VERSION "HNNBNNNYNNNNNNNNNNNNNNNNNNNNNNNNNNNNNNNNNN/4/%%%/4/'%**4NNN///"

NS_ :

BS_:

BU_: BAP_Tester ELV Gateway_Max HUD Kombi

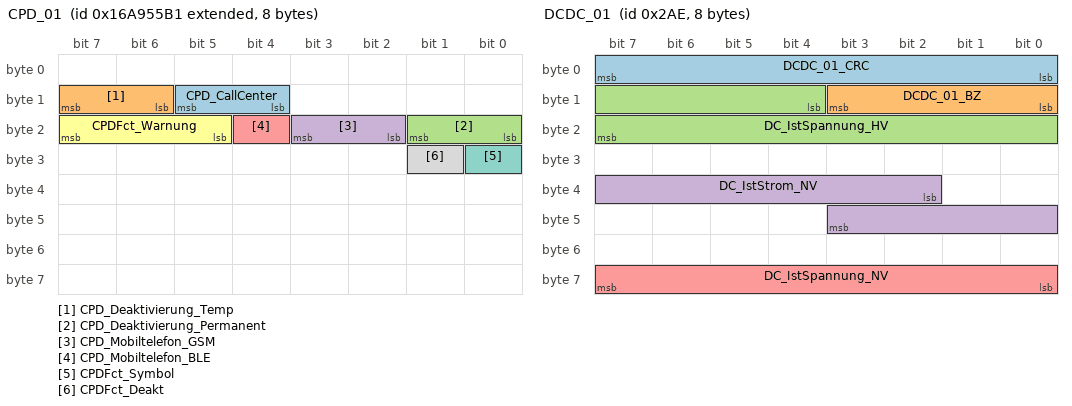
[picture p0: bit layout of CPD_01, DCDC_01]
BO_ 2527679921 CPD_01: 8 Gateway_Max
 SG_ CPD_CallCenter : 12|2@1+ (1.0,0.0) [0.0|3] ""  Vector__XXX
 SG_ CPD_Deaktivierung_Temp : 14|2@1+ (1.0,0.0) [0.0|3] ""  Vector__XXX
 SG_ CPD_Deaktivierung_Permanent : 16|2@1+ (1.0,0.0) [0.0|3] ""  Vector__XXX
 SG_ CPD_Mobiltelefon_GSM : 18|2@1+ (1.0,0.0) [0.0|3] ""  Vector__XXX
 SG_ CPD_Mobiltelefon_BLE : 20|1@1+ (1.0,0.0) [0.0|1] ""  Vector__XXX
 SG_ CPDFct_Warnung : 21|3@1+ (1.0,0.0) [0.0|7] ""  Kombi
 SG_ CPDFct_Symbol : 24|1@1+ (1.0,0.0) [0.0|1] ""  Kombi
 SG_ CPDFct_Deakt : 25|1@1+ (1.0,0.0) [0.0|1] ""  Vector__XXX

BO_ 918 Daempfer_01: 8 Gateway_Max
 SG_ DR_Gelbe_Warnlampe : 18|2@1+ (1.0,0.0) [0.0|3] ""  Kombi

BO_ 686 DCDC_01: 8 Gateway_Max
 SG_ DCDC_01_CRC : 0|8@1+ (1,0) [0|255] ""  Vector__XXX
 SG_ DCDC_01_BZ : 8|4@1+ (1,0) [0|15] ""  Vector__XXX
 SG_ DC_IstSpannung_HV : 12|12@1+ (0.25,0) [0.00|1023.25] "Unit_Volt"  Vector__XXX
 SG_ DC_IstStrom_NV : 34|10@1+ (1,-511) [-511|510] "Unit_Amper"  Vector__XXX
 SG_ DC_IstSpannung_NV : 56|8@1+ (0.1,0) [0.0|25.3] "Unit_Volt"  Vector__XXX

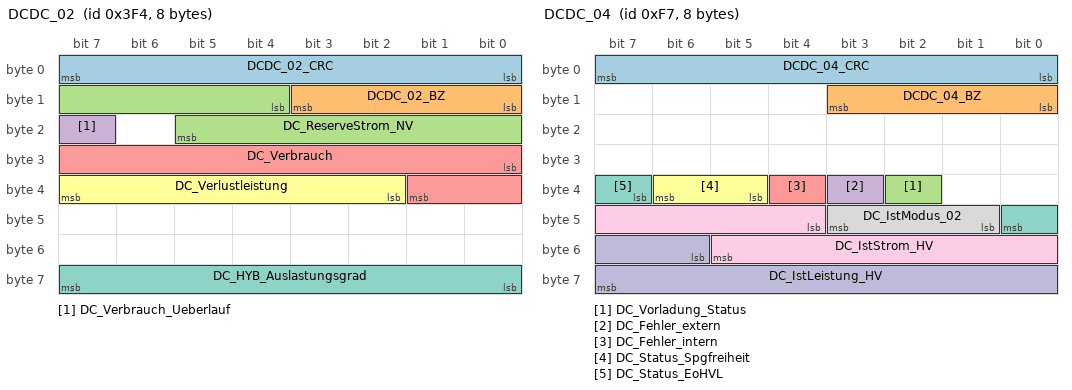
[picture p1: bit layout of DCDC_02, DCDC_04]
BO_ 1012 DCDC_02: 8 Gateway_Max
 SG_ DCDC_02_CRC : 0|8@1+ (1,0) [0|255] ""  Vector__XXX
 SG_ DCDC_02_BZ : 8|4@1+ (1,0) [0|15] ""  Vector__XXX
 SG_ DC_ReserveStrom_NV : 12|10@1+ (1,-511) [-511|510] "Unit_Amper"  Vector__XXX
 SG_ DC_Verbrauch_Ueberlauf : 23|1@1+ (1.0,0.0) [0.0|1] ""  Kombi
 SG_ DC_Verbrauch : 24|10@1+ (1,0) [0|1023] "Unit_WattSecond"  Kombi
 SG_ DC_Verlustleistung : 34|6@1+ (5,0) [0|305] "Unit_Watt"  Vector__XXX
 SG_ DC_HYB_Auslastungsgrad : 56|8@1+ (0.4,0) [0.0|100.0] "Unit_PerCent"  Vector__XXX

BO_ 247 DCDC_04: 8 Gateway_Max
 SG_ DCDC_04_CRC : 0|8@1+ (1,0) [0|255] ""  Vector__XXX
 SG_ DCDC_04_BZ : 8|4@1+ (1,0) [0|15] ""  Vector__XXX
 SG_ DC_Vorladung_Status : 34|1@1+ (1.0,0.0) [0.0|1] ""  Vector__XXX
 SG_ DC_Fehler_extern : 35|1@1+ (1.0,0.0) [0.0|1] ""  Vector__XXX
 SG_ DC_Fehler_intern : 36|1@1+ (1.0,0.0) [0.0|1] ""  Vector__XXX
 SG_ DC_Status_Spgfreiheit : 37|2@1+ (1.0,0.0) [0.0|3] ""  Vector__XXX
 SG_ DC_Status_EoHVL : 39|2@1+ (1.0,0.0) [0.0|3] ""  Vector__XXX
 SG_ DC_IstModus_02 : 41|3@1+ (1.0,0.0) [0.0|7] ""  Vector__XXX
 SG_ DC_IstStrom_HV : 44|10@1+ (0.1,-51.1) [-51.1|51.0] "Unit_Amper"  Vector__XXX
 SG_ DC_IstLeistung_HV : 54|10@1+ (10,-4000) [-4000|6210] "Unit_Watt"  Vector__XXX

BO_ 2583738904 DDA_AuthTime_Req: 8 Gateway_Max
 SG_ DDA_AuthTime_Req_Data : 0|64@1+ (1.0,0.0) [0.0|18446744073709551615] ""  Kombi

BO_ 2583869976 DDA_AuthTime_Resp: 8 Kombi
 SG_ DDA_AuthTime_Resp_Data : 0|64@1+ (1.0,0.0) [0.0|18446744073709551615] ""  Gateway_Max

BO_ 2617084421 DEV_ELV_Req_00: 8 Vector__XXX
 SG_ DEV_ELV_Req_00_Data : 0|64@1+ (1.0,0.0) [0.0|18446744073709551615] ""  ELV

BO_ 2617084427 DEV_ELV_Req_01: 8 Vector__XXX
 SG_ DEV_ELV_Req_01_Data : 0|64@1+ (1.0,0.0) [0.0|18446744073709551615] ""  ELV

BO_ 2617084416 DEV_ELV_Resp_00: 8 ELV
 SG_ DEV_ELV_Resp_00_Data : 0|64@1+ (1.0,0.0) [0.0|18446744073709551615] ""  Vector__XXX

BO_ 2617084417 DEV_ELV_Resp_01: 8 ELV
 SG_ DEV_ELV_Resp_01_Data : 0|64@1+ (1.0,0.0) [0.0|18446744073709551615] ""  Vector__XXX

BO_ 2617084418 DEV_ELV_Resp_02: 8 ELV
 SG_ DEV_ELV_Resp_02_Data : 0|64@1+ (1.0,0.0) [0.0|18446744073709551615] ""  Vector__XXX

BO_ 2617084419 DEV_ELV_Resp_03: 8 ELV
 SG_ DEV_ELV_Resp_03_Data : 0|64@1+ (1.0,0.0) [0.0|18446744073709551615] ""  Vector__XXX

BO_ 2617084420 DEV_ELV_Resp_04: 8 ELV
 SG_ DEV_ELV_Resp_04_Data : 0|64@1+ (1.0,0.0) [0.0|18446744073709551615] ""  Vector__XXX

BO_ 2617084422 DEV_ELV_Resp_05: 8 ELV
 SG_ DEV_ELV_Resp_05_Data : 0|64@1+ (1.0,0.0) [0.0|18446744073709551615] ""  Vector__XXX

BO_ 2617084423 DEV_ELV_Resp_06: 8 ELV
 SG_ DEV_ELV_Resp_06_Data : 0|64@1+ (1.0,0.0) [0.0|18446744073709551615] ""  Vector__XXX

BO_ 2617084424 DEV_ELV_Resp_07: 8 ELV
 SG_ DEV_ELV_Resp_07_Data : 0|64@1+ (1.0,0.0) [0.0|18446744073709551615] ""  Vector__XXX

BO_ 2617084425 DEV_ELV_Resp_08: 8 ELV
 SG_ DEV_ELV_Resp_08_Data : 0|64@1+ (1.0,0.0) [0.0|18446744073709551615] ""  Vector__XXX

BO_ 2617084426 DEV_ELV_Resp_09: 8 ELV
 SG_ DEV_ELV_Resp_09_Data : 0|64@1+ (1.0,0.0) [0.0|18446744073709551615] ""  Vector__XXX

BO_ 2617084428 DEV_ELV_Resp_10: 8 ELV
 SG_ DEV_ELV_Resp_10_Data : 0|64@1+ (1.0,0.0) [0.0|18446744073709551615] ""  Vector__XXX

BO_ 2617039369 DEV_HUD_Rx_09: 8 Vector__XXX
 SG_ DEV_HUD_Rx_09_Data : 0|64@1+ (1.0,0.0) [0.0|18446744073709551615] ""  HUD

BO_ 2617039370 DEV_HUD_Rx_10: 8 Vector__XXX
 SG_ DEV_HUD_Rx_10_Data : 0|64@1+ (1.0,0.0) [0.0|18446744073709551615] ""  HUD

BO_ 2617039371 DEV_HUD_Rx_11: 8 Vector__XXX
 SG_ DEV_HUD_Rx_11_Data : 0|64@1+ (1.0,0.0) [0.0|18446744073709551615] ""  HUD

BO_ 2617039372 DEV_HUD_Rx_12: 8 Vector__XXX
 SG_ DEV_HUD_Rx_12_Data : 0|64@1+ (1.0,0.0) [0.0|18446744073709551615] ""  HUD

BO_ 2617039375 DEV_HUD_Rx_15: 8 Vector__XXX
 SG_ DEV_HUD_Rx_15_Data : 0|64@1+ (1.0,0.0) [0.0|18446744073709551615] ""  HUD

BO_ 2617039361 DEV_HUD_Tx_01: 8 HUD
 SG_ DEV_HUD_Tx_01_Data : 0|64@1+ (1.0,0.0) [0.0|18446744073709551615] ""  Vector__XXX

BO_ 2617039362 DEV_HUD_Tx_02: 8 HUD
 SG_ DEV_HUD_Tx_02_Data : 0|64@1+ (1.0,0.0) [0.0|18446744073709551615] ""  Vector__XXX

BO_ 2617039363 DEV_HUD_Tx_03: 8 HUD
 SG_ DEV_HUD_Tx_03_Data : 0|64@1+ (1.0,0.0) [0.0|18446744073709551615] ""  Vector__XXX

BO_ 2617039364 DEV_HUD_Tx_04: 8 HUD
 SG_ DEV_HUD_Tx_04_Data : 0|64@1+ (1.0,0.0) [0.0|18446744073709551615] ""  Vector__XXX

BO_ 2617039365 DEV_HUD_Tx_05: 8 HUD
 SG_ DEV_HUD_Tx_05_Data : 0|64@1+ (1.0,0.0) [0.0|18446744073709551615] ""  Vector__XXX

BO_ 2617039366 DEV_HUD_Tx_06: 8 HUD
 SG_ DEV_HUD_Tx_06_Data : 0|64@1+ (1.0,0.0) [0.0|18446744073709551615] ""  Vector__XXX

BO_ 2617039367 DEV_HUD_Tx_07: 8 HUD
 SG_ DEV_HUD_Tx_07_Data : 0|64@1+ (1.0,0.0) [0.0|18446744073709551615] ""  Vector__XXX

BO_ 2617039368 DEV_HUD_Tx_08: 8 HUD
 SG_ DEV_HUD_Tx_08_Data : 0|64@1+ (1.0,0.0) [0.0|18446744073709551615] ""  Vector__XXX

BO_ 2617039373 DEV_HUD_Tx_13: 8 HUD
 SG_ DEV_HUD_Tx_13_Data : 0|64@1+ (1.0,0.0) [0.0|18446744073709551615] ""  Vector__XXX

BO_ 2617039374 DEV_HUD_Tx_14: 8 HUD
 SG_ DEV_HUD_Tx_14_Data : 0|64@1+ (1.0,0.0) [0.0|18446744073709551615] ""  Vector__XXX

BO_ 2617039376 DEV_HUD_Tx_16: 8 HUD
 SG_ DEV_HUD_Tx_16_Data : 0|64@1+ (1.0,0.0) [0.0|18446744073709551615] ""  Vector__XXX

BO_ 2549880335 DIA_ABT_2_Req: 8 Gateway_Max
 SG_ DIA_ABT_2_Req_Data : 0|64@1+ (1.0,0.0) [0.0|18446744073709551615] ""  Vector__XXX

BO_ 2550011407 DIA_ABT_2_Resp: 8 Vector__XXX
 SG_ DIA_ABT_2_Resp_Data : 0|64@1+ (1.0,0.0) [0.0|18446744073709551615] ""  Gateway_Max

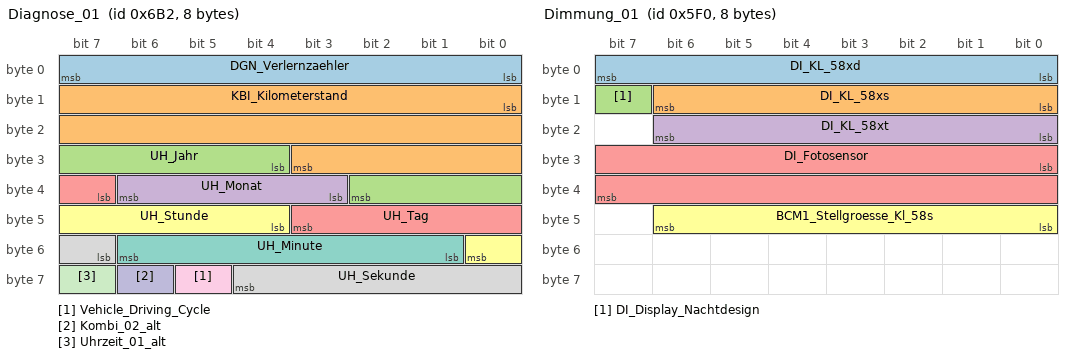
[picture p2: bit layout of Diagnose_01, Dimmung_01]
BO_ 1714 Diagnose_01: 8 Gateway_Max
 SG_ DGN_Verlernzaehler : 0|8@1+ (1,0) [0|254] ""  ELV,HUD,Kombi
 SG_ KBI_Kilometerstand : 8|20@1+ (1,0) [0|1048573] "Unit_KiloMeter"  ELV,HUD,Kombi
 SG_ UH_Jahr : 28|7@1+ (1,2000) [2000|2127] "Unit_Year"  ELV,HUD,Kombi
 SG_ UH_Monat : 35|4@1+ (1,0) [1|12] "Unit_Month"  ELV,HUD,Kombi
 SG_ UH_Tag : 39|5@1+ (1,0) [1|31] "Unit_Day"  ELV,HUD,Kombi
 SG_ UH_Stunde : 44|5@1+ (1,0) [0|23] "Unit_Hours"  ELV,HUD,Kombi
 SG_ UH_Minute : 49|6@1+ (1,0) [0|59] "Unit_Minut"  ELV,HUD,Kombi
 SG_ UH_Sekunde : 55|6@1+ (1,0) [0|59] "Unit_Secon"  ELV,HUD,Kombi
 SG_ Vehicle_Driving_Cycle : 61|1@1+ (1.0,0.0) [0.0|1] ""  Vector__XXX
 SG_ Kombi_02_alt : 62|1@1+ (1.0,0.0) [0.0|1] ""  Vector__XXX
 SG_ Uhrzeit_01_alt : 63|1@1+ (1.0,0.0) [0.0|1] ""  Vector__XXX

BO_ 1520 Dimmung_01: 8 Gateway_Max
 SG_ DI_KL_58xd : 0|8@1+ (1,0) [0|253] ""  Kombi
 SG_ DI_KL_58xs : 8|7@1+ (1,0) [0|100] "Unit_PerCent"  Kombi
 SG_ DI_Display_Nachtdesign : 15|1@1+ (1.0,0.0) [0.0|1] ""  HUD,Kombi
 SG_ DI_KL_58xt : 16|7@1+ (1,0) [0|100] "Unit_PerCent"  Kombi
 SG_ DI_Fotosensor : 24|16@1+ (1,0) [0|65535] ""  Vector__XXX
 SG_ BCM1_Stellgroesse_Kl_58s : 40|7@1+ (1,0) [0|100] ""  HUD

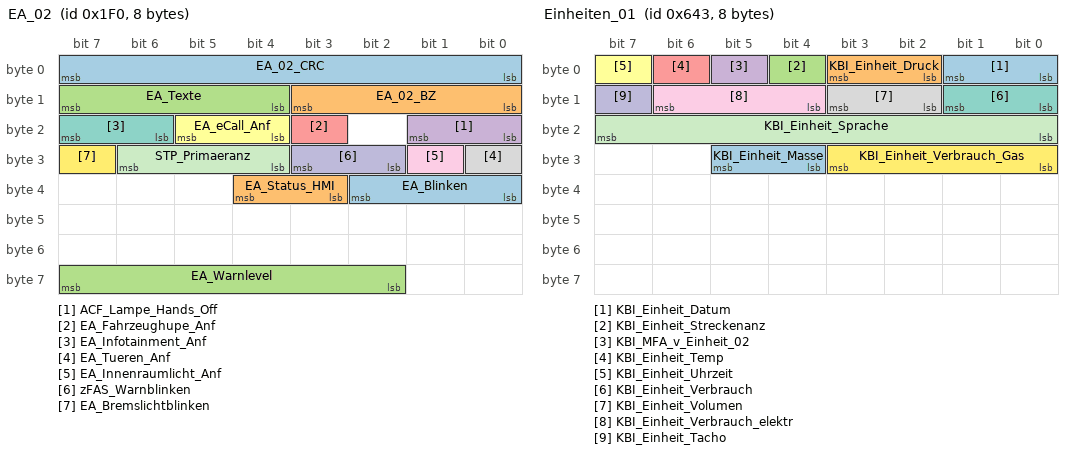
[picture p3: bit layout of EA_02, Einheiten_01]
BO_ 496 EA_02: 8 Gateway_Max
 SG_ EA_02_CRC : 0|8@1+ (1,0) [0|255] ""  Vector__XXX
 SG_ EA_02_BZ : 8|4@1+ (1,0) [0|15] ""  Vector__XXX
 SG_ EA_Texte : 12|4@1+ (1.0,0.0) [0.0|15] ""  HUD,Kombi
 SG_ ACF_Lampe_Hands_Off : 16|2@1+ (1.0,0.0) [0.0|3] ""  Vector__XXX
 SG_ EA_Fahrzeughupe_Anf : 19|1@1+ (1.0,0.0) [0.0|1] ""  Vector__XXX
 SG_ EA_eCall_Anf : 20|2@1+ (1.0,0.0) [0.0|3] ""  Vector__XXX
 SG_ EA_Infotainment_Anf : 22|2@1+ (1.0,0.0) [0.0|3] ""  Vector__XXX
 SG_ EA_Tueren_Anf : 24|1@1+ (1.0,0.0) [0.0|1] ""  Vector__XXX
 SG_ EA_Innenraumlicht_Anf : 25|1@1+ (1.0,0.0) [0.0|1] ""  Vector__XXX
 SG_ zFAS_Warnblinken : 26|2@1+ (1.0,0.0) [0.0|3] ""  Vector__XXX
 SG_ STP_Primaeranz : 28|3@1+ (1.0,0.0) [0.0|7] ""  Vector__XXX
 SG_ EA_Bremslichtblinken : 31|1@1+ (1.0,0.0) [0.0|1] ""  Vector__XXX
 SG_ EA_Blinken : 32|3@1+ (1.0,0.0) [0.0|7] ""  Vector__XXX
 SG_ EA_Status_HMI : 35|2@1+ (1.0,0.0) [0.0|3] ""  HUD,Kombi
 SG_ EA_Warnlevel : 58|6@1+ (1.0,0.0) [0.0|63] ""  Vector__XXX

BO_ 2583717656 eCall_AuthTime_Req: 8 Gateway_Max
 SG_ eCall_AuthTime_Req_Data : 0|64@1+ (1.0,0.0) [0.0|18446744073709551615] ""  Kombi

BO_ 2583848728 eCall_AuthTime_Resp: 8 Kombi
 SG_ eCall_AuthTime_Resp_Data : 0|64@1+ (1.0,0.0) [0.0|18446744073709551615] ""  Gateway_Max

BO_ 1603 Einheiten_01: 8 Kombi
 SG_ KBI_Einheit_Datum : 0|2@1+ (1.0,0.0) [0.0|3] ""  Gateway_Max
 SG_ KBI_Einheit_Druck : 2|2@1+ (1.0,0.0) [0.0|3] ""  Gateway_Max
 SG_ KBI_Einheit_Streckenanz : 4|1@1+ (1.0,0.0) [0.0|1] ""  Gateway_Max
 SG_ KBI_MFA_v_Einheit_02 : 5|1@1+ (1.0,0.0) [0.0|1] ""  Gateway_Max,HUD
 SG_ KBI_Einheit_Temp : 6|1@1+ (1.0,0.0) [0.0|1] ""  Gateway_Max,HUD
 SG_ KBI_Einheit_Uhrzeit : 7|1@1+ (1.0,0.0) [0.0|1] ""  Gateway_Max
 SG_ KBI_Einheit_Verbrauch : 8|2@1+ (1.0,0.0) [0.0|3] ""  Gateway_Max
 SG_ KBI_Einheit_Volumen : 10|2@1+ (1.0,0.0) [0.0|3] ""  Gateway_Max
 SG_ KBI_Einheit_Verbrauch_elektr : 12|3@1+ (1.0,0.0) [0.0|7] ""  Gateway_Max
 SG_ KBI_Einheit_Tacho : 15|1@1+ (1.0,0.0) [0.0|1] ""  Gateway_Max
 SG_ KBI_Einheit_Sprache : 16|8@1+ (1,0) [0|255] ""  Gateway_Max,HUD
 SG_ KBI_Einheit_Verbrauch_Gas : 24|4@1+ (1.0,0.0) [0.0|15] ""  Gateway_Max
 SG_ KBI_Einheit_Masse : 28|2@1+ (1.0,0.0) [0.0|3] ""  Gateway_Max

BO_ 1622 ELV_01: 8 ELV
 SG_ ELV_01_CRC : 0|8@1+ (1,0) [0|255] ""  Gateway_Max
 SG_ ELV_01_BZ : 8|4@1+ (1,0) [0|15] ""  Gateway_Max
 SG_ ELV_Anf_Klemme_S : 12|1@1+ (1.0,0.0) [0.0|1] ""  Gateway_Max
 SG_ ELV_Anf_Klemme_15 : 13|1@1+ (1.0,0.0) [0.0|1] ""  Gateway_Max
 SG_ ELV_Anf_Klemme_50 : 14|1@1+ (1.0,0.0) [0.0|1] ""  Gateway_Max
 SG_ ELV_01_Sendestatus : 15|1@1+ (1.0,0.0) [0.0|1] ""  Gateway_Max
 SG_ ELV_Verriegelt : 16|1@1+ (1.0,0.0) [0.0|1] ""  Gateway_Max,Kombi
 SG_ ELV_Entriegelt : 17|1@1+ (1.0,0.0) [0.0|1] ""  Gateway_Max,Kombi
 SG_ ELV_ZAT_betaetigt : 18|1@1+ (1.0,0.0) [0.0|1] ""  Gateway_Max
 SG_ ELV_Lebenszustand : 19|1@1+ (1.0,0.0) [0.0|1] ""  Gateway_Max
 SG_ ELV_Anlernmodus : 20|1@1+ (1.0,0.0) [0.0|1] ""  Gateway_Max
 SG_ KST_aut_Abschaltung_Zuendung : 21|1@1+ (1.0,0.0) [0.0|1] ""  Gateway_Max
 SG_ ELV_Klemmenfreigabe : 22|1@1+ (1.0,0.0) [0.0|1] ""  Gateway_Max
 SG_ ELV_Abbruch_Anf_Klemmenfreigabe : 23|1@1+ (1.0,0.0) [0.0|1] ""  Gateway_Max
 SG_ ELV_LED_Rot : 24|1@1+ (1.0,0.0) [0.0|1] ""  Gateway_Max,Kombi
 SG_ ELV_LED_Gelb : 25|1@1+ (1.0,0.0) [0.0|1] ""  Gateway_Max
 SG_ ELV_Txt_Panikabschaltung : 27|1@1+ (1.0,0.0) [0.0|1] ""  Gateway_Max
 SG_ ELV_Txt_Lkg_Bewegen : 28|1@1+ (1.0,0.0) [0.0|1] ""  Gateway_Max,Kombi
 SG_ ELV_Txt_Werkstatt : 29|1@1+ (1.0,0.0) [0.0|1] ""  Gateway_Max,Kombi
 SG_ ELV_Txt_Defekt : 30|1@1+ (1.0,0.0) [0.0|1] ""  Gateway_Max,Kombi
 SG_ ELV_Txt_P_Gang : 31|1@1+ (1.0,0.0) [0.0|1] ""  Gateway_Max
 SG_ ELV_Txt_PN_Gang : 32|1@1+ (1.0,0.0) [0.0|1] ""  Gateway_Max
 SG_ ELV_Txt_Kupplung : 33|1@1+ (1.0,0.0) [0.0|1] ""  Gateway_Max
 SG_ ELV_Txt_Bremse : 34|1@1+ (1.0,0.0) [0.0|1] ""  Gateway_Max
 SG_ ELV_P_verriegelt : 35|1@1+ (1.0,0.0) [0.0|1] ""  Gateway_Max
 SG_ KST_Txt_Komfortabschaltung : 36|1@1+ (1.0,0.0) [0.0|1] ""  Gateway_Max
 SG_ KST_Anf_ZV_Verriegelung : 37|1@1+ (1.0,0.0) [0.0|1] ""  Gateway_Max

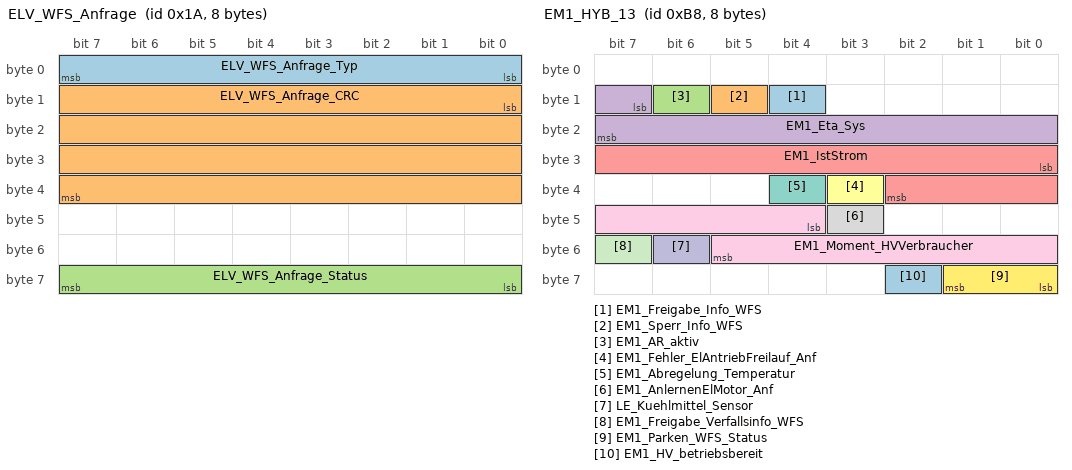
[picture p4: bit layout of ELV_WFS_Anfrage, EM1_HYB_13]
BO_ 26 ELV_WFS_Anfrage: 8 ELV
 SG_ ELV_WFS_Anfrage_Typ : 0|8@1+ (1.0,0.0) [0.0|255] ""  Gateway_Max
 SG_ ELV_WFS_Anfrage_CRC : 8|32@1+ (1.0,0.0) [0.0|4294967295] ""  Gateway_Max
 SG_ ELV_WFS_Anfrage_Status : 56|8@1+ (1.0,0.0) [0.0|255] ""  Gateway_Max

BO_ 184 EM1_HYB_13: 8 Gateway_Max
 SG_ EM1_Freigabe_Info_WFS : 12|1@1+ (1.0,0.0) [0.0|1] ""  Vector__XXX
 SG_ EM1_Sperr_Info_WFS : 13|1@1+ (1.0,0.0) [0.0|1] ""  Vector__XXX
 SG_ EM1_AR_aktiv : 14|1@1+ (1.0,0.0) [0.0|1] ""  Vector__XXX
 SG_ EM1_Eta_Sys : 15|9@1+ (0.2,0) [0.0|101.8] "Unit_PerCent"  Vector__XXX
 SG_ EM1_IstStrom : 24|11@1+ (1,-1023) [-1023|1022] "Unit_Amper"  Vector__XXX
 SG_ EM1_Fehler_ElAntriebFreilauf_Anf : 35|1@1+ (1.0,0.0) [0.0|1] ""  Vector__XXX
 SG_ EM1_Abregelung_Temperatur : 36|1@1+ (1.0,0.0) [0.0|1] ""  Vector__XXX
 SG_ EM1_AnlernenElMotor_Anf : 43|1@1+ (1.0,0.0) [0.0|1] ""  Vector__XXX
 SG_ EM1_Moment_HVVerbraucher : 44|10@1+ (1,-511) [-511|511] "Unit_NewtoMeter"  Vector__XXX
 SG_ LE_Kuehlmittel_Sensor : 54|1@1+ (1.0,0.0) [0.0|1] ""  Kombi
 SG_ EM1_Freigabe_Verfallsinfo_WFS : 55|1@1+ (1.0,0.0) [0.0|1] ""  Vector__XXX
 SG_ EM1_Parken_WFS_Status : 56|2@1+ (1.0,0.0) [0.0|3] ""  Vector__XXX
 SG_ EM1_HV_betriebsbereit : 58|1@1+ (1.0,0.0) [0.0|1] ""  Vector__XXX

BO_ 2589283970 Entfernung_02: 16 Gateway_Max
 SG_ DIST_DKmtg_Auth : 32|32@1+ (1,0) [0|4294967293] "Unit_Meter"  Kombi
 SG_ SOK_Entfernung_02_Signatur : 64|64@1+ (1,0) [0|18446744073709551615] "Unit_None"  Kombi

BO_ 2331595989 Entfernung_03: 8 Gateway_Max
 SG_ DIST_DKmtg : 32|32@1+ (1,0) [0|4294967293] "Unit_Meter"  Kombi

BO_ 2589283751 Entfernungen_01: 8 Gateway_Max
 SG_ KBI_Kilometerstand_Extended : 6|24@1+ (1,0) [0|16777213] "Unit_KiloMeter"  Kombi
 SG_ KBI_Kilometerstand_HiRes_meter : 30|34@1+ (1,0) [0|17179869183] "Unit_Meter"  Kombi

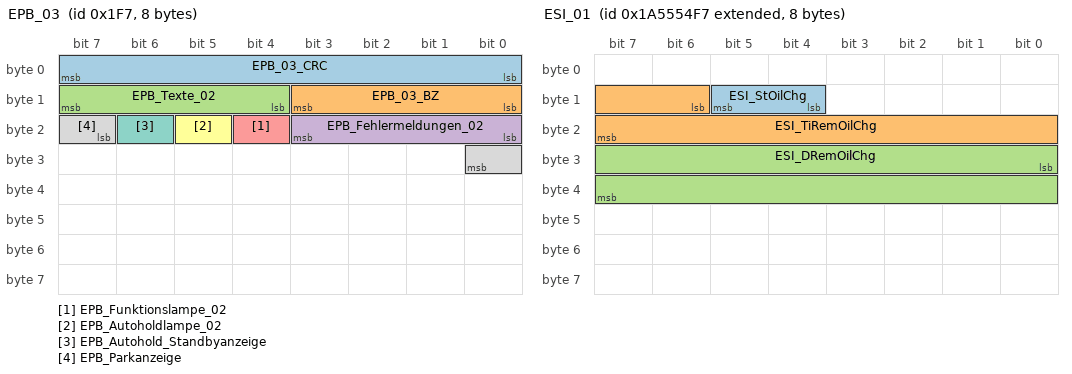
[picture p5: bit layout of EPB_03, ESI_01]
BO_ 503 EPB_03: 8 Gateway_Max
 SG_ EPB_03_CRC : 0|8@1+ (1,0) [0|255] ""  Kombi
 SG_ EPB_03_BZ : 8|4@1+ (1,0) [0|15] ""  Kombi
 SG_ EPB_Texte_02 : 12|4@1+ (1.0,0.0) [0.0|15] ""  Kombi
 SG_ EPB_Fehlermeldungen_02 : 16|4@1+ (1.0,0.0) [0.0|15] ""  Kombi
 SG_ EPB_Funktionslampe_02 : 20|1@1+ (1.0,0.0) [0.0|1] ""  Kombi
 SG_ EPB_Autoholdlampe_02 : 21|1@1+ (1.0,0.0) [0.0|1] ""  Kombi
 SG_ EPB_Autohold_Standbyanzeige : 22|1@1+ (1.0,0.0) [0.0|1] ""  Kombi
 SG_ EPB_Parkanzeige : 23|2@1+ (1.0,0.0) [0.0|3] ""  Vector__XXX

BO_ 258 ESC_50: 48 Gateway_Max
 SG_ ESC_50_CRC : 0|8@1+ (1,0) [0|255] ""  Vector__XXX
 SG_ ESC_50_BZ : 8|4@1+ (1,0) [0|15] ""  Vector__XXX
 SG_ ESP_QBit_Gierrate : 12|1@1+ (1.0,0.0) [0.0|1] ""  Vector__XXX
 SG_ ESP_QBit_Laengsbeschl : 13|1@1+ (1.0,0.0) [0.0|1] ""  Kombi
 SG_ ESP_QBit_Querb : 14|1@1+ (1.0,0.0) [0.0|1] ""  Kombi
 SG_ ESP_Querbeschleunigung : 16|8@1+ (0.01,-1.27) [-1.27|1.27] "Unit_ForceOfGravi"  Kombi
 SG_ ESP_Laengsbeschl : 24|10@1+ (0.03125,-16) [-16.00000|15.90625] "Unit_MeterPerSeconSquar"  Kombi
 SG_ ESC_Motorstartverzoegerung : 34|1@1+ (1.0,0.0) [0.0|1] ""  Vector__XXX
 SG_ ESC_SeitenwindAssistent_Eingriff : 35|1@1+ (1.0,0.0) [0.0|1] ""  Vector__XXX
 SG_ ESP_Anschleppstart_Freigabe : 36|2@1+ (1.0,0.0) [0.0|3] ""  Vector__XXX
 SG_ ESC_Unterdruckmangel_erkannt : 38|1@1+ (1.0,0.0) [0.0|1] ""  Vector__XXX
 SG_ ESP_Gierrate : 40|14@1+ (0.01,0) [0.00|163.82] "Unit_DegreOfArcPerSecon"  Vector__XXX
 SG_ ESP_VZ_Gierrate : 54|1@1+ (1.0,0.0) [0.0|1] ""  Vector__XXX
 SG_ ESP_Notbremsanzeige : 55|1@1+ (1.0,0.0) [0.0|1] ""  Vector__XXX
 SG_ ESP_SpannungsAnf : 56|1@1+ (1.0,0.0) [0.0|1] ""  Vector__XXX
 SG_ ESP_PLA_Abbruch : 57|3@1+ (1.0,0.0) [0.0|7] ""  Vector__XXX
 SG_ ESP_Status_ESP_PLA : 60|4@1+ (1.0,0.0) [0.0|15] ""  Vector__XXX
 SG_ ESP_QBit_Bremsdruck : 76|1@1+ (1.0,0.0) [0.0|1] ""  Vector__XXX
 SG_ ESP_QBit_Fahrer_bremst : 77|1@1+ (1.0,0.0) [0.0|1] ""  Vector__XXX
 SG_ ESP_Schwelle_Unterdruck : 78|2@1+ (1.0,0.0) [0.0|3] ""  Vector__XXX
 SG_ ESP_Bremsdruck : 80|10@1+ (0.3,-30) [-30.0|276.6] "Unit_Bar"  Vector__XXX
 SG_ ESP_Fahrer_bremst : 90|1@1+ (1.0,0.0) [0.0|1] ""  Vector__XXX
 SG_ ESP_Verz_TSK_aktiv : 91|1@1+ (1.0,0.0) [0.0|1] ""  Vector__XXX
 SG_ ESP_Lenkeingriff_ADS : 92|1@1+ (1.0,0.0) [0.0|1] ""  Vector__XXX
 SG_ ESP_Konsistenz_TSK : 93|1@1+ (1.0,0.0) [0.0|1] ""  Vector__XXX
 SG_ ESP_Bremsruck_AWV2 : 94|1@1+ (1.0,0.0) [0.0|1] ""  Vector__XXX
 SG_ ESP_Konsistenz_AWV2 : 95|1@1+ (1.0,0.0) [0.0|1] ""  Vector__XXX
 SG_ ECD_Fehler : 96|1@1+ (1.0,0.0) [0.0|1] ""  Vector__XXX
 SG_ ECD_nicht_verfuegbar : 97|1@1+ (1.0,0.0) [0.0|1] ""  Vector__XXX
 SG_ ESP_Status_Bremsentemp : 98|1@1+ (1.0,0.0) [0.0|1] ""  Vector__XXX
 SG_ ESP_Autohold_Standby : 99|1@1+ (1.0,0.0) [0.0|1] ""  Vector__XXX
 SG_ ESP_HDC_Standby : 100|1@1+ (1.0,0.0) [0.0|1] ""  Vector__XXX
 SG_ ESP_HBA_aktiv : 101|1@1+ (1.0,0.0) [0.0|1] ""  Vector__XXX
 SG_ ESP_Prefill_ausgeloest : 102|1@1+ (1.0,0.0) [0.0|1] ""  Vector__XXX
 SG_ ESP_Rueckwaertsfahrt_erkannt : 103|1@1+ (1.0,0.0) [0.0|1] ""  Vector__XXX
 SG_ ESP_Status_Anfahrhilfe : 104|1@1+ (1.0,0.0) [0.0|1] ""  Vector__XXX
 SG_ ESP_HDC_aktiv : 105|1@1+ (1.0,0.0) [0.0|1] ""  Vector__XXX
 SG_ ESP_StartStopp_Info : 106|2@1+ (1.0,0.0) [0.0|3] ""  Vector__XXX
 SG_ ESP_Eingr_HL : 108|1@1+ (1.0,0.0) [0.0|1] ""  Vector__XXX
 SG_ ESP_Eingr_HR : 109|1@1+ (1.0,0.0) [0.0|1] ""  Vector__XXX
 SG_ ESP_Eingr_VL : 110|1@1+ (1.0,0.0) [0.0|1] ""  Vector__XXX
 SG_ ESP_Eingr_VR : 111|1@1+ (1.0,0.0) [0.0|1] ""  Vector__XXX
 SG_ ESP_BKV_Unterdruck : 112|8@1+ (4,0) [4|1012] "Unit_MilliBar"  Vector__XXX
 SG_ ESP_Autohold_aktiv : 120|1@1+ (1.0,0.0) [0.0|1] ""  Vector__XXX
 SG_ ESP_FStatus_Anfahrhilfe : 121|1@1+ (1.0,0.0) [0.0|1] ""  Vector__XXX
 SG_ ESP_Verz_EPB_aktiv : 122|1@1+ (1.0,0.0) [0.0|1] ""  Vector__XXX
 SG_ ECD_Bremslicht : 123|1@1+ (1.0,0.0) [0.0|1] ""  Vector__XXX
 SG_ ESP_Verzoeg_EPB_verf : 124|1@1+ (1.0,0.0) [0.0|1] ""  Vector__XXX
 SG_ ESP_Status_Bremsdruck : 125|1@1+ (1.0,0.0) [0.0|1] ""  Vector__XXX
 SG_ ESP_Anforderung_EPB : 126|2@1+ (1.0,0.0) [0.0|3] ""  Vector__XXX
 SG_ ESC_Fahrerradbremswunschmoment : 128|12@1+ (6,-2400) [-2400|22158] "Unit_NewtoMeter"  Vector__XXX
 SG_ ESP_ANB_CM_Rueckk_Umsetz : 140|1@1+ (1.0,0.0) [0.0|1] ""  Vector__XXX
 SG_ ESP_Konsistenz_ACC_Botschaft : 141|1@1+ (1.0,0.0) [0.0|1] ""  Vector__XXX
 SG_ ESP_Stillstandsphase_erschoepft : 142|1@1+ (1.0,0.0) [0.0|1] ""  Vector__XXX
 SG_ ESP_ZT_Rueckk_Umsetz : 143|1@1+ (1.0,0.0) [0.0|1] ""  Vector__XXX
 SG_ ESP_Tuerkontakt_Fahrertuer : 144|1@1+ (1.0,0.0) [0.0|1] ""  Vector__XXX
 SG_ ESP_Abrutschen_Stillstand : 146|1@1+ (1.0,0.0) [0.0|1] ""  Vector__XXX
 SG_ ESP_Fahrer_tritt_ZBR_Schw : 147|1@1+ (1.0,0.0) [0.0|1] ""  Vector__XXX
 SG_ ESP_Systemstatus_03 : 148|2@1+ (1.0,0.0) [0.0|3] ""  Vector__XXX
 SG_ ASR_Systemstatus : 150|2@1+ (1.0,0.0) [0.0|3] ""  Vector__XXX
 SG_ ESP_QBit_v_ref : 169|1@1+ (1.0,0.0) [0.0|1] ""  Vector__XXX
 SG_ ESP_v_ref_Fahrtrichtung : 170|2@1+ (1.0,0.0) [0.0|3] ""  Vector__XXX
 SG_ ESC_Bremsdruckgradient : 172|8@1+ (10,0) [0|2500] "Unit_BarPerSecon"  Vector__XXX
 SG_ ESP_v_ref : 180|12@1+ (0.125,0) [0.000|511.500] "Unit_KiloMeterPerHour"  Vector__XXX
 SG_ ESP_HBA_Empfindlichkeit : 220|3@1+ (1.0,0.0) [0.0|7] ""  Vector__XXX
 SG_ ESC_Hydr_Fkt_aktiv : 223|2@1+ (1.0,0.0) [0.0|3] ""  Vector__XXX
 SG_ ESC_QBit_Fahrerbremswunsch : 225|1@1+ (1.0,0.0) [0.0|1] ""  Vector__XXX
 SG_ ESC_Fahrerbremswunsch : 226|10@1+ (0.3,-30) [-30.0|276.6] "Unit_Bar"  Vector__XXX
 SG_ ESCGeneratorSollMoment : 236|12@1+ (3,-12279) [-12279|0] ""  Vector__XXX
 SG_ ESC_Raddruck_max : 248|8@1+ (1,0) [0|250] "Unit_Bar"  Vector__XXX
 SG_ EPB_QBit_Pedalweg_Kuppl : 269|1@1+ (1.0,0.0) [0.0|1] ""  Vector__XXX
 SG_ EPB_Freig_Verzoeg_Anf : 271|1@1+ (1.0,0.0) [0.0|1] ""  Vector__XXX
 SG_ EPB_Verzoeg_Anf : 272|8@1+ (0.048,-7.968) [-7.968|4.224] "Unit_MeterPerSeconSquar"  Vector__XXX
 SG_ EPB_Pedalweg_Kuppl : 288|8@1+ (0.4,0) [8.0|92.0] "Unit_PerCent"  Vector__XXX
 SG_ EPB_DAA_Randbed_erf : 305|1@1+ (1.0,0.0) [0.0|1] ""  Vector__XXX
 SG_ EPB_Fehlerstatus_02 : 306|2@1+ (1.0,0.0) [0.0|3] ""  Vector__XXX
 SG_ EPB_Schalterposition : 308|2@1+ (1.0,0.0) [0.0|3] ""  Vector__XXX
 SG_ EPB_QBit_Schalterpos : 310|1@1+ (1.0,0.0) [0.0|1] ""  Vector__XXX
 SG_ EPB_Spannkraft : 312|5@1+ (1,0) [0|29] "Unit_KiloNewto"  Vector__XXX
 SG_ EPB_Status_02 : 317|3@1+ (1.0,0.0) [0.0|7] ""  Vector__XXX
 SG_ EPB_Status : 320|2@1+ (1.0,0.0) [0.0|3] ""  Vector__XXX
 SG_ ESP_Status_Bremsentemp_02 : 322|2@1+ (1.0,0.0) [0.0|3] ""  Vector__XXX
 SG_ SOK_ESC_50_Signatur : 352|32@1+ (1,0) [0|4294967295] ""  Vector__XXX

BO_ 885 ESC_54: 32 Gateway_Max
 SG_ ESC_54_BZ : 8|4@1+ (1,0) [0|15] ""  Kombi
 SG_ SSO_EdgeCount_Sum : 16|32@1+ (1,0) [0|4294967293] "Unit_None"  Kombi
 SG_ SOK_ESC_54_Signatur : 208|48@1+ (1,0) [0|281474976710655] "Unit_None"  Kombi

BO_ 2589283575 ESI_01: 8 Kombi
 SG_ ESI_StOilChg : 12|2@1+ (1.0,0.0) [0.0|3] ""  Gateway_Max
 SG_ ESI_TiRemOilChg : 14|10@1+ (1,0) [0|1021] "Unit_Day"  Gateway_Max
 SG_ ESI_DRemOilChg : 24|16@1+ (1,0) [0|65533] "Unit_KiloMeter"  Gateway_Max

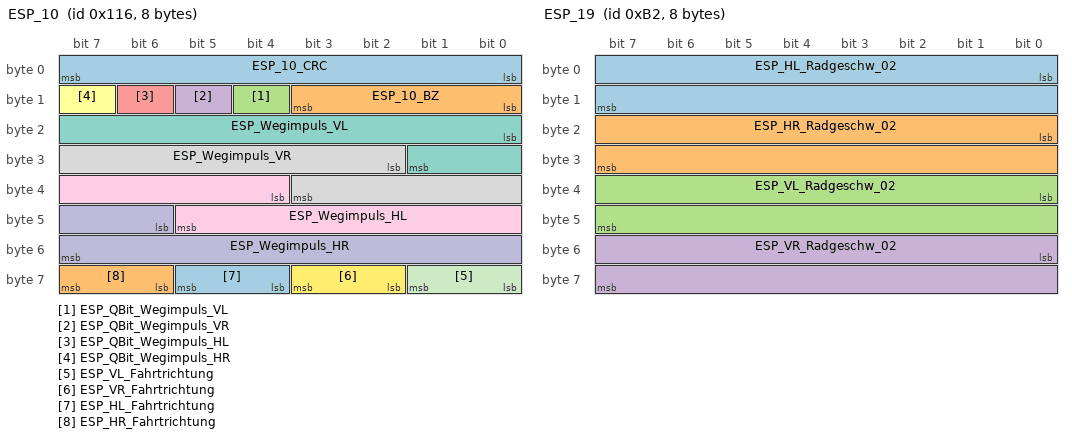
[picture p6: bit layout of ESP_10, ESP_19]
BO_ 278 ESP_10: 8 Gateway_Max
 SG_ ESP_10_CRC : 0|8@1+ (1,0) [0|255] ""  ELV
 SG_ ESP_10_BZ : 8|4@1+ (1,0) [0|15] ""  ELV
 SG_ ESP_QBit_Wegimpuls_VL : 12|1@1+ (1.0,0.0) [0.0|1] ""  ELV
 SG_ ESP_QBit_Wegimpuls_VR : 13|1@1+ (1.0,0.0) [0.0|1] ""  ELV
 SG_ ESP_QBit_Wegimpuls_HL : 14|1@1+ (1.0,0.0) [0.0|1] ""  ELV
 SG_ ESP_QBit_Wegimpuls_HR : 15|1@1+ (1.0,0.0) [0.0|1] ""  ELV
 SG_ ESP_Wegimpuls_VL : 16|10@1+ (1,0) [0|1000] ""  ELV
 SG_ ESP_Wegimpuls_VR : 26|10@1+ (1,0) [0|1000] ""  ELV
 SG_ ESP_Wegimpuls_HL : 36|10@1+ (1,0) [0|1000] ""  ELV
 SG_ ESP_Wegimpuls_HR : 46|10@1+ (1,0) [0|1000] ""  ELV
 SG_ ESP_VL_Fahrtrichtung : 56|2@1+ (1.0,0.0) [0.0|3] ""  Vector__XXX
 SG_ ESP_VR_Fahrtrichtung : 58|2@1+ (1.0,0.0) [0.0|3] ""  Vector__XXX
 SG_ ESP_HL_Fahrtrichtung : 60|2@1+ (1.0,0.0) [0.0|3] ""  Vector__XXX
 SG_ ESP_HR_Fahrtrichtung : 62|2@1+ (1.0,0.0) [0.0|3] ""  Vector__XXX

BO_ 178 ESP_19: 8 Gateway_Max
 SG_ ESP_HL_Radgeschw_02 : 0|16@1+ (0.0075,0) [0.0000|491.4900] "Unit_KiloMeterPerHour"  Vector__XXX
 SG_ ESP_HR_Radgeschw_02 : 16|16@1+ (0.0075,0) [0.0000|491.4900] "Unit_KiloMeterPerHour"  Vector__XXX
 SG_ ESP_VL_Radgeschw_02 : 32|16@1+ (0.0075,0) [0.0000|491.4900] "Unit_KiloMeterPerHour"  Vector__XXX
 SG_ ESP_VR_Radgeschw_02 : 48|16@1+ (0.0075,0) [0.0000|491.4900] "Unit_KiloMeterPerHour"  Vector__XXX

BO_ 1629 ESP_20: 8 Gateway_Max
 SG_ ESP_20_CRC : 0|8@1+ (1,0) [0|255] ""  Vector__XXX
 SG_ ESP_20_BZ : 8|4@1+ (1,0) [0|15] ""  Vector__XXX
 SG_ BR_Systemart : 12|2@1+ (1.0,0.0) [0.0|3] ""  Kombi
 SG_ ESP_SpannungsAnf_02 : 14|2@1+ (1.0,0.0) [0.0|3] ""  Vector__XXX
 SG_ ESP_Zaehnezahl : 16|8@1+ (1,0) [0|255] ""  Kombi
 SG_ ESP_Charisma_FahrPr : 24|4@1+ (1.0,0.0) [0.0|15] ""  Vector__XXX
 SG_ ESP_Charisma_Status : 28|2@1+ (1.0,0.0) [0.0|3] ""  Vector__XXX
 SG_ ESP_Wiederstart_Anz_01 : 30|1@1+ (1.0,0.0) [0.0|1] ""  Vector__XXX
 SG_ ESP_Wiederstart_Anz_02 : 31|1@1+ (1.0,0.0) [0.0|1] ""  Vector__XXX
 SG_ ESP_Wiederstart_Anz_03 : 32|1@1+ (1.0,0.0) [0.0|1] ""  Vector__XXX
 SG_ ESP_Wiederstart_Anz_04 : 33|1@1+ (1.0,0.0) [0.0|1] ""  Vector__XXX
 SG_ ESP_Stoppverbot_Anz_01 : 34|1@1+ (1.0,0.0) [0.0|1] ""  Vector__XXX
 SG_ ESP_Stoppverbot_Anz_02 : 35|1@1+ (1.0,0.0) [0.0|1] ""  Vector__XXX
 SG_ ESP_Stoppverbot_Anz_03 : 36|1@1+ (1.0,0.0) [0.0|1] ""  Vector__XXX
 SG_ ESP_Stoppverbot_Anz_04 : 37|1@1+ (1.0,0.0) [0.0|1] ""  Vector__XXX
 SG_ ESP_Stoppverbot_Anz_05 : 38|1@1+ (1.0,0.0) [0.0|1] ""  Vector__XXX
 SG_ ESP_Stoppverbot_Anz_06 : 39|1@1+ (1.0,0.0) [0.0|1] ""  Vector__XXX
 SG_ ESP_Stoppverbot_Anz_07 : 40|1@1+ (1.0,0.0) [0.0|1] ""  Vector__XXX
 SG_ ESP_Stoppverbot_Anz_Std : 41|1@1+ (1.0,0.0) [0.0|1] ""  Vector__XXX
 SG_ ESP_Dachrelingsensor : 42|2@1+ (1.0,0.0) [0.0|3] ""  Vector__XXX
 SG_ ESP_Stoppverbot_Anz_08 : 44|1@1+ (1.0,0.0) [0.0|1] ""  Vector__XXX
 SG_ HDC_Charisma_FahrPr : 45|4@1+ (1.0,0.0) [0.0|15] ""  Vector__XXX
 SG_ HDC_Charisma_Status : 49|2@1+ (1.0,0.0) [0.0|3] ""  Vector__XXX
 SG_ BR_QBit_Reifenumfang : 51|1@1+ (1.0,0.0) [0.0|1] ""  Vector__XXX
 SG_ BR_Reifenumfang : 52|12@1+ (1,0) [0|4095] "Unit_MilliMeter"  Vector__XXX

BO_ 253 ESP_21: 8 Gateway_Max
 SG_ ESP_21_CRC : 0|8@1+ (1,0) [0|255] ""  ELV
 SG_ ESP_21_BZ : 8|4@1+ (1,0) [0|15] ""  ELV
 SG_ BR_Eingriffsmoment : 12|10@1+ (1,-509) [-509|509] ""  Vector__XXX
 SG_ ESP_PLA_Bremseingriff : 22|1@1+ (1.0,0.0) [0.0|1] ""  Vector__XXX
 SG_ ESP_Diagnose : 23|1@1+ (1.0,0.0) [0.0|1] ""  Vector__XXX
 SG_ ESC_Reku_Freigabe : 24|1@1+ (1.0,0.0) [0.0|1] ""  Vector__XXX
 SG_ ESC_v_Signal_Qualifier_High_Low : 25|3@1+ (1.0,0.0) [0.0|7] ""  Vector__XXX
 SG_ ESP_Vorsteuerung : 28|1@1+ (1.0,0.0) [0.0|1] ""  Vector__XXX
 SG_ ESP_AWV3_Brems_aktiv : 29|1@1+ (1.0,0.0) [0.0|1] ""  Vector__XXX
 SG_ OBD_Schlechtweg : 30|1@1+ (1.0,0.0) [0.0|1] ""  Vector__XXX
 SG_ OBD_QBit_Schlechtweg : 31|1@1+ (1.0,0.0) [0.0|1] ""  Vector__XXX
 SG_ ESP_v_Signal : 32|16@1+ (0.01,0) [0.00|655.32] "Unit_KiloMeterPerHour"  ELV
 SG_ ASR_Tastung_passiv : 48|1@1+ (1.0,0.0) [0.0|1] ""  Vector__XXX
 SG_ ESP_Tastung_passiv : 49|1@1+ (1.0,0.0) [0.0|1] ""  Vector__XXX
 SG_ ESP_Systemstatus : 50|1@1+ (1.0,0.0) [0.0|1] ""  Vector__XXX
 SG_ ASR_Schalteingriff : 51|2@1+ (1.0,0.0) [0.0|3] ""  Vector__XXX
 SG_ ESP_Haltebestaetigung : 53|1@1+ (1.0,0.0) [0.0|1] ""  Vector__XXX
 SG_ ESP_MKB_Abbruch_Geschw : 54|1@1+ (1.0,0.0) [0.0|1] ""  Vector__XXX
 SG_ ESP_QBit_v_Signal : 55|1@1+ (1.0,0.0) [0.0|1] ""  ELV
 SG_ ABS_Bremsung : 56|1@1+ (1.0,0.0) [0.0|1] ""  Vector__XXX
 SG_ ASR_Anf : 57|1@1+ (1.0,0.0) [0.0|1] ""  Vector__XXX
 SG_ MSR_Anf : 58|1@1+ (1.0,0.0) [0.0|1] ""  Vector__XXX
 SG_ EBV_Eingriff : 59|1@1+ (1.0,0.0) [0.0|1] ""  Vector__XXX
 SG_ EDS_Eingriff : 60|1@1+ (1.0,0.0) [0.0|1] ""  Vector__XXX
 SG_ ESP_Eingriff : 61|1@1+ (1.0,0.0) [0.0|1] ""  Vector__XXX
 SG_ ESP_ASP : 62|1@1+ (1.0,0.0) [0.0|1] ""  Vector__XXX
 SG_ ESP_Anhaltevorgang_ACC_aktiv : 63|1@1+ (1.0,0.0) [0.0|1] ""  Vector__XXX

BO_ 795 ESP_24: 8 Gateway_Max
 SG_ ESP_24_CRC : 0|8@1+ (1,0) [0|255] ""  Kombi
 SG_ ESP_24_BZ : 8|4@1+ (1,0) [0|15] ""  Kombi
 SG_ ESP_Lampe : 12|1@1+ (1.0,0.0) [0.0|1] ""  Kombi
 SG_ ABS_Lampe : 13|1@1+ (1.0,0.0) [0.0|1] ""  Kombi
 SG_ BK_Lampe_02 : 14|2@1+ (1.0,0.0) [0.0|3] ""  Kombi
 SG_ TC_Lampe : 16|1@1+ (1.0,0.0) [0.0|1] ""  Vector__XXX
 SG_ ESP_m_Raddrehz : 17|15@1+ (0.002,0) [0.000|65.278] "Unit_Hertz"  Kombi
 SG_ ESP_Textanzeigen_03 : 32|5@1+ (1.0,0.0) [0.0|31] ""  Kombi
 SG_ ESP_Meldungen : 37|3@1+ (1.0,0.0) [0.0|7] ""  Kombi
 SG_ ESP_Wegimp_VA : 40|11@1+ (1,0) [0|2047] ""  Kombi
 SG_ ESP_Fehlerstatus_Wegimp : 51|1@1+ (1.0,0.0) [0.0|1] ""  Vector__XXX
 SG_ ESP_Wegimp_Ueberlauf : 52|1@1+ (1.0,0.0) [0.0|1] ""  Kombi
 SG_ ESP_QBit_Wegimp_VA : 53|1@1+ (1.0,0.0) [0.0|1] ""  Vector__XXX
 SG_ ESP_HDC_FktLampe : 54|1@1+ (1.0,0.0) [0.0|1] ""  Vector__XXX
 SG_ ESP_Off_Lampe : 55|1@1+ (1.0,0.0) [0.0|1] ""  Kombi
 SG_ ESP_HDC_Regelgeschw : 56|7@1+ (0.32,0) [0.32|39.68] "Unit_KiloMeterPerHour"  HUD,Kombi
 SG_ ESP_BKV_Warnung : 63|1@1+ (1.0,0.0) [0.0|1] ""  Kombi

BO_ 2589283617 ESP_30: 8 Gateway_Max
 SG_ ESP_30_CRC : 0|8@1+ (1,0) [0|255] ""  Kombi
 SG_ ESP_30_BZ : 8|4@1+ (1,0) [0|15] ""  Kombi
 SG_ EDS_Charisma_FahrPr : 12|4@1+ (1.0,0.0) [0.0|15] ""  Vector__XXX
 SG_ EDS_Charisma_Status : 16|2@1+ (1.0,0.0) [0.0|3] ""  Vector__XXX
 SG_ HHC_Charisma_Status : 18|2@1+ (1.0,0.0) [0.0|3] ""  Vector__XXX
 SG_ HHC_Charisma_FahrPr : 20|4@1+ (1.0,0.0) [0.0|15] ""  Vector__XXX
 SG_ RLE_Anzeigen : 24|3@1+ (1.0,0.0) [0.0|7] ""  Kombi
 SG_ ESC_Lernfreigabe_Abrollumfang : 27|1@1+ (1.0,0.0) [0.0|1] ""  Kombi
 SG_ ESC_Texte_eBKV_Betaetigung : 28|4@1+ (1.0,0.0) [0.0|15] ""  Vector__XXX
 SG_ ESC_MBK_Meldungen : 32|2@1+ (1.0,0.0) [0.0|3] ""  Vector__XXX
 SG_ ESC_Anf_KL : 34|5@1+ (3.22580645,0) [0E-8|99.99999995] "Unit_PerCent"  Vector__XXX
 SG_ ESC_Anf_KV : 39|1@1+ (1.0,0.0) [0.0|1] ""  Vector__XXX
 SG_ ESC_FBA_Meldungen : 40|2@1+ (1.0,0.0) [0.0|3] ""  Kombi
 SG_ DBK_Fahrerwarnung : 42|2@1+ (1.0,0.0) [0.0|3] ""  Kombi
 SG_ ESP_Status_Bremsentemp_Anz : 44|3@1+ (1.0,0.0) [0.0|7] ""  Vector__XXX
 SG_ ESP_Off_Anf_KBI : 47|1@1+ (1.0,0.0) [0.0|1] ""  Kombi
 SG_ FBC_Fahrerwarnung : 48|2@1+ (1.0,0.0) [0.0|3] ""  Kombi

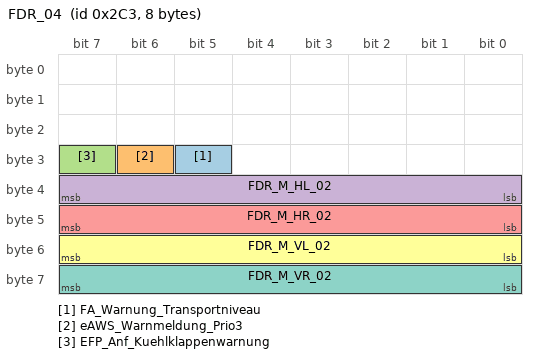
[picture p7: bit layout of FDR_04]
BO_ 707 FDR_04: 8 Gateway_Max
 SG_ FA_Warnung_Transportniveau : 29|1@1+ (1.0,0.0) [0.0|1] ""  Vector__XXX
 SG_ eAWS_Warnmeldung_Prio3 : 30|1@1+ (1.0,0.0) [0.0|1] ""  Vector__XXX
 SG_ EFP_Anf_Kuehlklappenwarnung : 31|1@1+ (1.0,0.0) [0.0|1] ""  Vector__XXX
 SG_ FDR_M_HL_02 : 32|8@1+ (1,-100) [-100|100] "Unit_PerCent"  Kombi
 SG_ FDR_M_HR_02 : 40|8@1+ (1,-100) [-100|100] "Unit_PerCent"  Kombi
 SG_ FDR_M_VL_02 : 48|8@1+ (1,-100) [-100|100] "Unit_PerCent"  Kombi
 SG_ FDR_M_VR_02 : 56|8@1+ (1,-100) [-100|100] "Unit_PerCent"  Kombi

BO_ 2589283684 FoD_01: 8 Gateway_Max
 SG_ GRA_FoD_Status : 58|2@1+ (1.0,0.0) [0.0|3] ""  Vector__XXX
 SG_ FoD_Transmission_Info : 60|2@1+ (1.0,0.0) [0.0|3] ""  Vector__XXX

BO_ 2549875476 FoD_Kombi_Req: 8 Gateway_Max
 SG_ FoD_Kombi_Req_Data : 0|64@1+ (1.0,0.0) [0.0|18446744073709551615] ""  Kombi

BO_ 2550006548 FoD_Kombi_Resp: 8 Kombi
 SG_ FoD_Kombi_Resp_Data : 0|64@1+ (1.0,0.0) [0.0|18446744073709551615] ""  Gateway_Max

BO_ 2549875500 FoD_MFG_Req: 8 Gateway_Max
 SG_ FoD_MFG_Req_Data : 0|64@1+ (1.0,0.0) [0.0|18446744073709551615] ""  Vector__XXX

BO_ 2550006572 FoD_MFG_Resp: 8 Vector__XXX
 SG_ FoD_MFG_Resp_Data : 0|64@1+ (1.0,0.0) [0.0|18446744073709551615] ""  Gateway_Max

BO_ 986 Gateway_71: 8 Gateway_Max
 SG_ ESP_05_alt : 0|1@1+ (1.0,0.0) [0.0|1] ""  Vector__XXX
 SG_ EPB_01_alt : 1|1@1+ (1.0,0.0) [0.0|1] ""  Vector__XXX
 SG_ ESP_21_alt : 2|1@1+ (1.0,0.0) [0.0|1] ""  Vector__XXX
 SG_ LWI_01_alt : 3|1@1+ (1.0,0.0) [0.0|1] ""  Vector__XXX
 SG_ Parkhilfe_01_alt : 4|1@1+ (1.0,0.0) [0.0|1] ""  Vector__XXX
 SG_ Kamera_Status_alt : 5|1@1+ (1.0,0.0) [0.0|1] ""  Vector__XXX
 SG_ ESP_HDC_Standby : 6|1@1+ (1.0,0.0) [0.0|1] ""  Vector__XXX
 SG_ ECD_Bremslicht : 8|1@1+ (1.0,0.0) [0.0|1] ""  Vector__XXX
 SG_ EPB_Status : 9|2@1+ (1.0,0.0) [0.0|3] ""  Vector__XXX
 SG_ EPB_QBit_Pedalweg_Kuppl : 11|1@1+ (1.0,0.0) [0.0|1] ""  Vector__XXX
 SG_ ESP_QBit_v_Signal : 12|1@1+ (1.0,0.0) [0.0|1] ""  Vector__XXX
 SG_ ABS_Bremsung : 13|1@1+ (1.0,0.0) [0.0|1] ""  Vector__XXX
 SG_ ESP_Eingriff : 14|1@1+ (1.0,0.0) [0.0|1] ""  Vector__XXX
 SG_ Kamera_FSH_aktiv : 15|1@1+ (1.0,0.0) [0.0|1] ""  Vector__XXX
 SG_ EPB_Pedalweg_Kuppl : 16|8@1+ (0.4,0) [8.0|92.0] "Unit_PerCent"  Vector__XXX
 SG_ ESP_v_Signal : 24|16@1+ (0.01,0) [0.00|655.32] "Unit_KiloMeterPerHour"  Vector__XXX
 SG_ LWI_QBit_Lenkradwinkel : 40|1@1+ (1.0,0.0) [0.0|1] ""  Vector__XXX
 SG_ LWI_Sensorstatus : 41|1@1+ (1.0,0.0) [0.0|1] ""  Vector__XXX
 SG_ LWI_VZ_Lenkradwinkel : 42|1@1+ (1.0,0.0) [0.0|1] ""  HUD,Kombi
 SG_ LWI_Lenkradwinkel : 43|13@1+ (0.1,0) [0.0|800.0] "Unit_DegreOfArc"  HUD,Kombi
 SG_ PH_Anf_Audioabsenkung : 56|1@1+ (1.0,0.0) [0.0|1] ""  Vector__XXX
 SG_ PH_Systemzustand : 57|3@1+ (1.0,0.0) [0.0|7] ""  Vector__XXX
 SG_ PH_Taster : 60|2@1+ (1.0,0.0) [0.0|3] ""  Vector__XXX
 SG_ ESP_MKB_Abbruch_Geschw : 62|1@1+ (1.0,0.0) [0.0|1] ""  Vector__XXX
 SG_ PLA_Anf_Aufschaltung_RVC : 63|1@1+ (1.0,0.0) [0.0|1] ""  Vector__XXX

CM_ BO_ 1520 "ab MQB nach abgestimmten FLH Dimmung";
CM_ BO_ 1603 "ab MQB mit 8 Byte";
CM_ BO_ 1629 "neu im MQB";
CM_ BO_ 253 "Neue Momente im MQB
Struktur ab MQB mit CRC8 entstanden aus ESP_01";
CM_ BO_ 795 "neu für MQB wg. Absicherung
Entstanden aus ESP_04";
CM_ BO_ 986 "Fahrwerk, Extended -> Komfort, Infotainment";

CM_ SG_ 2527679921 CPD_CallCenter "Trigger an Call Center";
CM_ SG_ 2527679921 CPD_Deaktivierung_Permanent "Status der permanenten Deaktivierung der CPD-Warnung zur Anzeige (z.B. in der App)";
CM_ SG_ 2527679921 CPD_Deaktivierung_Temp "Status der temporären Deaktivierung der CPD-Funktin zur Anzeige  in der App";
CM_ SG_ 2527679921 CPD_Mobiltelefon_BLE "Triggersignal CPD zu Car2Phone-App per Bluetooth";
CM_ SG_ 2527679921 CPD_Mobiltelefon_GSM "Trigger an Mobiltelefon über Mobilfunknetz";
CM_ SG_ 2527679921 CPDFct_Deakt "Anzeige Kombi bei KL15:AUS (Kombi) und Infotainment (während Fahrt) ob Fkt CPD 2.1 temporär oder dauerhaft deaktiviert wurde";
CM_ SG_ 2527679921 CPDFct_Symbol "Status der CPD Kontrollleuchte Fkt CPD 2.1";
CM_ SG_ 2527679921 CPDFct_Warnung "Anzeige Kombi bei KL15:AUS im Warnfall Fkt CPD 2.1";

CM_ SG_ 918 DR_Gelbe_Warnlampe "Bit wird gesetzt, wenn während des Betriebes ein Fehler erkannt wird.";

CM_ SG_ 686 DC_IstSpannung_HV "Momentanwert:  Hochspannung am DC/DC Wandler";
CM_ SG_ 686 DC_IstSpannung_NV "Momentanwert: Bordnetzspannung am DC/DC Wandler";
CM_ SG_ 686 DC_IstStrom_NV "Momentanwert: Strom vom DC/DC in das Bordnetz
Tiefsetzen - positiv
Hochsetzen - negativ";
CM_ SG_ 686 DCDC_01_CRC "Für MLB:
'Berechnung siehe Lastenheft 'Kommunikationsabsicherung für FlexRay und CAN''

Ab MQB und MLBevo:
'Berechnung siehe Lastenheft 'End-to-End Kommunikationsabsicherung''

Endwerte siehe Begleitdokument 'S-PDU Kennungsfolgen'";

CM_ SG_ 1012 DC_HYB_Auslastungsgrad "Momentanwert: Auslastung DC/DC (DFM Signal), entspricht I_akt / I_max
(Vorhalt für MQB)";
CM_ SG_ 1012 DC_ReserveStrom_NV "Momentanwert: Stromreserve vom DC/DC-Wandler in Richtung 12V-Bordnetz

Tiefsetzen - positiv
Hochsetzen - negativ";
CM_ SG_ 1012 DC_Verbrauch "Energieverbrauch vom DCDC für Versorgung 12V-Bordnetz inkl. seines eigenen Wirkungsgrads (bspw.: HV_Strom*HV_Spannung*t)";
CM_ SG_ 1012 DC_Verbrauch_Ueberlauf "Überlauf-Bit für das Signal DC_Verbrauch";
CM_ SG_ 1012 DC_Verlustleistung "Aktuelle Verlustleistung des DC/DC-Wandlers.";
CM_ SG_ 1012 DCDC_02_CRC "Für MLB:
'Berechnung siehe Lastenheft 'Kommunikationsabsicherung für FlexRay und CAN''

Ab MQB und MLBevo:
'Berechnung siehe Lastenheft 'End-to-End Kommunikationsabsicherung''

Endwerte siehe Begleitdokument 'S-PDU Kennungsfolgen'";

CM_ SG_ 247 DC_Fehler_extern "Fehler/Abschaltung: DC/DC-Wandler ist aufgrund einer Umgebungsbedingung (z.B. HV-Spannung, NV-Spannung Kühlmitteltemperatur oder Systemfehler (ZK-Vorladung) ) nicht in der Lage geforderten Regelbetrieb einzuhalten.";
CM_ SG_ 247 DC_Fehler_intern "Fehler: DC/DC-Wandler ist aufgrund eines internen Hardware-Fehlers abgeschaltet";
CM_ SG_ 247 DC_IstLeistung_HV "Aktuelle Ist-Leistung des Bordnetzwandlers auf der HV-Seite. 

Tiefsetzen - positiv
Hochsetzen- negativ";
CM_ SG_ 247 DC_IstModus_02 "aktuelle Betriebsart des DC/DC Wandlers;
0: Standby; Kommunikation aktiv
1: HV_On_Vorladen
2: Tiefsetzen
3: Hochsetzen
4: Pruefimpuls_12V
5: interner Fehler DC/DC-Wandler / angeforderter Sollmodus kann nicht eingestellt werden
6: reserve
7: Initia";
CM_ SG_ 247 DC_IstStrom_HV "Momentanwert:  Strom aus dem Traktionsnetz in den DC/DC Wandler";
CM_ SG_ 247 DC_Status_EoHVL "Status der EoHVL am DCDC :
0=Init
1=Keine offene HV-Leitung erkannt
2=offene HV-Leitung erkannt
3=Fehler";
CM_ SG_ 247 DC_Status_Spgfreiheit "Status der Spannungsfreiheit für den Standalone DCDC-Wandler (HV-NV)
0=Init (ohne Funktion)
1=BMS Zwischenkreis spannungsfrei (U_Zwkr < 20V)
2=BMS Zwischenkreis nicht spannungsfrei (U_Zwkr >/= 25V, Hysterese)
3=Fehler (z.B. Fehler in der Sensorik)";
CM_ SG_ 247 DC_Vorladung_Status "Status der ZK-Vorladung:

=0, nicht_abgeschlossen
=1, abgeschlossen

DCDC-Wandler gibt Empfehlung für schließen der Schützen. 
HVK/BMS prüft die ZK-Spannung und entscheidet ob die Schütze geschlossen werden können.";
CM_ SG_ 247 DCDC_04_BZ "4bit Botschaftszähler, wird mit jeder Sendebotschaft inkrementiert
Botschaft asynchron geroutet. Zählerwert kann springen.";
CM_ SG_ 247 DCDC_04_CRC "Für MLB:
Berechnung siehe Lastenheft 'Kommunikationsabsicherung für FlexRay und CAN'
Ab MQB und MLBevo:
Berechnung siehe Lastenheft 'End-to-End Kommunikationsabsicherung'

Endwerte siehe Begleitdokument 'S-PDU Kennungsfolgen'";

CM_ SG_ 2583738904 DDA_AuthTime_Req_Data "AuthTime - Authentische Zeit
ISO-TP Datenkanal - NA2FID
Request Knoten 0xBA DDA (Transceiver Modul)

DDA an Funktion Authentische Zeit (Request)";

CM_ SG_ 2583869976 DDA_AuthTime_Resp_Data "AuthTime - Authentische Zeit
ISO-TP Datenkanal - NA2FID
Response Funktion 0x18 AuthTime

Funktion Authentische Zeit an DDA (Transceiver Modul) (Response)";

CM_ SG_ 2549880335 DIA_ABT_2_Req_Data "DK2F Flash Diagnosezugriff";

CM_ SG_ 2550011407 DIA_ABT_2_Resp_Data "DK2F Flash Diagnosezugriff";

CM_ SG_ 1714 DGN_Verlernzaehler "wrap around 254 --> 0";
CM_ SG_ 1714 KBI_Kilometerstand "Fehler wird ausgegeben, falls Kilometerstand nicht restaurierbar
";
CM_ SG_ 1714 UH_Minute "0x3C- 0x3f = Werte ungültig";
CM_ SG_ 1714 UH_Monat "0x0D, 0xF =  Werte ungültig
0x0E = Relatives Datum (nur VW)";
CM_ SG_ 1714 UH_Sekunde "0x3C- 0x3f = Werte ungültig";
CM_ SG_ 1714 UH_Stunde "0x18 - 0x1F = Werte ungültig";
CM_ SG_ 1714 UH_Tag "0x0: reserviert bei VW";
CM_ SG_ 1714 Uhrzeit_01_alt "
";
CM_ SG_ 1714 Vehicle_Driving_Cycle "Optimierung der Inbetriebnahme von Steuergeräten in einem Teilverbau in der Produktion.
Siehe VW80114. Signal bildet (durch eine Gateway-Funktion) den Inhalt des Signals OBD_Driving_Cycle ab.";

CM_ SG_ 1520 BCM1_Stellgroesse_Kl_58s "Rohwert Dimmpoti";
CM_ SG_ 1520 DI_Display_Nachtdesign "Für Displays sind oft  automatische Umschaltungen von Tag-/Nachtdesign vorgesehen.
Es gibt jedoch Zustände, an denen auch tagsüber das Abblendlicht eingeschaltet ist.
z.B. Dauerfahrlicht, Geschwindigkeitsabhängiges 'Licht-An-Bei-Autobahn', 'Regenlicht',";
CM_ SG_ 1520 DI_Fotosensor "Helligkeitswert Fotosensor
Für die Dimmung relevanter Wert zur Sensierung der Umgebungshelligkeit
Im Detail beschrieben im 'Funktionslastenheft Dimmung MQB'.";
CM_ SG_ 1520 DI_KL_58xd "Klemme 58xd Display- und Funktionsbeleuchtung
Mit der Klemme 58xd wird die Helligkeit der Display- und der Funktionsbeleuchtungen der Schalter gesteuert.
Im Detail beschrieben im 'Funktionslastenheft Dimmung MQB'.";
CM_ SG_ 1520 DI_KL_58xs "Suchbeleuchtung Schalter
EIN-AUS-Schaltalgorithmus der allgemeinen Schaltersuchbeleuchtung. 
Im Detail beschrieben im 'Funktionslastenheft Dimmung MQB'.
";
CM_ SG_ 1520 DI_KL_58xt "Timergesteuerte Suchbeleuchtung
Der EIN-AUS-Schaltalgorithmus für die vor- und nachlaufende Schaltersuchbeleuchtungen beim Ein- & Aussteigen; z.B.: Start/Stop-Taster.
Im Detail beschrieben im 'Funktionslastenheft Dimmung MQB'.";

CM_ SG_ 496 ACF_Lampe_Hands_Off "Anzeige, ob der Fahrer die Hände am Lenkrad hat.";
CM_ SG_ 496 EA_02_BZ "Botschaftszähler";
CM_ SG_ 496 EA_02_CRC "Für MLB:
'Berechnung siehe Lastenheft 'Kommunikationsabsicherung für Flexray und CAN''

Ab MQB und MLBevo:
'Berechnung siehe Lastenheft 'End-to-End Kommunikationsabsicherung'

Endwerte siehe Begleitdokument 'S-PDU Kennungsfolge'";
CM_ SG_ 496 EA_Blinken "Emergency Assist Anforderung Blinker";
CM_ SG_ 496 EA_Bremslichtblinken "Die Funktion Emergency Alert fordert ein Blinken der Bremsleuchten an.";
CM_ SG_ 496 EA_eCall_Anf "Emergency Assist Anforderung eCall";
CM_ SG_ 496 EA_Fahrzeughupe_Anf "Emergency Assist Anforderung Fahrzeughupe";
CM_ SG_ 496 EA_Infotainment_Anf "Emergency Assist Anforderung Absenkung Infotainment-Funktionen";
CM_ SG_ 496 EA_Innenraumlicht_Anf "Anforderung Innenraumbeleuchtung durch den Emergency Assist";
CM_ SG_ 496 EA_Status_HMI "Anzeige Emergency Assist-Statusleuchte im Fahrerinformationsdisplay";
CM_ SG_ 496 EA_Texte "Anzeige der EA Texte";
CM_ SG_ 496 EA_Tueren_Anf "Emergency Assist Anforderung Türen entriegeln";
CM_ SG_ 496 EA_Warnlevel "Kritikalität der Funktion Emergency Assist";
CM_ SG_ 496 STP_Primaeranz "Primäranzeige des Staupiloten";
CM_ SG_ 496 zFAS_Warnblinken "Anforderung Warnblinken durch zFAS Funktionen.";

CM_ SG_ 2583717656 eCall_AuthTime_Req_Data "AuthTime - Authentische Zeit
ISO-TP Datenkanal - NA2FID
Request Knoten 0x67 eCall (OCU)

OCU an Funktion Authentische Zeit (Request)";

CM_ SG_ 2583848728 eCall_AuthTime_Resp_Data "AuthTime - Authentische Zeit
ISO-TP Datenkanal - NA2FID
Response Funktion 0x18 AuthTime

Funktion Authentische Zeit an OCU (Response)";

CM_ SG_ 1603 KBI_Einheit_Datum "Anzeigevariante des Datums";
CM_ SG_ 1603 KBI_Einheit_Druck "Einheit des Druckes";
CM_ SG_ 1603 KBI_Einheit_Masse "Einheit der Masse (Verwendung z.B. ASTA)";
CM_ SG_ 1603 KBI_Einheit_Sprache "Siehe BAP-Datenfestlegung UnitMaster";
CM_ SG_ 1603 KBI_Einheit_Streckenanz "Einheit der Streckenanzeige";
CM_ SG_ 1603 KBI_Einheit_Tacho "Information, ob es sich um Meilen- oder Kmh-Kombi handelt, Einheit des Tachos entspricht dem Zifferblatt, Grösse ist nicht veränderlich";
CM_ SG_ 1603 KBI_Einheit_Temp "Einheit der Temperatur";
CM_ SG_ 1603 KBI_Einheit_Uhrzeit "Anzeigevariante der Uhrzeit";
CM_ SG_ 1603 KBI_Einheit_Verbrauch "Einheit der Verbrauchs";
CM_ SG_ 1603 KBI_Einheit_Verbrauch_elektr "Einheit elektrischer Verbrauch";
CM_ SG_ 1603 KBI_Einheit_Verbrauch_Gas "Unterscheidung zwischen M3/h und kg/h für Komfortverbrauchsberechnung.";
CM_ SG_ 1603 KBI_Einheit_Volumen "Einheit des Volumens";
CM_ SG_ 1603 KBI_MFA_v_Einheit_02 "Einheit der Geschwindigkeit, die vom Fahrer im Car-Menü gewählt wurde. Veränderliche Grösse, im Gegensatz zur Einheit des Tachokranzes.

Redundant in der Einheiten_01 Botschaft definiert, um Konsistenz zur BAP-Festlegung zu haben.";

CM_ SG_ 1622 ELV_01_BZ "4bit Botschaftszaehler, wird mit jeder Sendebotschaft inkrementiert";
CM_ SG_ 1622 ELV_01_CRC "Ab MQB und MLBevo:
'Berechnung siehe Lastenheft 'End-to-End Kommunikationsabsicherung''

Endwerte siehe Begleitdokument 'S-PDU Kennungsfolgen'";
CM_ SG_ 1622 ELV_01_Sendestatus "Zeigt an, ob die ELV für einen begrenzten Zeitraum mit verkürzter Zykluszeit (50ms) sendet. Das ist bis zur KL15ein notwendig, um eine Motorstartverzögerung zu vermeiden.";
CM_ SG_ 1622 ELV_Abbruch_Anf_Klemmenfreigabe "Klemmenanforderung des Kessy-SG wird von der ELV verworfen und muss vom Kessy zurückgenommen werden.";
CM_ SG_ 1622 ELV_Anf_Klemme_15 "Signal wird zur Plausibilisierung parrallel zum Klemmensignal auf dem CAN übertragen
Anforderung Klemme_15";
CM_ SG_ 1622 ELV_Anf_Klemme_50 "Signal wird zur Plausibilisierung parrallel zum Klemmensignal auf dem CAN übertragen
Anforderung Klemme_50";
CM_ SG_ 1622 ELV_Anf_Klemme_S "Signal wird zur Plausibilisierung parallel zum Klemmensignal auf dem CAN übertragen
Anforderung Klemme_S";
CM_ SG_ 1622 ELV_Anlernmodus "Im Anlernmodus (1) ist zum Einschalten der KLS u.KL15 keine Authentifizierung der WFS notwendig. KL50 ist nicht einschaltbar.
Auslieferungszustand ist (1)";
CM_ SG_ 1622 ELV_Entriegelt "ELV im Zustand entriegelt
";
CM_ SG_ 1622 ELV_Klemmenfreigabe "Freigabe/Quittierung der ELV für das Einschalten der Klemme 15 und Klemme S";
CM_ SG_ 1622 ELV_Lebenszustand "Auslieferungszustand ist (0)
Lebenszustand";
CM_ SG_ 1622 ELV_LED_Gelb "Warnlampe Gelb";
CM_ SG_ 1622 ELV_LED_Rot "Warnlampe Rot";
CM_ SG_ 1622 ELV_P_verriegelt "Position P-verriegelt vom Gangwahlhebel";
CM_ SG_ 1622 ELV_Txt_Bremse "Text: 'Bremspedal betätigen!'";
CM_ SG_ 1622 ELV_Txt_Defekt "Text: 'Lenkungsverriegelung defekt!'";
CM_ SG_ 1622 ELV_Txt_Kupplung "Text: 'Kupplungspedal betätigen!'";
CM_ SG_ 1622 ELV_Txt_Lkg_Bewegen "Text: 'Lenkrad bewegen!'";
CM_ SG_ 1622 ELV_Txt_P_Gang "Text: 'Wählhebel in Position P bringen!'";
CM_ SG_ 1622 ELV_Txt_Panikabschaltung "Text: 'Notabschaltung''";
CM_ SG_ 1622 ELV_Txt_PN_Gang "Text: 'Wählhebel in Position P/N bringen!'";
CM_ SG_ 1622 ELV_Txt_Werkstatt "Text: 'Lenkungsverriegelung! Werkstatt!'";
CM_ SG_ 1622 ELV_Verriegelt "ELV im Zustand verriegelt
";
CM_ SG_ 1622 ELV_ZAT_betaetigt "Zündanlass-Taster (ZAT) betätigt";
CM_ SG_ 1622 KST_Anf_ZV_Verriegelung "Neuer Verriegelungstrigger für die ZV nach der automatischen Klemmenabschaltung.

Wird bei Kessyfahrzeugen mit StartStop ein aktiver Stop-Mode und Fahrerverlassen erkannt, startet ein 30 Sekunden-Timer. Innerhalb dieser 30 Sekunden hat der Fahrer die Mö";
CM_ SG_ 1622 KST_aut_Abschaltung_Zuendung "Falls bei eingeschalteter Zündung das Abblendlicht aktiv war, muss nach der automatischen Abschaltung der Kl_15 & Kl_S, dass Standlicht aktiv bleiben. Das Signal sendet die Information, dass eine automatische Abschaltung der Kl_15 und Kl_S erfogt.";
CM_ SG_ 1622 KST_Txt_Komfortabschaltung "Dieses Signal fordert im Kombi die Meldung an, die den Fahrer über die ausgeführte automatische Zündungsabschaltung informiert. Signal wird für10s gesendet.";

CM_ SG_ 26 ELV_WFS_Anfrage_CRC "ELV_WFS_Anfrage_CRC";
CM_ SG_ 26 ELV_WFS_Anfrage_Status "ELV_WFS_Anfrage_Status";
CM_ SG_ 26 ELV_WFS_Anfrage_Typ "ELV_WFS_Anfrage_Typ";

CM_ SG_ 184 EM1_Abregelung_Temperatur "Leistungsbegrenzung aufgrund Übertemperatur der E-Maschine / des PWR";
CM_ SG_ 184 EM1_AnlernenElMotor_Anf "Diagnoseanforderung von E-Maschine/PWR: Hybrid-Controller schaltet über MO_EM_Sollmodus=6 bzw. MY3_EM_modeReq=6 E-Maschine/PWR aktiv in den Kalibriermodus (Strategie muss sicherstellen, dass kein Moment bei der EM angefordert wird.)";
CM_ SG_ 184 EM1_AR_aktiv "Ruckeldämpfer aktiv";
CM_ SG_ 184 EM1_Eta_Sys "Instantaneous efficiency of electrical drive EM1 / Momentaner Wirkungsgrad elektrischer Antrieb EM1";
CM_ SG_ 184 EM1_Fehler_ElAntriebFreilauf_Anf "Wird gesetzt um den zwingenden Bedarf einer Umschaltung in den Freilauf anzuzeigen. Vergleiche Signal EM1_MaxZul_Drehzahl.";
CM_ SG_ 184 EM1_Freigabe_Info_WFS "WFS-Freigabeinformation";
CM_ SG_ 184 EM1_Freigabe_Verfallsinfo_WFS "WFS";
CM_ SG_ 184 EM1_HV_betriebsbereit "1: Ready_HV / 1: HV-Netz Spannung im Betriebsbereich";
CM_ SG_ 184 EM1_IstStrom "Momentanwert: Strom über PWR";
CM_ SG_ 184 EM1_Moment_HVVerbraucher "rechnerisch benötigtes Generator-Moment, um den Bedarf der el. Nebenverbraucher incl. Batterieladung abzudecken";
CM_ SG_ 184 EM1_Parken_WFS_Status "Status der Limitierung";
CM_ SG_ 184 EM1_Sperr_Info_WFS "WFS-Sperrinformation
";
CM_ SG_ 184 LE_Kuehlmittel_Sensor "Signal der Sensorelektroden für den Kühlmittelfüllstand aktuell, entstört, bewertet (OK/Mangel)";

CM_ SG_ 2589283970 DIST_DKmtg_Auth "Vehicle lifetime traveled distance authentic";
CM_ SG_ 2589283970 SOK_Entfernung_02_Signatur "Signatur im Rahmen der durch SOK geschützten Broadcast-Kommunikation

Geschützte Funktion: Wegstreckensicherheit
Geschützte Signale: DIST_DKmtg_Auth";

CM_ SG_ 2331595989 DIST_DKmtg "Vehicle lifetime traveled distance";

CM_ SG_ 2589283751 KBI_Kilometerstand_Extended "Erweiterter Kilometerstand in km (über 999.999 km)";
CM_ SG_ 2589283751 KBI_Kilometerstand_HiRes_meter "Höchauflösenderes Signal als KBI_Kilometerstand_HiRes um Umrechnung zu vermindern und eine höhere Auflösung als 0,1km zu erhalten.
Auflösung 1m / Bit";

CM_ SG_ 503 EPB_03_BZ "Botschaftszähler";
CM_ SG_ 503 EPB_03_CRC "Für MLB:
'Berechnung siehe Lastenheft 'Kommunikationsabsicherung für FlexRay und CAN''

Ab MQB und MLBevo:
'Berechnung siehe Lastenheft 'End-to-End Kommunikationsabsicherung''

Endwerte siehe Begleitdokument 'S-PDU Kennungsfolgen'
";
CM_ SG_ 503 EPB_Autohold_Standbyanzeige "Ansteuerung der Autohold-Bereitschaftsanzeige im Kombiinstrument";
CM_ SG_ 503 EPB_Autoholdlampe_02 "Autoholdlampe im Kombi, grünes P";
CM_ SG_ 503 EPB_Fehlermeldungen_02 "Über das Signal werden bestimmte Fehlertexte und -lampen im Kombi angefordert.";
CM_ SG_ 503 EPB_Funktionslampe_02 "Bit wird nur gesetzt, wenn volle Spannkraft auf beiden Seiten erreicht. Rote Lampe (rotes P) im Kombiinstrument";
CM_ SG_ 503 EPB_Parkanzeige "Signalisierung der Funktionsaktivierung der Parkbremse. Dient zur Anzeige des Schriftzug „PARK“ im i.ID..";
CM_ SG_ 503 EPB_Texte_02 "EPB-Texte für Kombi
9 bei Audi aktuell nicht bedient.
10 bei Audi hinzugefügt für RSe
11 bei PAG Duo Servo Parkbremse aktuell nicht bedient 
12 bei PAG Duo Servo Parkbremse aktuell nicht bedient";

CM_ SG_ 258 ASR_Systemstatus "ASR-Systemstatus für Datenablage im EDR";
CM_ SG_ 258 ECD_Bremslicht "Bremslichtansteuerung durch ECD-Funktion";
CM_ SG_ 258 ECD_Fehler "ESP kann die Verzögerungsregelung/Bremsenregelung aufgrund eines internen Fehlers nicht ausführen, mit Fehlereintrag im ESP.
";
CM_ SG_ 258 ECD_nicht_verfuegbar "ESP kann die Verzögerungsregelung/Bremsenregelung temporär nicht ausführen (z.B. Netzwerkmanagement-Betriebe - KL15 Aus; v<18km/h; ESP in Diagnose, ...), ohne Fehlereintrag im ESP.

";
CM_ SG_ 258 EPB_DAA_Randbed_erf "Die Randbedingungen zum automatischen Öffnen der EPB (Funktion DAA) sind erfüllt und ein Betätigen des Fahrpedals führt zum Öffnen der EPB.";
CM_ SG_ 258 EPB_Fehlerstatus_02 "Anpassung der Texte an die  aktuellen Zustände für weitergehende Funktionen (Stillstandsmanager)";
CM_ SG_ 258 EPB_Freig_Verzoeg_Anf "Verzögerungsanforderung	";
CM_ SG_ 258 EPB_Pedalweg_Kuppl "Signal entspricht Tastverhältnis des PWM. Gesamtweg Kupplungspedal 10% bis 90%, damit zu erwartende Werte 25 bis 225. 25 bei Kupplungspedal nicht getreten, 225 bei Kupplungspedal voll durchgetreten.
2% Toleranz wird im Wertebereich ermöglicht (8%-92%).
";
CM_ SG_ 258 EPB_Schalterposition "Spiegelt die Schalterstellung wieder.

0x3 = Schalterfehler ";
CM_ SG_ 258 EPB_Spannkraft "Erzeugte Spannkraft. Bezieht sich auf die Aktuatoren.

MQB: Spannkraftwerte entsprechen nicht den tatsächlichen Spannkräften. Genauere Informationen bitte in der Fachabteilung erfragen! ";
CM_ SG_ 258 EPB_Status "Gibt den Zustand der EPB-Aktuatoren an.

Nur VW526/PAG E2: Wert 0x3 bedeutet 'unbekannt'

";
CM_ SG_ 258 EPB_Status_02 "Erweiterung der Zustände um ein genaueres Bild des aktuellen Zustandes zu erhalten für weitergehende Funktionen ( Stillstandsmanager)
";
CM_ SG_ 258 EPB_Verzoeg_Anf "Steuerungsanforderung an andere Systeme (z.B. ESP), um während der Fahrt, durch den Handbremsschalter ausgelöst, zu bremsen (ECD-Funktion)";
CM_ SG_ 258 ESC_50_BZ "4bit Botschaftszähler, wird mit jeder Sendebotschaft inkrementiert";
CM_ SG_ 258 ESC_50_CRC "Für MLB:
Berechnung siehe Lastenheft 'Kommunikationsabsicherung für FlexRay und CAN'
Ab MQB und MLBevo:
Berechnung siehe Lastenheft 'End-to-End Kommunikationsabsicherung'

Endwerte siehe Begleitdokument 'S-PDU Kennungsfolgen'";
CM_ SG_ 258 ESC_Bremsdruckgradient "Das Signal zeigt den vom Fahrer gedruckten Bremsdruckgradienten";
CM_ SG_ 258 ESC_Fahrerbremswunsch "PHEV: Berechneter Druck anhand des eBKV-Ausgangsstangenwegs sowie ESP-pMC. Reku nicht aktiv--> vergleichbar mit ESP_Bremsdruck; Reku aktiv --> virtueller Bremsdruck
Konv.: entspricht ESP_Bremsdruck";
CM_ SG_ 258 ESC_Fahrerradbremswunschmoment "Berechnetes Moment anhand des eBKV-Ausgangsstangenwegs, THZ-Druck, cp-Faktoren der Bremsen und Bremspedalbetätigung.
Reku nicht aktiv--> entspricht dem berechneten Moment auf Basis THZ-Druck; 
Reku aktiv --> entspricht dem berechneten Moment auf Basis v";
CM_ SG_ 258 ESC_Hydr_Fkt_aktiv "Info über die Aktivität von Druckaufbaufunktionen im ESC und Uebermittlung des Warnlevel an EBKV.";
CM_ SG_ 258 ESC_Motorstartverzoegerung "Mit dem Signal 'Motorstartverzögerung' wird den aktiven Teilnehmern ermöglicht, einen Motorstart durch die Start-Stop-Funktion zu verzögern.";
CM_ SG_ 258 ESC_QBit_Fahrerbremswunsch "Gesetzt bei Ersatzwert, Init oder Fehler.";
CM_ SG_ 258 ESC_Raddruck_max "Stellt den zahlenmäßig höchsten Druckwert der vier modellierten Raddrücke dar.";
CM_ SG_ 258 ESC_SeitenwindAssistent_Eingriff "Mit diesem Statusbit wird eine aktive Regelung durch den Seitenwindassistenten signalisiert.";
CM_ SG_ 258 ESC_Unterdruckmangel_erkannt "ESC hat einen Unterdruckmangel im Bremskraftverstärker festgestellt";
CM_ SG_ 258 ESCGeneratorSollMoment "In MLBevo Faktor in TS_Faktor_Radmomente beachten!

Verzögernd wirkender Antriebsstrangsollmomentenanteil aus Bremspedalbetätigung auf Summenradebene.";
CM_ SG_ 258 ESP_Abrutschen_Stillstand "Das ESP teilt über dieses Bit mit, dass ein Abrutschen im Stillstand erkannt wurde.

Im MQB wird das Signal nicht unterstützt!";
CM_ SG_ 258 ESP_ANB_CM_Rueckk_Umsetz "Das Signal dient als Rückmeldung zum ACC, dass eine angeforderte ANB-CM durchgeführt wird. Die positive Rückmeldung löst u.a. eine entsprechende Fahrerinformation im Kombiinstrument aus";
CM_ SG_ 258 ESP_Anforderung_EPB "ESP fordert von der EPB Öffnen bzw. Schliessen an. Notwendig wegen Autohold-Funktion.";
CM_ SG_ 258 ESP_Anschleppstart_Freigabe "Bilden einer Schleppstartfreigabe aus Fahrdynamiksicht. Schleppstartabbruch bei kritischer Fahrzeugstabilität";
CM_ SG_ 258 ESP_Autohold_aktiv "Rückmeldung an EPB, dass Autohold aktiv ist.";
CM_ SG_ 258 ESP_Autohold_Standby "Rückmeldung an EPB, dass der Fahrer die Funktion Autohold mindestens einmal angefordert hat. Im Fall eines ESP-Ausfalles oder einer Übernahmeaufforderung erfolgt die EPB-Zuschaltung nur nach Setzen dieses Bits. Bit wird gesetzt nach Betätigung des Autohol";
CM_ SG_ 258 ESP_BKV_Unterdruck "Der maximale Wert wird auf 1012 mbar begrenzt.
Dieses Signal wird im AU64x nicht unterstützt.

Hinweis: Auch bei nicht verbautem BKV-Unterdrucksensor könnte während der Initialisierung der Initialisierungswert gesendet werden.";
CM_ SG_ 258 ESP_Bremsdruck "Rohwert des Bremsdrucks
Für Fahrzeuge mit elektrischem Bremskraftverstärker gilt: Aus dem Signal ESP_Bremsdruck lässt sich kein Fahrerbremswunsch ableiten. Das Signal bildet lediglich den hydraulischen Anteil der Fahrzeugverzögerung ab. Der Rohwert des S";
CM_ SG_ 258 ESP_Bremsruck_AWV2 "Das Signal dient als Rückmeldung zum ACC, dass ein angeforderter AWV2-Bremsruck durchgeführt wird. Die positive Rückmeldung löst u.a. eine entsprechende Fahrerinformation im Kombiinstrument aus";
CM_ SG_ 258 ESP_Eingr_HL "wird von QSP und Neigungsanzeige verwendet

Flag wird vom ESP gesetzt, sobald aufgrund eines ESP-Eingriffs am Rad aktiv Druck aufgebaut wird.
Frühestens mit öffnen des Ventils und spätestens bei einem Bremsmoment von 100Nm. Flag bleibt solange gesetzt ";
CM_ SG_ 258 ESP_Eingr_HR "wird von QSP und Neigungsanzeige verwendet

Flag wird vom ESP gesetzt, sobald aufgrund eines ESP-Eingriffs am Rad aktiv Druck aufgebaut wird.
Frühestens mit öffnen des Ventils und spätestens bei einem Bremsmoment von 100Nm. Flag bleibt solange gesetzt ";
CM_ SG_ 258 ESP_Eingr_VL "wird von QSP und Neigungsanzeige verwendet

Flag wird vom ESP gesetzt, sobald aufgrund eines ESP-Eingriffs am Rad aktiv Druck aufgebaut wird.
Frühestens mit öffnen des Ventils und spätestens bei einem Bremsmoment von 100Nm. Flag bleibt solange gesetzt ";
CM_ SG_ 258 ESP_Eingr_VR "wird von QSP und Neigungsanzeige verwendet

Flag wird vom ESP gesetzt, sobald aufgrund eines ESP-Eingriffs am Rad aktiv Druck aufgebaut wird.
Frühestens mit öffnen des Ventils und spätestens bei einem Bremsmoment von 100Nm. Flag bleibt solange gesetzt ";
CM_ SG_ 258 ESP_Fahrer_bremst "Bit wird gesetzt beim Überschreiten der Bremsdruckschwelle

Weiterführende Informationen im Lastenheft spezifiziert und in der entsprechenden Fachabteilung zu erfragen.
";
CM_ SG_ 258 ESP_Fahrer_tritt_ZBR_Schw "Rückmeldung des ESP an AWV, ob der Fahrer die aktuell gültige ZBR-Schwelle übertritt";
CM_ SG_ 258 ESP_FStatus_Anfahrhilfe "Bei gesetztem Bit steht die Funktion Berganfahrassistent (Hillhold) nicht zur Verfügung";
CM_ SG_ 258 ESP_Gierrate "Winkelgeschwindigkeit um die z-Achse, ESP_VZ_Gierrate & ESP_QBit_Gierrate beachten !!!

MLB: gemessener Wert
tatsächliche Auflösung Bosch ESP: 0,27 Grad/s

Ab AU64x Auflösung wie die tatsächliche Skalierung 0,01. Im AU64x und AU57x wird bei ESP-Absch";
CM_ SG_ 258 ESP_HBA_aktiv "Verwendung/Bedienung ab D4
Signal gibt an, ob der hydraulische Bremsassistent im Regler aktiviert wurde

Im MQB wird das Signal nicht unterstützt!

";
CM_ SG_ 258 ESP_HBA_Empfindlichkeit "Signal gibt die aktuell gültige Auslöseempfindlichkeit des Hydraulischen Bremsassistenten an";
CM_ SG_ 258 ESP_HDC_aktiv "MQB und AU57x Allroad: Mit diesem Statusbit wird eine gerade aktive Regelung des Bergabfahrassistenten (Hill Descent Control) signalisiert.";
CM_ SG_ 258 ESP_HDC_Standby "Verwendung/Bedienung im MQB und AU57x Allroad:
Flag wird vom ESP gesetzt, wenn über den HDC-Taster die HDC-Funktion eingeschalten wurde";
CM_ SG_ 258 ESP_Konsistenz_ACC_Botschaft "Rückmeldung zum Sender der Verzögerungsanforderung ACC bezüglich Prüfung CHK/CRC, BZ und langer Timeout. Wird auch gesetzt bei einer Verzögerungsanforderung größer als eine applizierbare Schwelle.

Im D4/C7: Botschaft ACC_05
Im MQB: Botschaft ACC_07";
CM_ SG_ 258 ESP_Konsistenz_AWV2 "Rückmeldung zum Sender einer AWV-Anforderung (ACC-Steuergerät) bezüglich Prüfung der Checksumme, des Botschaftszählers, des langen Timeout und DLC.
";
CM_ SG_ 258 ESP_Konsistenz_TSK "Rückmeldung zum Sender einer Verzögerungsanforderung (Triebstrangskoordinator) bezüglich Prüfung der Checksumme, des Botschaftszählers, des langen Timeout und DLC. Wird auch gesetzt bei Verzögerungsanforderung größer einer applizierbaren Schwelle.
";
CM_ SG_ 258 ESP_Laengsbeschl "Beschleunigungswert in x-Achse

MLB: Im AU64x und AU57x erfolgt die Bereitstellung der Sensorwerte durch SARA-SG! Im AU64x und AU57x wird bei ESP-Abschaltung durch modellgestützte Überwachung das Signal weiterhin ausgegeben.

MQB: reines ABS schickt 0";
CM_ SG_ 258 ESP_Lenkeingriff_ADS "Im Falle eines fahrzeugstabilisierenden Lenkeingriffs des ADS-Systems soll ACC/GRA deaktiviert werden.

Im MQB wird dieses Signal nicht unterstützt!";
CM_ SG_ 258 ESP_Notbremsanzeige "ABS/ASR oder ESP hat Notbremssituation erkannt.
Weiterführende Informationen im Lastenheft spezifiziert und in der entsprechenden Fachabteilung zu erfragen.

";
CM_ SG_ 258 ESP_PLA_Abbruch "Wenn der Bremseingriff abgebrochen wurde, wird in diesem Signal der Grund des Abbruchs dargestellt.
Dies ist nur gültig, wenn der Status ESP_Status_ESP_PLA = '0xA' ist.";
CM_ SG_ 258 ESP_Prefill_ausgeloest "MLB: Verwendung/Bedienung ab D4
zeigt, ob die Funktion Prefill (aufgrund Fahrpedalgradient) ausgelöst wird; zeigt keinen Funktionszustand bezüglich Fehlerstilllegung

MQB: Wird gesetzt bei jeder Art von aktivem Prefill";
CM_ SG_ 258 ESP_QBit_Bremsdruck "QBit des Bremsdrucks. Gesetzt bei Ersatzwert, Init oder Fehler.";
CM_ SG_ 258 ESP_QBit_Fahrer_bremst "Gültigkeit der Bremsdruckschwelleninformation des Signals ESP_Fahrer_bremst vom ESP SG
0x1 = Druckschwelleninformation kann noch nicht oder aufgrund eines Fehlers nicht ausgegeben werden
";
CM_ SG_ 258 ESP_QBit_Gierrate "QBit der Gierrate. Gesetzt bei Ersatzwert, Init oder Fehler. 
";
CM_ SG_ 258 ESP_QBit_Laengsbeschl "QBit der Längsbeschleunigung. Gesetzt bei Ersatzwert, Init oder Fehler. 
";
CM_ SG_ 258 ESP_QBit_Querb "QBit der Querbeschleunigung. Gesetzt bei Ersatzwert, Init oder Fehler. ";
CM_ SG_ 258 ESP_QBit_v_ref "QBit der Referenzgeschwindigkeit ESP_v_ref. Gesetzt bei Ersatzwert, Init oder Fehler.
Detailinformationen zu dem Signal sind dem Lastenheft 'Signalexport - Funktionale Anforderungen an ESP' zu entnehmen - Signal ESP_St_v_fzg_ref";
CM_ SG_ 258 ESP_Querbeschleunigung "Beschleunigungswert in y-Achse

MLB: Gemessener Wert
0xFF = Fehler (wie bereits im Wertebereich spezifizert)
Bei ESP-Abschaltung durch modellgestützte Überwachung wird das Signal weiterhin ausgegeben.
Im AU64x und AU57x erfolgt die Bereitstellung der";
CM_ SG_ 258 ESP_Rueckwaertsfahrt_erkannt "nur bei AU57x und AU416 sowie Audi B8PA
Info, ob Rückwärtsfahrt über internen Algorithmus sicher erkannt

Im MQB wird das Signal nicht unterstützt!";
CM_ SG_ 258 ESP_Schwelle_Unterdruck "Verwendung im MQB für HBV-Projekte oder wenn für St/St ein Unterdrucksensor verbaut ist";
CM_ SG_ 258 ESP_SpannungsAnf "Die Rekuperation kann mit der Anforderung einer höheren Spannung eingeschränkt werden.";
CM_ SG_ 258 ESP_StartStopp_Info "Stopp-Freigabe und Start-Anforderung an den Start-Stopp-Koordinator";
CM_ SG_ 258 ESP_Status_Anfahrhilfe "Funktionsstatus des Berganfahrassistenten
MQB: Auswertung im Getriebe zwecks Standabkopplung";
CM_ SG_ 258 ESP_Status_Bremsdruck "MLB: Bei gesetztem Bit liegt p > ca. 2 bar an, hervorgerufen durch Fahrer, ASR, FZR, ECD, Bremsregler ... bei Abfall des Bits ist p < X bar, bei aktivem ECD-Eingriff Ende des Eingriffs 

Weiterführende Informationen im Lastenheft spezifiziert und in der";
CM_ SG_ 258 ESP_Status_Bremsentemp "ECD-Bremsscheibentemperaturmodell. Rückmeldung für Sender einer ECD Verzögerungsanforderung, ohne Fehlereintrag im ESP";
CM_ SG_ 258 ESP_Status_Bremsentemp_02 "Bremsscheibentemperaturmodell. Rückmeldung für Sender einer Verzögerungsanforderung";
CM_ SG_ 258 ESP_Status_ESP_PLA "Zustand der Statusmaschine der Bremse für die korrespondierende Statusmaschine in dem PLA-SG";
CM_ SG_ 258 ESP_Stillstandsphase_erschoepft "Rückmeldung vom ESP, dass eine angefordertes sicheres Halten im Stillstand nicht mehr länger möglich ist.";
CM_ SG_ 258 ESP_Systemstatus_03 "ESC-Status für Datenablage im EDR";
CM_ SG_ 258 ESP_Tuerkontakt_Fahrertuer "Logischer Pegel der HW-Leitung zum Türkontaktschalter im ESP-SG.
0 > Schalter geschlossen
1 > Schalter offen

Ungefilterter und unplausibilisierter Status der HW-Leitung vom Fahrertür-Türkontaktschalter zum ESP.
Redundanz für Systemsicherheit notwend";
CM_ SG_ 258 ESP_v_ref "MLBevo:
Signal wird nur von einem BOSCH ESP System zur Verfügung gestellt. Exklusives Signal vom BOSCH ESP zum BOSCH Airbag für ROSEII Funktion und für Fahrwerkregelsysteme. 
Verwendung nur nach vorheriger Abstimmung mit den verantwortlichen EF Fachbere";
CM_ SG_ 258 ESP_v_ref_Fahrtrichtung "Signal stellt die Informationen über die Fahrtrichtung des Fahrzeuges dar. Sie wird als Vorzeichen der Referenzgeschwindigkeit ESP_v_ref interpretiert und basiert auf den Drehrichtungen der Räder.
Detailinformationen zu dem Signal sind dem Lastenheft 'Si";
CM_ SG_ 258 ESP_Verz_EPB_aktiv "Bei gesetztem Bit wird die Verzögerungsanforderung von EPB umgesetzt.";
CM_ SG_ 258 ESP_Verz_TSK_aktiv "Rückmeldeinformation an den Triebsstrangkoordinator/ACC, dass die ECD-Verzögerungsanforderung aktuell umgesetzt wird";
CM_ SG_ 258 ESP_Verzoeg_EPB_verf "Bei gesetztem Bit ist der Verzögerungsregeler für EPB verfügbar.";
CM_ SG_ 258 ESP_VZ_Gierrate "Vorzeichen der Gierrate";
CM_ SG_ 258 ESP_ZT_Rueckk_Umsetz "Das Signal dient als Rückmeldung zum ACC, dass eine angeforderte Zielbremsung/Teilbremsung durchgeführt wird. Die positive Rückmeldung löst u.a. eine entsprechende Fahrerinformation im Kombiinstrument aus";
CM_ SG_ 258 SOK_ESC_50_Signatur "Signatur im Rahmen der durch SOK geschützten Broadcast-Kommunikation
Geschützte Funktionen: Airbag-Funktionen, EML, versch. Bremsfunktionen
Geschützte Botschaft: ESC_50";

CM_ SG_ 885 ESC_54_BZ "4bit Botschaftszähler, wird mit jeder Sendebotschaft inkrementiert";
CM_ SG_ 885 SOK_ESC_54_Signatur "Signatur im Rahmen der durch SOK geschützten Broadcast-Kommunikation

Geschützte Funktion: Wegstreckensicherheit
Geschützte Signale: SSO_EdgeCount_Sum";
CM_ SG_ 885 SSO_EdgeCount_Sum "sum of the average of the counters of the rear wheels";

CM_ SG_ 2589283575 ESI_DRemOilChg "Remaining distance until oil change matures";
CM_ SG_ 2589283575 ESI_StOilChg "Status of oil change";
CM_ SG_ 2589283575 ESI_TiRemOilChg "Time remaining until oil change matures";

CM_ SG_ 278 ESP_10_BZ "Botschaftszähler

Wird im Projekt D4 und D4Hybrid nicht verwendet!  Wird im D4 PA verwendet
Botschaft asynchron geroutet. Zählerwert kann springen.";
CM_ SG_ 278 ESP_10_CRC "Für MLB:
'Berechnung siehe Lastenheft 'Kommunikationsabsicherung für FlexRay und CAN''

Ab MQB und MLBevo:
'Berechnung siehe Lastenheft 'End-to-End Kommunikationsabsicherung''

Endwerte siehe Begleitdokument 'S-PDU Kennungsfolgen'

Wird im Projekt";
CM_ SG_ 278 ESP_HL_Fahrtrichtung "Drehrichtung Rad HL

Weiterführende Informationen im Lastenheft spezifiziert und in der entsprechenden Fachabteilung zu erfragen.

Wird im Projekt D4 und D4Hybrid nicht verwendet!  Wird im D4 PA verwendet";
CM_ SG_ 278 ESP_HR_Fahrtrichtung "Drehrichtung Rad HR

Weiterführende Informationen im Lastenheft spezifiziert und in der entsprechenden Fachabteilung zu erfragen.

Wird im Projekt D4 und D4Hybrid nicht verwendet!  Wird im D4 PA verwendet";
CM_ SG_ 278 ESP_QBit_Wegimpuls_HL "Qualifizierungsbit Wegimpulszähler HL

Wird im Projekt D4 und D4Hybrid nicht verwendet!  Wird im D4 PA verwendet";
CM_ SG_ 278 ESP_QBit_Wegimpuls_HR "Qualifizierungsbit Wegimpulszähler HR

Wird im Projekt D4 und D4Hybrid nicht verwendet!  Wird im D4 PA verwendet";
CM_ SG_ 278 ESP_QBit_Wegimpuls_VL "Qualifizierungsbit Wegimpulszähler VL

Wird im Projekt D4 und D4Hybrid nicht verwendet!  Wird im D4 PA verwendet";
CM_ SG_ 278 ESP_QBit_Wegimpuls_VR "Qualifizierungsbit Wegimpulszähler VR

Wird im Projekt D4 und D4Hybrid nicht verwendet!  Wird im D4 PA verwendet";
CM_ SG_ 278 ESP_VL_Fahrtrichtung "Drehrichtung Rad VL

Weiterführende Informationen im Lastenheft spezifiziert und in der entsprechenden Fachabteilung zu erfragen.

Wird im Projekt D4 und D4Hybrid nicht verwendet!  Wird im D4 PA verwendet";
CM_ SG_ 278 ESP_VR_Fahrtrichtung "Drehrichtung Rad VR

Weiterführende Informationen im Lastenheft spezifiziert und in der entsprechenden Fachabteilung zu erfragen.

Wird im Projekt D4 und D4Hybrid nicht verwendet!  Wird im D4 PA verwendet";
CM_ SG_ 278 ESP_Wegimpuls_HL "Wegimpulszähler HL.
Anzahl der Wegimpulse Hinterrad links (steigende und fallende Flanke)
Zähler läuft grundsätzlich vorwärts, auch bei Rückwärtsfahrt.
Nach SG-Reset ist immer, ohne Ausnahme, 1mal der Init Wert 1021 zu senden.

Wird im Projekt D4 und";
CM_ SG_ 278 ESP_Wegimpuls_HR "Wegimpulszähler HR.
Anzahl der Wegimpulse Hinterrad rechts (steigende und fallende Flanke)
Zähler läuft grundsätzlich vorwärts, auch bei Rückwärtsfahrt.
Nach SG-Reset ist immer, ohne Ausnahme, 1mal der Init Wert 1021 zu senden.

Wird im Projekt D4 un";
CM_ SG_ 278 ESP_Wegimpuls_VL "Wegimpulszähler VL.
Anzahl der Wegimpulse Vorderrad links (steigende und fallende Flanke)
Zähler läuft grundsätzlich vorwärts, auch bei Rückwärtsfahrt.
Nach SG-Reset ist immer, ohne Ausnahme, 1mal der Init Wert 1021 zu senden.

Wird im Projekt D4 und";
CM_ SG_ 278 ESP_Wegimpuls_VR "Wegimpulszähler VR.
Anzahl der Wegimpulse Vorderrad rechts (steigende und fallende Flanke)
Zähler läuft grundsätzlich vorwärts, auch bei Rückwärtsfahrt.
Nach SG-Reset ist immer, ohne Ausnahme, 1mal der Init Wert 1021 zu senden.

Wird im Projekt D4 un";

CM_ SG_ 178 ESP_HL_Radgeschw_02 "Radgeschwindigkeit hinten links";
CM_ SG_ 178 ESP_HR_Radgeschw_02 "Radgeschwindigkeit hinten rechts";
CM_ SG_ 178 ESP_VL_Radgeschw_02 "Radgeschwindigkeit vorne links";
CM_ SG_ 178 ESP_VR_Radgeschw_02 "Radgeschwindigkeit vorne rechts";

CM_ SG_ 1629 BR_QBit_Reifenumfang "Gesetzt bei Ersatzwert, Init oder Fehler.";
CM_ SG_ 1629 BR_Reifenumfang "Mittlerer Radumfang gerechnet in Millimeter.
Von der Bremse plausibilisierter Wert (Kopie von KBI_Reifenumfang wenn dieser plausibel) oder Ersatzwert aus Bremse wenn KBI_Reifenumfang unplausibel. Bitte das QBit beachten!

Im MEB wird das Signal KBI_Rei";
CM_ SG_ 1629 BR_Systemart "Identifikation des verbauten Bremssystems

Dient dem Kombi zur Plausibilisierung";
CM_ SG_ 1629 ESP_20_CRC "Für MLB:
'Berechnung siehe Lastenheft 'Kommunikationsabsicherung für FlexRay und CAN''

Ab MQB und MLBevo:
'Berechnung siehe Lastenheft 'End-to-End Kommunikationsabsicherung''

Endwerte siehe Begleitdokument 'S-PDU Kennungsfolgen'";
CM_ SG_ 1629 ESP_Charisma_FahrPr "MLBevo: Aktuelles Fahrprogramm des Charisma-Teilnehmers (siehe Systemlastenheft Drive Select)
MQB: Istwert der Kennlinie (siehe Systemlastenheft MQB FPA)";
CM_ SG_ 1629 ESP_Charisma_Status "Systemstatus des Charismateilnehmers

Wert 0x3 ist nur für Fahrzeuge ab MQB relevant";
CM_ SG_ 1629 ESP_Dachrelingsensor "Erkennung auf Verbau des Dachrelingsensors und Dachquerträger.";
CM_ SG_ 1629 ESP_SpannungsAnf_02 "Forderung des ESP-SG's zur Spannungsanhebung.";
CM_ SG_ 1629 ESP_Stoppverbot_Anz_01 "Dieses Signal gibt die detaillierte Begründung für ein Stoppverbot vom Bremsensteuergerät an.";
CM_ SG_ 1629 ESP_Stoppverbot_Anz_02 "Dieses Signal gibt die detaillierte Begründung für ein Stoppverbot vom Bremsensteuergerät an.";
CM_ SG_ 1629 ESP_Stoppverbot_Anz_03 "Dieses Signal gibt die detaillierte Begründung für ein Stoppverbot vom Bremsensteuergerät an.";
CM_ SG_ 1629 ESP_Stoppverbot_Anz_04 "Dieses Signal gibt die detaillierte Begründung für ein Stoppverbot vom Bremsensteuergerät an.";
CM_ SG_ 1629 ESP_Stoppverbot_Anz_05 "Dieses Signal gibt die detaillierte Begründung für ein Stoppverbot vom Bremsensteuergerät an.";
CM_ SG_ 1629 ESP_Stoppverbot_Anz_06 "Dieses Signal gibt die detaillierte Begründung für ein Stoppverbot vom Bremsensteuergerät an.";
CM_ SG_ 1629 ESP_Stoppverbot_Anz_07 "Dieses Signal gibt die detaillierte Begründung für ein Stoppverbot vom Bremsensteuergerät an.";
CM_ SG_ 1629 ESP_Stoppverbot_Anz_08 "Dieses Signal gibt die detaillierte Begründung für ein Stoppverbot vom Bremsensteuergerät an.";
CM_ SG_ 1629 ESP_Stoppverbot_Anz_Std "Dieses Signal gibt die detaillierte Begründung für ein Stoppverbot vom Bremsensteuergerät an.";
CM_ SG_ 1629 ESP_Wiederstart_Anz_01 "Dieses Signal gibt die detaillierte Begründung für einen Wiederstart vom Bremsensteuergerät an. ";
CM_ SG_ 1629 ESP_Wiederstart_Anz_02 "Dieses Signal gibt die detaillierte Begründung für einen Wiederstart vom Bremsensteuergerät an. ";
CM_ SG_ 1629 ESP_Wiederstart_Anz_03 "Dieses Signal gibt die detaillierte Begründung für einen Wiederstart vom Bremsensteuergerät an. ";
CM_ SG_ 1629 ESP_Wiederstart_Anz_04 "Dieses Signal gibt die detaillierte Begründung für einen Wiederstart vom Bremsensteuergerät an.";
CM_ SG_ 1629 ESP_Zaehnezahl "Konstanter Wert der Zähnezahl des verwendeten Impulsrades wird ausgegeben, jeder Empfänger der Wegimpulse muss die Zähnezahl einlesen, um eine volle Umdrehung des Rades zu erkennen. 

Weiterführende Informationen im Lastenheft spezifiziert und in der en";
CM_ SG_ 1629 HDC_Charisma_FahrPr "MLBevo: Aktuelles Fahrprogramm des Charisma-Teilnehmers (siehe Systemlastenheft Drive Select)
MQB: Istwert der Kennlinie (siehe Systemlastenheft MQB FPA)";
CM_ SG_ 1629 HDC_Charisma_Status "Systemstatus des Charismateilnehmers

Wert 0x3 ist nur für Fahrzeuge ab MQB relevant";

CM_ SG_ 253 ABS_Bremsung "Antiblockiersystem, Bit zeigt auch Druckabbau an (z.B. ESP hat zuviel Druck aufgebaut oder ungebremste Regelung auf Bahnübergang)
Weiterführende Informationen im Lastenheft spezifiziert und in der entsprechenden Fachabteilung zu erfragen.";
CM_ SG_ 253 ASR_Anf "MLB: Die Momentenanforderung 'ASR_MSR_Moment_schnell' und 'ASR_Moment_langsam' sind auszuführen
MQB: Die Momentenanforderung 'BR_Eingriffsmoment' ist auszuführen";
CM_ SG_ 253 ASR_Schalteingriff "Wunsch an das Getriebe während einer ASR Regelung

MLB: Es wird nur 0x0 und 0x1 genutzt

";
CM_ SG_ 253 ASR_Tastung_passiv "ASR deaktiviert oder Schwellen geändert (projektabhängig)
Weiterführende Informationen im Lastenheft spezifiziert und in der entsprechenden Fachabteilung zu erfragen.
";
CM_ SG_ 253 BR_Eingriffsmoment "Einheitenloser Wert! Faktor in MO_Faktor_Momente_02 in Motor_Code_01 beachten!
Schnelle reduzierende (ASR) oder erhöhende (MSR) Momentanforderung an den Motor.";
CM_ SG_ 253 EBV_Eingriff "Elektronische Bremskraftverteilung, aktueller Eingriff (Druckhalten, Druckabbau)

Im MLB: kein ABS / ESP-Eingriff ???";
CM_ SG_ 253 EDS_Eingriff "Elektronische Differentialsperre";
CM_ SG_ 253 ESC_Reku_Freigabe "Mit diesem Bit wird die Rekuperation im Motorsteuergerät erlaubt. Bei Ausfall ESC wird Rekuperation nicht freigegeben.

MQB/MQB2020: Wird nur von einem blendfähigen ESC unterstützt, wie es in mHEV und pHEV Fahrzeugen eingesetzt wird.";
CM_ SG_ 253 ESC_v_Signal_Qualifier_High_Low "Das Qualifizerungssignal ESC_v_Signal_Qualifier_High_Low gibt eine Information über die Güte der vom Bremsregelsystem ausgegebenen Geschwindigkeitsinformation 'mittlere Geschwindigkeit', wobei Vertrauensbereiche für das ausgegebene Geschwindigkeitssignal ";
CM_ SG_ 253 ESP_21_CRC "Für MLB:
'Berechnung siehe Lastenheft 'Kommunikationsabsicherung für FlexRay und CAN''

Ab MQB und MLBevo:
'Berechnung siehe Lastenheft 'End-to-End Kommunikationsabsicherung''

Endwerte siehe Begleitdokument 'S-PDU Kennungsfolgen'";
CM_ SG_ 253 ESP_Anhaltevorgang_ACC_aktiv "Zeigt an, ob ACC-Anhaltevorgang aktiv";
CM_ SG_ 253 ESP_ASP "MLB: Anhaenger-Stabilisierungs-Programm
MQB: Gespannstabilisierung";
CM_ SG_ 253 ESP_AWV3_Brems_aktiv "Teil-, Ziel- oder Notbremsung wird im ESP für AWV3 umgesetzt (das MSG nutzt diese Info für den Abwurf der GRA-Regelung).";
CM_ SG_ 253 ESP_Diagnose "MLB: Nach Diagnoseende wird ein SW-Reset ausgelöst welcher einen Kommunikatiosausfall für max. 150ms verursacht. Dies ist bei SG mit verschärfter Timeoutüberwachung (nicht nach Konzern-LH) zu beachten.

MQB: Weiterführende Informationen im Lastenheft sp";
CM_ SG_ 253 ESP_Eingriff "Eingriff des Fahrdynamikreglers";
CM_ SG_ 253 ESP_Haltebestaetigung "Rückmeldung vom ESP-SG, dass das Fahrzeug aufgrund einer externen Bremsanforderung (z. B. ACC, PLA, ANB, o. ä.) abgebremst wurde und im Stillstand gehalten wird.";
CM_ SG_ 253 ESP_MKB_Abbruch_Geschw "Im Falle einer Multikollisionsbremsung teilt das ESP den Abbruch der MKB aufgrund der unteren Geschwindigkeitsschwelle mit.";
CM_ SG_ 253 ESP_PLA_Bremseingriff "Signalisierung des aktiven Bremseingriffes des ESP aufgrund einer Bremsanforderung vom PLA.";
CM_ SG_ 253 ESP_QBit_v_Signal "Geschwindigkeit wird vom ABS/ASR oder ESP aus Ersatzwerten errechnet, wenn Bit gesetzt ist. Güte des Signals ist verändert.";
CM_ SG_ 253 ESP_Systemstatus "Fehler steht für Stillegung ESP mit Fehlereintrag.

MLB: Flag wird bei Unterspannung im Stand bis einmalig 6km/h (AU48x) oder 10 km/h (AU641, AU57x) überschritten nicht gesetzt (Ausblendung Startvorgang)
Im AU64x, AU57x gilt ESP D4 Funktionsanforderung";
CM_ SG_ 253 ESP_Tastung_passiv "ESP deaktiviert oder Schwellen geändert (projektabhängig)
Weiterführende Informationen im Lastenheft spezifiziert und in der entsprechenden Fachabteilung zu erfragen.";
CM_ SG_ 253 ESP_v_Signal "Geschwindigkeitssignal vom ABS/ASR oder ESP. Mittelwert der angetriebenen Räder.
Bei MSR oder ABS Eingriffen wird die ABS-Referenzgeschwindigkeit für >= 200ms eingespiegelt (Zeit wird mit Aktiv-Flanke der Funktionsbits getriggert)

MQB: Bei Frontantrie";
CM_ SG_ 253 ESP_Vorsteuerung "zur Unterscheidung zwischen ESP-Vorsteuermaßnahmen und ESP-Regeleingriffen";
CM_ SG_ 253 MSR_Anf "MLB: Die Momentenanforderung 'ASR_MSR_Moment_schnell' ist auszuführen.
MQB: Die Momentenanforderung 'BR_Eingriffsmoment' ist auszuführen";
CM_ SG_ 253 OBD_Schlechtweg "Für Ausblendung der Zündaussetzererkennung im Motorsteuergerät (Otto). Bit wird gesetzt, wenn Rad-Drehbeschleunigung im ESP > Grenzwert ist. Vorteil gegenüber Radgeschwindigkeiten, dass ESP alle 2 ms dynamisch die Rad-Drehbeschleunigung errechnet und dem ";

CM_ SG_ 795 ABS_Lampe "Sicherheitswarnlampe

Weiterführende Informationen im Lastenheft spezifiziert und in der entsprechenden Fachabteilung zu erfragen.";
CM_ SG_ 795 BK_Lampe_02 "Typ1_ein_statisch signalisiert EBV-Ausfall
MQB: wird auch bei HBV-Ausfall verwendet.

Typ1_ein_statisch: wird bei AUDI für Aktivierung der roten BKL ohne Text und Akustik verwendet (z.B. Lampenaufprüfung).
Typ2_ein_statisch: signalisiert elektrischen ";
CM_ SG_ 795 ESP_24_CRC "Für MLB:
'Berechnung siehe Lastenheft 'Kommunikationsabsicherung für FlexRay und CAN''

Ab MQB und MLBevo:
'Berechnung siehe Lastenheft 'End-to-End Kommunikationsabsicherung''

Endwerte siehe Begleitdokument 'S-PDU Kennungsfolgen'";
CM_ SG_ 795 ESP_BKV_Warnung "ESP sendet im Hinweis- /Störungsfall an das Kombi Informationen zum Anzeigen (Text + Akustik)

Im MQB wird dieses Signal nicht unterstützt!
";
CM_ SG_ 795 ESP_Fehlerstatus_Wegimp "Weiterführende Informationen im Lastenheft spezifiziert und in der entsprechenden Fachabteilung zu erfragen.

MLB: Fehler wird gesetzt, wenn beide ESP-Drehzahlfühler an der Vorderachse defekt sind.

MQB: Fehler wird gesetzt, wenn beide Raddrehzahlfühl";
CM_ SG_ 795 ESP_HDC_FktLampe "Funktionslampe Bergabfahrassistent.
(Sender blinkt mit dem Bit 3,3Hz)";
CM_ SG_ 795 ESP_HDC_Regelgeschw "Verwendung/Bedienung nur im AU57x Allroad:
HDC-Geschwindigkeit
Dient der Anzeige der HDC-Geschwindigkeit und eines Bergabfahrsymbols im Kombi.
HDC-Standby wird gesetzt sobald der Fahrer den HDC-Taster aktiviert hat.
Bei HDC-Off oder während der Initia";
CM_ SG_ 795 ESP_Lampe "Zustand der Fahrdynamikregelungslampe (MLB: ASR und/oder ESP, MQB: nur ESP)

Weiterführende Informationen im Lastenheft spezifiziert und in der entsprechenden Fachabteilung zu erfragen.";
CM_ SG_ 795 ESP_m_Raddrehz "Radumdrehungen pro Sekunde sind Eingangsgröße für die Geschwindigkeitsberechnung im Kombi. Aus dieser Raddrehzahl und dem Radumfang wird die Fahrzeuggeschwindigkeit errechnet.

MLB: Exklusiver Empfänger ist das Kombiinstrument!
MQB: Bei Frontantrieb un";
CM_ SG_ 795 ESP_Meldungen "ESP sendet im Hinweis- /Störungsfall an das Kombi Informationen zum Anzeigen

Weiterführende Informationen im Lastenheft spezifiziert und in der entsprechenden Fachabteilung zu erfragen.
Ergänzender Hinweis:
1 = Autohold_Hinweis_1 (Anfahrassistent: nu";
CM_ SG_ 795 ESP_Off_Lampe "Bit zur Ansteuerung der separaten ESP-off-Lampe im Kombi (Gesetzesforderung USA)

MLB:
Verwendung/Bedienung ab D4";
CM_ SG_ 795 ESP_QBit_Wegimp_VA "Gesetzt bei Ersatzwert, Init oder Fehler.";
CM_ SG_ 795 ESP_Textanzeigen_03 "Textanzeigen der Fahrdynamikregelung im Kombiinstrument

Weiterführende Informationen im Lastenheft spezifiziert und in der entsprechenden Fachabteilung zu erfragen.

Der Signalwert 24 wird nur im BY736 verwendet.";
CM_ SG_ 795 ESP_Wegimp_Ueberlauf "Der Wegimpulszähler ist pro Zündungslauf mindestens einmal übergelaufen

Weiterführende Informationen im Lastenheft spezifiziert und in der entsprechenden Fachabteilung zu erfragen.";
CM_ SG_ 795 ESP_Wegimp_VA "Weiterführende Informationen im Lastenheft spezifiziert und in der entsprechenden Fachabteilung zu erfragen.

MLB: Die Wegimpulse Vorderachse sind die gemittelten Werte (reine mathematische Operation: Addition und Division durch zwei, keine Filterung) d";
CM_ SG_ 795 TC_Lampe "M-ABS Lampe (separate Lampe für M-ABS-Systeme Markt Brasilien)

Weiterführende Informationen im Lastenheft spezifiziert und in der entsprechenden Fachabteilung zu erfragen.";

CM_ SG_ 2589283617 DBK_Fahrerwarnung "Warnt den Fahrer bei erkannter Dampfblase in der Bremsflüssigkeit und fordert ihn zum Anhalten sowie Werkstattbesuch auf (2 Bit):
0: kein Anfordern (Initwert)
1: Warnereignis 1 - fordert Warnlampe, Warnmeldung (Aufforderung Anhalten) und Warnton sowie F";
CM_ SG_ 2589283617 EDS_Charisma_FahrPr "Aktuelles Fahrprogramm des Charisma-Teilnehmers Elektronische Differentialsperre EDS";
CM_ SG_ 2589283617 EDS_Charisma_Status "Systemstatus des Charismateilnehmers Elektronische Differentialsperre EDS";
CM_ SG_ 2589283617 ESC_Anf_KL "Nachricht an Motor- bzw. Antriebssteuergerät zur Festlegung der Motorluefterdrehzahl
Angabe in Prozent der Maximaldrehzahl";
CM_ SG_ 2589283617 ESC_Anf_KV "Nachricht an Motor bzw. Antriebssteuergerät zum Öffnen der Kühlerjalousie.";
CM_ SG_ 2589283617 ESC_FBA_Meldungen "Hinweis an den Fahrer über das Kombi, bei dauerhafter Bergabfahrt einen Gang einzulegen um die Motorbremse zu nutzen.
Unterscheidung zwischen: 
Handschalterfahrzeugen (FBA_Warnung_aktiv_MT)
Automatikfahrzeugen (FBA_Warnung_aktiv_AT)";
CM_ SG_ 2589283617 ESC_Lernfreigabe_Abrollumfang "Meldet einen Fahrdynamikzustand, der es zulässt, dass der Abrollumfang der Räder genauer errechnet werden darf.
Die Verwendung des Signals ist ausschließlich für die MQB-Plattform zugelassen.";
CM_ SG_ 2589283617 ESC_MBK_Meldungen "Das Signal steuert die Schaltempfehlung im Kombi, die bei Bergabfahrt den Fahrer darauf hinweist in eine geeignete Fahrstufe zu schalten um eine Rekuperation zu ermöglichen.";
CM_ SG_ 2589283617 ESC_Texte_eBKV_Betaetigung "Anweisungen an den Fahrer für die Betätigung der Bremse über den eBKV unter Verwendung der Schaltwippen am Lenkrad.";
CM_ SG_ 2589283617 ESP_30_BZ "4bit Botschaftszähler, wird mit jeder Sendebotschaft inkrementiert";
CM_ SG_ 2589283617 ESP_30_CRC "Für MLB:
Berechnung siehe Lastenheft 'Kommunikationsabsicherung für FlexRay und CAN'
Ab MQB und MLBevo:
Berechnung siehe Lastenheft 'End-to-End Kommunikationsabsicherung'

Endwerte siehe Begleitdokument 'S-PDU Kennungsfolgen'";
CM_ SG_ 2589283617 ESP_Off_Anf_KBI "Anzeige ESP Off Bestätigungsaufforderung";
CM_ SG_ 2589283617 ESP_Status_Bremsentemp_Anz "Anzeigesignal für Bremsentemperatur";
CM_ SG_ 2589283617 FBC_Fahrerwarnung "Warnt den Fahrer bei aktiver FBC-Funktion vor heißer Bremsanlage aufgrund Fading und fordert ihn zum 'langsam weiterfahren' auf.";
CM_ SG_ 2589283617 HHC_Charisma_FahrPr "Aktuelles Fahrprogramm des Charisma-Teilnehmers Berganfahrassistent HHC";
CM_ SG_ 2589283617 HHC_Charisma_Status "Systemstatus des Charismateilnehmers Berganfahrassistent HHC";
CM_ SG_ 2589283617 RLE_Anzeigen "Anzeigen für die Radlöseerkennung";

CM_ SG_ 707 eAWS_Warnmeldung_Prio3 "Signal zur Ansteuerung der Prio3 Warnmeldung für das eAWS im Kombi";
CM_ SG_ 707 EFP_Anf_Kuehlklappenwarnung "Signal wird zur Ansteuerung einer Kühlklappenwarnung im Kombiinstrument genutzt";
CM_ SG_ 707 FA_Warnung_Transportniveau "Signal zur Ansteuerung einer Warnmeldung, wenn beim Transportmodus das Zielniveau nicht angefahren wird";
CM_ SG_ 707 FDR_M_HL_02 "Momentenanzeige für MMI.";
CM_ SG_ 707 FDR_M_HR_02 "Momentenanzeige für MMI.";
CM_ SG_ 707 FDR_M_VL_02 "Momentenanzeige für MMI.";
CM_ SG_ 707 FDR_M_VR_02 "Momentenanzeige für MMI.";

CM_ SG_ 2589283684 FoD_Transmission_Info "Mit dem Signal zeigt der FoD-Master allen FoD-Slaves den Beginn und das Ende eines Freischaltuebertragungszykluses (FS-ID-Zyklus) an.";
CM_ SG_ 2589283684 GRA_FoD_Status "Verortung des FOD-Slaves für die Funktion GRA erfolgt im Gateway. Signal übermittelt den FOD-Status an das MSG.";

CM_ SG_ 2549875476 FoD_Kombi_Req_Data "Function on demand request an Kombiinstrument";

CM_ SG_ 2550006548 FoD_Kombi_Resp_Data "Function on demand response vom Kombiinstrument";

CM_ SG_ 2549875500 FoD_MFG_Req_Data "FoD - Function On Demand
ISO-TP Datenkanal 
Request Funktion 0x03 FoD-Master

FoD-Master an KFG";

CM_ SG_ 2550006572 FoD_MFG_Resp_Data "FoD - Function On Demand
ISO-TP Datenkanal 
Response Knoten 0x3D KFG

KFG an FoD Master";

CM_ SG_ 986 ABS_Bremsung "Antiblockiersystem, Bit zeigt auch Druckabbau an (z.B. ESP hat zuviel Druck aufgebaut oder ungebremste Regelung auf Bahnübergang)
Weiterführende Informationen im Lastenheft spezifiziert und in der entsprechenden Fachabteilung zu erfragen.";
CM_ SG_ 986 ECD_Bremslicht "Bremslichtansteuerung durch ECD-Funktion";
CM_ SG_ 986 EPB_Pedalweg_Kuppl "Signal entspricht Tastverhältnis des PWM. Gesamtweg Kupplungspedal 10% bis 90%, damit zu erwartende Werte 25 bis 225. 25 bei Kupplungspedal nicht getreten, 225 bei Kupplungspedal voll durchgetreten.
2% Toleranz wird im Wertebereich ermöglicht (8%-92%).
";
CM_ SG_ 986 EPB_Status "Gibt den Zustand der EPB-Aktuatoren an.

Nur VW526/PAG E2: Wert 0x3 bedeutet 'unbekannt'

";
CM_ SG_ 986 ESP_Eingriff "Eingriff des Fahrdynamikreglers";
CM_ SG_ 986 ESP_HDC_Standby "Verwendung/Bedienung im MQB und AU57x Allroad:
Flag wird vom ESP gesetzt, wenn über den HDC-Taster die HDC-Funktion eingeschalten wurde";
CM_ SG_ 986 ESP_MKB_Abbruch_Geschw "Im Falle einer Multikollisionsbremsung teilt das ESP den Abbruch der MKB aufgrund der unteren Geschwindigkeitsschwelle mit.";
CM_ SG_ 986 ESP_QBit_v_Signal "Geschwindigkeit wird vom ABS/ASR oder ESP aus Ersatzwerten errechnet, wenn Bit gesetzt ist. Güte des Signals ist verändert.";
CM_ SG_ 986 ESP_v_Signal "Geschwindigkeitssignal vom ABS/ASR oder ESP. Mittelwert der angetriebenen Räder.
Bei MSR oder ABS Eingriffen wird die ABS-Referenzgeschwindigkeit für >= 200ms eingespiegelt (Zeit wird mit Aktiv-Flanke der Funktionsbits getriggert)

MQB: Bei Frontantrie";
CM_ SG_ 986 Kamera_FSH_aktiv "Bei aktivierter (lokaler) Frontscheibenheizung wird die Scheibentemperaturmessung des Klimafeuchtesensors beeinflusst. Über das Signal wird dem Klima-SG mitgeteilt, dass die lokale Scheibenheizung aktiviert ist, um entsprechende Korrekturwerte bei der Sch";
CM_ SG_ 986 LWI_Lenkradwinkel "Wertebereich = +/- 800 Grad
Auflösung = 0,1 Grad
ACHTUNG: spezifizierte Interne Auflösung des Sensors beträgt aber nur Schrittweite 0,5 Grad!

Hinweis:
MLB: Zusätzlich gestellte Winkel bei Dynamiklenkung beachten !
MQB: Nicht konstante Lenkübersetzu";
CM_ SG_ 986 LWI_QBit_Lenkradwinkel "Das QBit wird auch bei nicht abgeglichenem Lenkradwinkelsensor gesetzt";
CM_ SG_ 986 LWI_VZ_Lenkradwinkel "Vorzeichen Lenkradwinkel gemäss DIN70000; 
Nullstellung = +0";
CM_ SG_ 986 PH_Anf_Audioabsenkung "Es gibt zwei unterschiedliche Nachlauftimer für dieses Bit:
1. normale Funktion
2. Demotonausgabe";
CM_ SG_ 986 PH_Systemzustand "Aktivierungsursache wird für die Dauer der Aktivierung gemeldet.
Im Fehlerfall bei atkviem System wechselt das Signal auf '7'
(siehe auch 'Abschaltursache')";
CM_ SG_ 986 PH_Taster "Taster Status (für RVC/TopView)";
CM_ SG_ 986 PLA_Anf_Aufschaltung_RVC "Anforderung der Aufschaltung RVC durch PLA";
BA_DEF_REL_ BU_SG_REL_  "GenSigTimeoutTime" INT 0 65535;
BA_DEF_ BO_  "DiagRequest" ENUM "No", "Yes";
BA_DEF_ BO_  "DiagResponse" ENUM "No", "Yes";
BA_DEF_ BO_  "DiagState" ENUM "No", "Yes";
BA_DEF_ BO_  "GenMsgChkConstant" HEX 0 4095;
BA_DEF_ BO_  "GenMsgCycleTime" INT 0 65535;
BA_DEF_ BO_  "GenMsgCycleTimeFast" INT 0 65535;
BA_DEF_ BO_  "GenMsgDelayTime" INT 0 100000;
BA_DEF_ BO_  "GenMsgILSupport" ENUM "No", "Yes";
BA_DEF_ BO_  "GenMsgNrOfRepetition" INT 0 100;
BA_DEF_ BO_  "GenMsgPDUConstants" STRING;
BA_DEF_ BO_  "GenMsgSendType" ENUM "Cyclic", "not_used", "not_used", "not_used", "not_used", "not_used", "not_used", "IfActive", "NoMsgSendType";
BA_DEF_ BO_  "GenMsgStartDelayTime" INT 0 100000;
BA_DEF_ BO_  "NmMessage" ENUM "No", "Yes";
BA_DEF_ BO_  "NmhMessage" ENUM "No", "Yes";
BA_DEF_ BO_  "MsgType" ENUM "Application", "NM ", "NMH", "TP2.0", "ISO-TP ", "BAP", "EID", "KS", "XCP_PRE_CONFIGURED", "XCP_RUNTIME_CONFIGURED";
BA_DEF_ BO_  "VAGTP20_API" HEX 0 255;
BA_DEF_ BO_  "VAGTP20_DynConnection" ENUM "No", "Yes";
BA_DEF_ BO_  "VAGTP20_DynSetup" ENUM "No", "Yes";
BA_DEF_ BO_  "VAGTP20_StatConnection" ENUM "No", "Yes";
BA_DEF_ BO_  "CANFD_BRS" ENUM "0", "1";
BA_DEF_ BO_  "VFrameFormat" ENUM "StandardCAN", "ExtendedCAN", "reserved", "reserved", "reserved", "reserved", "reserved", "reserved", "reserved", "reserved", "reserved", "reserved", "reserved", "reserved", "StandardCAN_FD", "ExtendedCAN_FD";
BA_DEF_ SG_  "GenSigActiveRepetitions" INT -2147483648 2147483647;
BA_DEF_ SG_  "GenSigInactiveValue" INT -2147483648 2147483647;
BA_DEF_ SG_  "GenSigSendType" ENUM "Cyclic", "OnWrite", "OnWriteWithRepetition", "OnChange", "OnChangeWithRepetition", "IfActive", "IfActiveWithRepetition", "NoSigSendType", "OnChangeAndIfActive", "OnChangeAndIfActiveWithRepetition";
BA_DEF_ SG_  "GenSigStartValue" INT -2147483648 2147483647;
BA_DEF_ SG_  "NWM-WakeupAllowed" ENUM "No", "Yes";
BA_DEF_ SG_  "GenSigFuncType" ENUM "NoFunction", "MsgCounter", "CRC-8", "XOR", "XOR-2", "DatedBit", "SW-Kl15", "CHK", "Constant", "Protocol", "CRC-8-SAE_J1850", "CRC-32", "DataLength", "DataID", "MsgCounter16", "SOK-Signatur", "Cluster";
BA_DEF_ SG_  "GenSigSwitchedByIgnition" ENUM "No", "Yes";
BA_DEF_ SG_  "Fehlerwert" HEX 0 2147483647;
BA_DEF_ SG_  "GenSigMissingSourceValue" HEX 0 2147483647;
BA_DEF_DEF_REL_  "GenSigTimeoutTime" 0;
BA_DEF_DEF_  "DiagRequest" "No";
BA_DEF_DEF_  "DiagResponse" "No";
BA_DEF_DEF_  "DiagState" "No";
BA_DEF_DEF_  "GenMsgChkConstant" 0;
BA_DEF_DEF_  "GenMsgCycleTime" 0;
BA_DEF_DEF_  "GenMsgCycleTimeFast" 0;
BA_DEF_DEF_  "GenMsgDelayTime" 0;
BA_DEF_DEF_  "GenMsgILSupport" "No";
BA_DEF_DEF_  "GenMsgNrOfRepetition" 0;
BA_DEF_DEF_  "GenMsgPDUConstants" "";
BA_DEF_DEF_  "GenMsgSendType" "NoMsgSendType";
BA_DEF_DEF_  "GenMsgStartDelayTime" 0;
BA_DEF_DEF_  "NmMessage" "No";
BA_DEF_DEF_  "NmhMessage" "No";
BA_DEF_DEF_  "MsgType" "Application";
BA_DEF_DEF_  "VAGTP20_API" 0;
BA_DEF_DEF_  "VAGTP20_DynConnection" "No";
BA_DEF_DEF_  "VAGTP20_DynSetup" "No";
BA_DEF_DEF_  "VAGTP20_StatConnection" "No";
BA_DEF_DEF_  "CANFD_BRS" "1";
BA_DEF_DEF_  "VFrameFormat" "StandardCAN";
BA_DEF_DEF_  "GenSigActiveRepetitions" 0;
BA_DEF_DEF_  "GenSigInactiveValue" 0;
BA_DEF_DEF_  "GenSigSendType" "NoSigSendType";
BA_DEF_DEF_  "GenSigStartValue" 0;
BA_DEF_DEF_  "NWM-WakeupAllowed" "No";
BA_DEF_DEF_  "GenSigFuncType" "NoFunction";
BA_DEF_DEF_  "GenSigSwitchedByIgnition" "Yes";
BA_DEF_DEF_  "Fehlerwert" 0;
BA_DEF_DEF_  "GenSigMissingSourceValue" 0;
BA_ "GenMsgCycleTime" BO_ 2527679921 200;
BA_ "GenMsgDelayTime" BO_ 2527679921 10;
BA_ "GenMsgILSupport" BO_ 2527679921 1;
BA_ "GenMsgSendType" BO_ 2527679921 0;
BA_ "VFrameFormat" BO_ 2527679921 15;
BA_ "GenMsgCycleTime" BO_ 918 100;
BA_ "GenMsgILSupport" BO_ 918 1;
BA_ "GenMsgSendType" BO_ 918 0;
BA_ "VFrameFormat" BO_ 918 14;
BA_ "GenMsgCycleTime" BO_ 686 50;
BA_ "GenMsgILSupport" BO_ 686 1;
BA_ "GenMsgPDUConstants" BO_ 686 "0x83,0x50,0xbf,0x5d,0x67,0x68,0x2f,0x4b,0x32,0x4e,0x1a,0xba,0xc4,0x39,0xf5,0xdb";
BA_ "GenMsgSendType" BO_ 686 0;
BA_ "VFrameFormat" BO_ 686 14;
BA_ "GenMsgCycleTime" BO_ 1012 50;
BA_ "GenMsgILSupport" BO_ 1012 1;
BA_ "GenMsgPDUConstants" BO_ 1012 "0x26,0xe4,0xc5,0x16,0xcf,0x20,0x65,0xad,0xed,0x6a,0xa3,0x49,0x02,0x6b,0xb2,0xbd";
BA_ "GenMsgSendType" BO_ 1012 0;
BA_ "VFrameFormat" BO_ 1012 14;
BA_ "GenMsgCycleTime" BO_ 247 50;
BA_ "GenMsgILSupport" BO_ 247 1;
BA_ "GenMsgPDUConstants" BO_ 247 "0x5f,0xa0,0x44,0xd0,0x63,0x59,0x5b,0xa2,0x68,0x04,0x90,0x87,0x52,0x12,0xb4,0x9e";
BA_ "GenMsgSendType" BO_ 247 0;
BA_ "VFrameFormat" BO_ 247 14;
BA_ "MsgType" BO_ 2583738904 4;
BA_ "VFrameFormat" BO_ 2583738904 15;
BA_ "MsgType" BO_ 2583869976 4;
BA_ "VFrameFormat" BO_ 2583869976 15;
BA_ "MsgType" BO_ 2617084421 6;
BA_ "VFrameFormat" BO_ 2617084421 15;
BA_ "MsgType" BO_ 2617084427 6;
BA_ "VFrameFormat" BO_ 2617084427 15;
BA_ "MsgType" BO_ 2617084416 6;
BA_ "VFrameFormat" BO_ 2617084416 15;
BA_ "MsgType" BO_ 2617084417 6;
BA_ "VFrameFormat" BO_ 2617084417 15;
BA_ "MsgType" BO_ 2617084418 6;
BA_ "VFrameFormat" BO_ 2617084418 15;
BA_ "MsgType" BO_ 2617084419 6;
BA_ "VFrameFormat" BO_ 2617084419 15;
BA_ "MsgType" BO_ 2617084420 6;
BA_ "VFrameFormat" BO_ 2617084420 15;
BA_ "MsgType" BO_ 2617084422 6;
BA_ "VFrameFormat" BO_ 2617084422 15;
BA_ "MsgType" BO_ 2617084423 6;
BA_ "VFrameFormat" BO_ 2617084423 15;
BA_ "MsgType" BO_ 2617084424 6;
BA_ "VFrameFormat" BO_ 2617084424 15;
BA_ "MsgType" BO_ 2617084425 6;
BA_ "VFrameFormat" BO_ 2617084425 15;
BA_ "MsgType" BO_ 2617084426 6;
BA_ "VFrameFormat" BO_ 2617084426 15;
BA_ "MsgType" BO_ 2617084428 6;
BA_ "VFrameFormat" BO_ 2617084428 15;
BA_ "MsgType" BO_ 2617039369 6;
BA_ "VFrameFormat" BO_ 2617039369 15;
BA_ "MsgType" BO_ 2617039370 6;
BA_ "VFrameFormat" BO_ 2617039370 15;
BA_ "MsgType" BO_ 2617039371 6;
BA_ "VFrameFormat" BO_ 2617039371 15;
BA_ "MsgType" BO_ 2617039372 6;
BA_ "VFrameFormat" BO_ 2617039372 15;
BA_ "MsgType" BO_ 2617039375 6;
BA_ "VFrameFormat" BO_ 2617039375 15;
BA_ "MsgType" BO_ 2617039361 6;
BA_ "VFrameFormat" BO_ 2617039361 15;
BA_ "MsgType" BO_ 2617039362 6;
BA_ "VFrameFormat" BO_ 2617039362 15;
BA_ "MsgType" BO_ 2617039363 6;
BA_ "VFrameFormat" BO_ 2617039363 15;
BA_ "MsgType" BO_ 2617039364 6;
BA_ "VFrameFormat" BO_ 2617039364 15;
BA_ "MsgType" BO_ 2617039365 6;
BA_ "VFrameFormat" BO_ 2617039365 15;
BA_ "MsgType" BO_ 2617039366 6;
BA_ "VFrameFormat" BO_ 2617039366 15;
BA_ "MsgType" BO_ 2617039367 6;
BA_ "VFrameFormat" BO_ 2617039367 15;
BA_ "MsgType" BO_ 2617039368 6;
BA_ "VFrameFormat" BO_ 2617039368 15;
BA_ "MsgType" BO_ 2617039373 6;
BA_ "VFrameFormat" BO_ 2617039373 15;
BA_ "MsgType" BO_ 2617039374 6;
BA_ "VFrameFormat" BO_ 2617039374 15;
BA_ "MsgType" BO_ 2617039376 6;
BA_ "VFrameFormat" BO_ 2617039376 15;
BA_ "DiagRequest" BO_ 2549880335 1;
BA_ "MsgType" BO_ 2549880335 4;
BA_ "VFrameFormat" BO_ 2549880335 15;
BA_ "DiagResponse" BO_ 2550011407 1;
BA_ "MsgType" BO_ 2550011407 4;
BA_ "VFrameFormat" BO_ 2550011407 15;
BA_ "GenMsgCycleTime" BO_ 1714 1000;
BA_ "GenMsgILSupport" BO_ 1714 1;
BA_ "GenMsgSendType" BO_ 1714 0;
BA_ "VFrameFormat" BO_ 1714 14;
BA_ "GenMsgCycleTime" BO_ 1520 200;
BA_ "GenMsgDelayTime" BO_ 1520 50;
BA_ "GenMsgILSupport" BO_ 1520 1;
BA_ "GenMsgSendType" BO_ 1520 0;
BA_ "VFrameFormat" BO_ 1520 14;
BA_ "GenMsgCycleTime" BO_ 496 500;
BA_ "GenMsgDelayTime" BO_ 496 20;
BA_ "GenMsgILSupport" BO_ 496 1;
BA_ "GenMsgPDUConstants" BO_ 496 "0x2f,0x3c,0x22,0x60,0x18,0xeb,0x63,0x76,0xc5,0x91,0x0f,0x27,0x34,0x04,0x7f,0x02";
BA_ "GenMsgSendType" BO_ 496 0;
BA_ "VFrameFormat" BO_ 496 14;
BA_ "MsgType" BO_ 2583717656 4;
BA_ "VFrameFormat" BO_ 2583717656 15;
BA_ "MsgType" BO_ 2583848728 4;
BA_ "VFrameFormat" BO_ 2583848728 15;
BA_ "GenMsgCycleTime" BO_ 1603 1000;
BA_ "GenMsgDelayTime" BO_ 1603 100;
BA_ "GenMsgILSupport" BO_ 1603 1;
BA_ "GenMsgSendType" BO_ 1603 0;
BA_ "VFrameFormat" BO_ 1603 14;
BA_ "GenMsgCycleTime" BO_ 1622 1000;
BA_ "GenMsgCycleTimeFast" BO_ 1622 50;
BA_ "GenMsgDelayTime" BO_ 1622 50;
BA_ "GenMsgILSupport" BO_ 1622 1;
BA_ "GenMsgNrOfRepetition" BO_ 1622 5;
BA_ "GenMsgPDUConstants" BO_ 1622 "0xab,0x2f,0xd3,0x39,0x6f,0x37,0xfa,0x59,0xa4,0x70,0xce,0x11,0x54,0x82,0x62,0x56";
BA_ "GenMsgSendType" BO_ 1622 0;
BA_ "VFrameFormat" BO_ 1622 14;
BA_ "VFrameFormat" BO_ 26 14;
BA_ "GenMsgCycleTime" BO_ 184 500;
BA_ "GenMsgDelayTime" BO_ 184 20;
BA_ "GenMsgILSupport" BO_ 184 1;
BA_ "GenMsgSendType" BO_ 184 0;
BA_ "VFrameFormat" BO_ 184 14;
BA_ "GenMsgCycleTime" BO_ 2589283970 1000;
BA_ "GenMsgILSupport" BO_ 2589283970 1;
BA_ "GenMsgSendType" BO_ 2589283970 0;
BA_ "VFrameFormat" BO_ 2589283970 15;
BA_ "GenMsgCycleTime" BO_ 2331595989 50;
BA_ "GenMsgILSupport" BO_ 2331595989 1;
BA_ "GenMsgSendType" BO_ 2331595989 0;
BA_ "VFrameFormat" BO_ 2331595989 15;
BA_ "GenMsgCycleTime" BO_ 2589283751 500;
BA_ "GenMsgILSupport" BO_ 2589283751 1;
BA_ "GenMsgSendType" BO_ 2589283751 0;
BA_ "VFrameFormat" BO_ 2589283751 15;
BA_ "GenMsgCycleTime" BO_ 503 200;
BA_ "GenMsgDelayTime" BO_ 503 20;
BA_ "GenMsgILSupport" BO_ 503 1;
BA_ "GenMsgPDUConstants" BO_ 503 "0xe7,0x1f,0xa2,0xc2,0x76,0x25,0x1a,0x30,0xb7,0xc8,0xe8,0xe9,0x15,0x28,0x08,0x75";
BA_ "GenMsgSendType" BO_ 503 0;
BA_ "VFrameFormat" BO_ 503 14;
BA_ "GenMsgCycleTime" BO_ 258 20;
BA_ "GenMsgILSupport" BO_ 258 1;
BA_ "GenMsgPDUConstants" BO_ 258 "0xd7,0x12,0x85,0x7e,0x0b,0x34,0xfa,0x16,0x7a,0x25,0x2d,0x8f,0x04,0x8e,0x5d,0x35";
BA_ "GenMsgSendType" BO_ 258 0;
BA_ "VFrameFormat" BO_ 258 14;
BA_ "GenMsgCycleTime" BO_ 885 50;
BA_ "GenMsgILSupport" BO_ 885 1;
BA_ "GenMsgSendType" BO_ 885 0;
BA_ "VFrameFormat" BO_ 885 14;
BA_ "GenMsgCycleTime" BO_ 2589283575 500;
BA_ "GenMsgILSupport" BO_ 2589283575 1;
BA_ "GenMsgSendType" BO_ 2589283575 0;
BA_ "VFrameFormat" BO_ 2589283575 15;
BA_ "GenMsgChkConstant" BO_ 278 172;
BA_ "GenMsgCycleTime" BO_ 278 100;
BA_ "GenMsgILSupport" BO_ 278 1;
BA_ "GenMsgPDUConstants" BO_ 278 "0xac,0xac,0xac,0xac,0xac,0xac,0xac,0xac,0xac,0xac,0xac,0xac,0xac,0xac,0xac,0xac";
BA_ "GenMsgSendType" BO_ 278 0;
BA_ "VFrameFormat" BO_ 278 14;
BA_ "GenMsgCycleTime" BO_ 178 20;
BA_ "GenMsgILSupport" BO_ 178 1;
BA_ "GenMsgSendType" BO_ 178 0;
BA_ "VFrameFormat" BO_ 178 14;
BA_ "GenMsgCycleTime" BO_ 1629 1000;
BA_ "GenMsgDelayTime" BO_ 1629 200;
BA_ "GenMsgILSupport" BO_ 1629 1;
BA_ "GenMsgPDUConstants" BO_ 1629 "0xac,0xb3,0xab,0xeb,0x7a,0xe1,0x3b,0xf7,0x73,0xba,0x7c,0x9e,0x06,0x5f,0x02,0xd9";
BA_ "GenMsgSendType" BO_ 1629 0;
BA_ "VFrameFormat" BO_ 1629 14;
BA_ "GenMsgCycleTime" BO_ 253 20;
BA_ "GenMsgILSupport" BO_ 253 1;
BA_ "GenMsgPDUConstants" BO_ 253 "0xb4,0xef,0xf8,0x49,0x1e,0xe5,0xc2,0xc0,0x97,0x19,0x3c,0xc9,0xf1,0x98,0xd6,0x61";
BA_ "GenMsgSendType" BO_ 253 0;
BA_ "VFrameFormat" BO_ 253 14;
BA_ "GenMsgCycleTime" BO_ 795 50;
BA_ "GenMsgILSupport" BO_ 795 1;
BA_ "GenMsgPDUConstants" BO_ 795 "0x67,0x8a,0xae,0x22,0x4d,0xd0,0x51,0x80,0x5c,0xb9,0xce,0x1e,0xdf,0x02,0x2d,0xd4";
BA_ "GenMsgSendType" BO_ 795 0;
BA_ "VFrameFormat" BO_ 795 14;
BA_ "GenMsgCycleTime" BO_ 2589283617 1000;
BA_ "GenMsgDelayTime" BO_ 2589283617 50;
BA_ "GenMsgILSupport" BO_ 2589283617 1;
BA_ "GenMsgPDUConstants" BO_ 2589283617 "0xad,0xbd,0x5e,0x44,0x5b,0x90,0xb4,0x8d,0x9a,0x74,0xba,0xfa,0x2b,0x91,0xe2,0x89";
BA_ "GenMsgSendType" BO_ 2589283617 0;
BA_ "VFrameFormat" BO_ 2589283617 15;
BA_ "GenMsgCycleTime" BO_ 707 100;
BA_ "GenMsgILSupport" BO_ 707 1;
BA_ "GenMsgSendType" BO_ 707 0;
BA_ "VFrameFormat" BO_ 707 14;
BA_ "GenMsgCycleTime" BO_ 2589283684 1000;
BA_ "GenMsgCycleTimeFast" BO_ 2589283684 100;
BA_ "GenMsgDelayTime" BO_ 2589283684 100;
BA_ "GenMsgILSupport" BO_ 2589283684 1;
BA_ "GenMsgNrOfRepetition" BO_ 2589283684 3;
BA_ "GenMsgSendType" BO_ 2589283684 0;
BA_ "VFrameFormat" BO_ 2589283684 15;
BA_ "MsgType" BO_ 2549875476 4;
BA_ "VFrameFormat" BO_ 2549875476 15;
BA_ "MsgType" BO_ 2550006548 4;
BA_ "VFrameFormat" BO_ 2550006548 15;
BA_ "MsgType" BO_ 2549875500 4;
BA_ "VFrameFormat" BO_ 2549875500 15;
BA_ "MsgType" BO_ 2550006572 4;
BA_ "VFrameFormat" BO_ 2550006572 15;
BA_ "GenMsgCycleTime" BO_ 986 100;
BA_ "GenMsgDelayTime" BO_ 986 10;
BA_ "GenMsgILSupport" BO_ 986 1;
BA_ "GenMsgSendType" BO_ 986 0;
BA_ "VFrameFormat" BO_ 986 14;
BA_ "GenSigSendType" SG_ 2527679921 CPD_CallCenter 3;
BA_ "GenSigSwitchedByIgnition" SG_ 2527679921 CPD_CallCenter 0;
BA_ "GenSigSendType" SG_ 2527679921 CPD_Deaktivierung_Permanent 3;
BA_ "GenSigSwitchedByIgnition" SG_ 2527679921 CPD_Deaktivierung_Permanent 0;
BA_ "GenSigSendType" SG_ 2527679921 CPD_Deaktivierung_Temp 3;
BA_ "GenSigSwitchedByIgnition" SG_ 2527679921 CPD_Deaktivierung_Temp 0;
BA_ "GenSigSendType" SG_ 2527679921 CPD_Mobiltelefon_BLE 3;
BA_ "GenSigSwitchedByIgnition" SG_ 2527679921 CPD_Mobiltelefon_BLE 0;
BA_ "GenSigSendType" SG_ 2527679921 CPD_Mobiltelefon_GSM 3;
BA_ "GenSigSwitchedByIgnition" SG_ 2527679921 CPD_Mobiltelefon_GSM 0;
BA_ "GenSigSendType" SG_ 2527679921 CPDFct_Deakt 3;
BA_ "GenSigSwitchedByIgnition" SG_ 2527679921 CPDFct_Deakt 0;
BA_ "GenSigSendType" SG_ 2527679921 CPDFct_Symbol 0;
BA_ "GenSigSwitchedByIgnition" SG_ 2527679921 CPDFct_Symbol 0;
BA_ "GenSigSendType" SG_ 2527679921 CPDFct_Warnung 0;
BA_ "GenSigSwitchedByIgnition" SG_ 2527679921 CPDFct_Warnung 0;
BA_ "GenSigSendType" SG_ 918 DR_Gelbe_Warnlampe 0;
BA_ "GenSigSendType" SG_ 686 DC_IstSpannung_HV 0;
BA_ "GenSigStartValue" SG_ 686 DC_IstSpannung_HV 4094;
BA_ "GenSigSwitchedByIgnition" SG_ 686 DC_IstSpannung_HV 0;
BA_ "Fehlerwert" SG_ 686 DC_IstSpannung_HV 4095;
BA_ "GenSigSendType" SG_ 686 DC_IstSpannung_NV 0;
BA_ "GenSigStartValue" SG_ 686 DC_IstSpannung_NV 254;
BA_ "GenSigSwitchedByIgnition" SG_ 686 DC_IstSpannung_NV 0;
BA_ "Fehlerwert" SG_ 686 DC_IstSpannung_NV 255;
BA_ "GenSigSendType" SG_ 686 DC_IstStrom_NV 0;
BA_ "GenSigStartValue" SG_ 686 DC_IstStrom_NV 1022;
BA_ "GenSigSwitchedByIgnition" SG_ 686 DC_IstStrom_NV 0;
BA_ "Fehlerwert" SG_ 686 DC_IstStrom_NV 1023;
BA_ "GenSigSendType" SG_ 686 DCDC_01_BZ 0;
BA_ "GenSigFuncType" SG_ 686 DCDC_01_BZ 1;
BA_ "GenSigSwitchedByIgnition" SG_ 686 DCDC_01_BZ 0;
BA_ "GenSigSendType" SG_ 686 DCDC_01_CRC 0;
BA_ "GenSigFuncType" SG_ 686 DCDC_01_CRC 2;
BA_ "GenSigSwitchedByIgnition" SG_ 686 DCDC_01_CRC 0;
BA_ "GenSigSendType" SG_ 1012 DC_HYB_Auslastungsgrad 0;
BA_ "GenSigStartValue" SG_ 1012 DC_HYB_Auslastungsgrad 254;
BA_ "GenSigSwitchedByIgnition" SG_ 1012 DC_HYB_Auslastungsgrad 0;
BA_ "Fehlerwert" SG_ 1012 DC_HYB_Auslastungsgrad 255;
BA_ "GenSigSendType" SG_ 1012 DC_ReserveStrom_NV 0;
BA_ "GenSigStartValue" SG_ 1012 DC_ReserveStrom_NV 1022;
BA_ "GenSigSwitchedByIgnition" SG_ 1012 DC_ReserveStrom_NV 0;
BA_ "Fehlerwert" SG_ 1012 DC_ReserveStrom_NV 1023;
BA_ "GenSigSendType" SG_ 1012 DC_Verbrauch 0;
BA_ "GenSigSwitchedByIgnition" SG_ 1012 DC_Verbrauch 0;
BA_ "GenSigSendType" SG_ 1012 DC_Verbrauch_Ueberlauf 0;
BA_ "GenSigSwitchedByIgnition" SG_ 1012 DC_Verbrauch_Ueberlauf 0;
BA_ "GenSigSendType" SG_ 1012 DC_Verlustleistung 0;
BA_ "GenSigStartValue" SG_ 1012 DC_Verlustleistung 62;
BA_ "GenSigSwitchedByIgnition" SG_ 1012 DC_Verlustleistung 0;
BA_ "Fehlerwert" SG_ 1012 DC_Verlustleistung 63;
BA_ "GenSigSendType" SG_ 1012 DCDC_02_BZ 0;
BA_ "GenSigFuncType" SG_ 1012 DCDC_02_BZ 1;
BA_ "GenSigSwitchedByIgnition" SG_ 1012 DCDC_02_BZ 0;
BA_ "GenSigSendType" SG_ 1012 DCDC_02_CRC 0;
BA_ "GenSigFuncType" SG_ 1012 DCDC_02_CRC 2;
BA_ "GenSigSwitchedByIgnition" SG_ 1012 DCDC_02_CRC 0;
BA_ "GenSigSendType" SG_ 247 DC_Fehler_extern 0;
BA_ "GenSigSwitchedByIgnition" SG_ 247 DC_Fehler_extern 0;
BA_ "Fehlerwert" SG_ 247 DC_Fehler_extern 1;
BA_ "GenSigSendType" SG_ 247 DC_Fehler_intern 0;
BA_ "GenSigSwitchedByIgnition" SG_ 247 DC_Fehler_intern 0;
BA_ "GenSigSendType" SG_ 247 DC_IstLeistung_HV 0;
BA_ "GenSigStartValue" SG_ 247 DC_IstLeistung_HV 1022;
BA_ "GenSigSwitchedByIgnition" SG_ 247 DC_IstLeistung_HV 0;
BA_ "Fehlerwert" SG_ 247 DC_IstLeistung_HV 1023;
BA_ "GenSigSendType" SG_ 247 DC_IstModus_02 0;
BA_ "GenSigStartValue" SG_ 247 DC_IstModus_02 7;
BA_ "GenSigSwitchedByIgnition" SG_ 247 DC_IstModus_02 0;
BA_ "Fehlerwert" SG_ 247 DC_IstModus_02 5;
BA_ "GenSigSendType" SG_ 247 DC_IstStrom_HV 0;
BA_ "GenSigStartValue" SG_ 247 DC_IstStrom_HV 1022;
BA_ "GenSigSwitchedByIgnition" SG_ 247 DC_IstStrom_HV 0;
BA_ "Fehlerwert" SG_ 247 DC_IstStrom_HV 1023;
BA_ "GenSigSendType" SG_ 247 DC_Status_EoHVL 0;
BA_ "GenSigSwitchedByIgnition" SG_ 247 DC_Status_EoHVL 0;
BA_ "Fehlerwert" SG_ 247 DC_Status_EoHVL 3;
BA_ "GenSigSendType" SG_ 247 DC_Status_Spgfreiheit 0;
BA_ "GenSigSwitchedByIgnition" SG_ 247 DC_Status_Spgfreiheit 0;
BA_ "GenSigSendType" SG_ 247 DC_Vorladung_Status 0;
BA_ "GenSigSwitchedByIgnition" SG_ 247 DC_Vorladung_Status 0;
BA_ "GenSigSendType" SG_ 247 DCDC_04_BZ 0;
BA_ "GenSigFuncType" SG_ 247 DCDC_04_BZ 1;
BA_ "GenSigSwitchedByIgnition" SG_ 247 DCDC_04_BZ 0;
BA_ "GenSigSendType" SG_ 247 DCDC_04_CRC 0;
BA_ "GenSigFuncType" SG_ 247 DCDC_04_CRC 2;
BA_ "GenSigSwitchedByIgnition" SG_ 247 DCDC_04_CRC 0;
BA_ "GenSigSendType" SG_ 2583738904 DDA_AuthTime_Req_Data 3;
BA_ "GenSigFuncType" SG_ 2583738904 DDA_AuthTime_Req_Data 9;
BA_ "GenSigSwitchedByIgnition" SG_ 2583738904 DDA_AuthTime_Req_Data 0;
BA_ "GenSigSendType" SG_ 2583869976 DDA_AuthTime_Resp_Data 3;
BA_ "GenSigFuncType" SG_ 2583869976 DDA_AuthTime_Resp_Data 9;
BA_ "GenSigSwitchedByIgnition" SG_ 2583869976 DDA_AuthTime_Resp_Data 0;
BA_ "GenSigSwitchedByIgnition" SG_ 2617084421 DEV_ELV_Req_00_Data 0;
BA_ "GenSigSwitchedByIgnition" SG_ 2617084427 DEV_ELV_Req_01_Data 0;
BA_ "GenSigSwitchedByIgnition" SG_ 2617084416 DEV_ELV_Resp_00_Data 0;
BA_ "GenSigSwitchedByIgnition" SG_ 2617084417 DEV_ELV_Resp_01_Data 0;
BA_ "GenSigSwitchedByIgnition" SG_ 2617084418 DEV_ELV_Resp_02_Data 0;
BA_ "GenSigSwitchedByIgnition" SG_ 2617084419 DEV_ELV_Resp_03_Data 0;
BA_ "GenSigSwitchedByIgnition" SG_ 2617084420 DEV_ELV_Resp_04_Data 0;
BA_ "GenSigSwitchedByIgnition" SG_ 2617084422 DEV_ELV_Resp_05_Data 0;
BA_ "GenSigSwitchedByIgnition" SG_ 2617084423 DEV_ELV_Resp_06_Data 0;
BA_ "GenSigSwitchedByIgnition" SG_ 2617084424 DEV_ELV_Resp_07_Data 0;
BA_ "GenSigSwitchedByIgnition" SG_ 2617084425 DEV_ELV_Resp_08_Data 0;
BA_ "GenSigSwitchedByIgnition" SG_ 2617084426 DEV_ELV_Resp_09_Data 0;
BA_ "GenSigSwitchedByIgnition" SG_ 2617084428 DEV_ELV_Resp_10_Data 0;
BA_ "GenSigSwitchedByIgnition" SG_ 2617039369 DEV_HUD_Rx_09_Data 0;
BA_ "GenSigSwitchedByIgnition" SG_ 2617039370 DEV_HUD_Rx_10_Data 0;
BA_ "GenSigSwitchedByIgnition" SG_ 2617039371 DEV_HUD_Rx_11_Data 0;
BA_ "GenSigSwitchedByIgnition" SG_ 2617039372 DEV_HUD_Rx_12_Data 0;
BA_ "GenSigSwitchedByIgnition" SG_ 2617039375 DEV_HUD_Rx_15_Data 0;
BA_ "GenSigSwitchedByIgnition" SG_ 2617039361 DEV_HUD_Tx_01_Data 0;
BA_ "GenSigSwitchedByIgnition" SG_ 2617039362 DEV_HUD_Tx_02_Data 0;
BA_ "GenSigSwitchedByIgnition" SG_ 2617039363 DEV_HUD_Tx_03_Data 0;
BA_ "GenSigSwitchedByIgnition" SG_ 2617039364 DEV_HUD_Tx_04_Data 0;
BA_ "GenSigSwitchedByIgnition" SG_ 2617039365 DEV_HUD_Tx_05_Data 0;
BA_ "GenSigSwitchedByIgnition" SG_ 2617039366 DEV_HUD_Tx_06_Data 0;
BA_ "GenSigSwitchedByIgnition" SG_ 2617039367 DEV_HUD_Tx_07_Data 0;
BA_ "GenSigSwitchedByIgnition" SG_ 2617039368 DEV_HUD_Tx_08_Data 0;
BA_ "GenSigSwitchedByIgnition" SG_ 2617039373 DEV_HUD_Tx_13_Data 0;
BA_ "GenSigSwitchedByIgnition" SG_ 2617039374 DEV_HUD_Tx_14_Data 0;
BA_ "GenSigSwitchedByIgnition" SG_ 2617039376 DEV_HUD_Tx_16_Data 0;
BA_ "GenSigSendType" SG_ 2549880335 DIA_ABT_2_Req_Data 3;
BA_ "GenSigFuncType" SG_ 2549880335 DIA_ABT_2_Req_Data 9;
BA_ "GenSigSwitchedByIgnition" SG_ 2549880335 DIA_ABT_2_Req_Data 0;
BA_ "GenSigSendType" SG_ 2550011407 DIA_ABT_2_Resp_Data 3;
BA_ "GenSigFuncType" SG_ 2550011407 DIA_ABT_2_Resp_Data 9;
BA_ "GenSigSwitchedByIgnition" SG_ 2550011407 DIA_ABT_2_Resp_Data 0;
BA_ "GenSigSendType" SG_ 1714 DGN_Verlernzaehler 0;
BA_ "GenSigSwitchedByIgnition" SG_ 1714 DGN_Verlernzaehler 0;
BA_ "GenSigSendType" SG_ 1714 KBI_Kilometerstand 0;
BA_ "GenSigStartValue" SG_ 1714 KBI_Kilometerstand 1048574;
BA_ "GenSigSwitchedByIgnition" SG_ 1714 KBI_Kilometerstand 0;
BA_ "Fehlerwert" SG_ 1714 KBI_Kilometerstand 1048575;
BA_ "GenSigSendType" SG_ 1714 Kombi_02_alt 0;
BA_ "GenSigStartValue" SG_ 1714 Kombi_02_alt 1;
BA_ "GenSigFuncType" SG_ 1714 Kombi_02_alt 5;
BA_ "GenSigSwitchedByIgnition" SG_ 1714 Kombi_02_alt 0;
BA_ "GenSigSendType" SG_ 1714 UH_Jahr 0;
BA_ "GenSigSwitchedByIgnition" SG_ 1714 UH_Jahr 0;
BA_ "GenSigSendType" SG_ 1714 UH_Minute 0;
BA_ "GenSigSwitchedByIgnition" SG_ 1714 UH_Minute 0;
BA_ "GenSigSendType" SG_ 1714 UH_Monat 0;
BA_ "GenSigSwitchedByIgnition" SG_ 1714 UH_Monat 0;
BA_ "Fehlerwert" SG_ 1714 UH_Monat 15;
BA_ "GenSigSendType" SG_ 1714 UH_Sekunde 0;
BA_ "GenSigSwitchedByIgnition" SG_ 1714 UH_Sekunde 0;
BA_ "GenSigSendType" SG_ 1714 UH_Stunde 0;
BA_ "GenSigSwitchedByIgnition" SG_ 1714 UH_Stunde 0;
BA_ "GenSigSendType" SG_ 1714 UH_Tag 0;
BA_ "GenSigSwitchedByIgnition" SG_ 1714 UH_Tag 0;
BA_ "GenSigSendType" SG_ 1714 Uhrzeit_01_alt 0;
BA_ "GenSigStartValue" SG_ 1714 Uhrzeit_01_alt 1;
BA_ "GenSigFuncType" SG_ 1714 Uhrzeit_01_alt 5;
BA_ "GenSigSwitchedByIgnition" SG_ 1714 Uhrzeit_01_alt 0;
BA_ "GenSigSendType" SG_ 1714 Vehicle_Driving_Cycle 0;
BA_ "GenSigSwitchedByIgnition" SG_ 1714 Vehicle_Driving_Cycle 0;
BA_ "GenSigSendType" SG_ 1520 BCM1_Stellgroesse_Kl_58s 3;
BA_ "GenSigStartValue" SG_ 1520 BCM1_Stellgroesse_Kl_58s 126;
BA_ "GenSigSwitchedByIgnition" SG_ 1520 BCM1_Stellgroesse_Kl_58s 0;
BA_ "Fehlerwert" SG_ 1520 BCM1_Stellgroesse_Kl_58s 127;
BA_ "GenSigSendType" SG_ 1520 DI_Display_Nachtdesign 3;
BA_ "GenSigSwitchedByIgnition" SG_ 1520 DI_Display_Nachtdesign 0;
BA_ "GenSigSendType" SG_ 1520 DI_Fotosensor 3;
BA_ "GenSigSwitchedByIgnition" SG_ 1520 DI_Fotosensor 0;
BA_ "GenSigSendType" SG_ 1520 DI_KL_58xd 3;
BA_ "GenSigStartValue" SG_ 1520 DI_KL_58xd 254;
BA_ "GenSigSwitchedByIgnition" SG_ 1520 DI_KL_58xd 0;
BA_ "Fehlerwert" SG_ 1520 DI_KL_58xd 255;
BA_ "GenSigSendType" SG_ 1520 DI_KL_58xs 3;
BA_ "GenSigStartValue" SG_ 1520 DI_KL_58xs 126;
BA_ "GenSigSwitchedByIgnition" SG_ 1520 DI_KL_58xs 0;
BA_ "Fehlerwert" SG_ 1520 DI_KL_58xs 127;
BA_ "GenSigSendType" SG_ 1520 DI_KL_58xt 3;
BA_ "GenSigStartValue" SG_ 1520 DI_KL_58xt 126;
BA_ "GenSigSwitchedByIgnition" SG_ 1520 DI_KL_58xt 0;
BA_ "Fehlerwert" SG_ 1520 DI_KL_58xt 127;
BA_ "GenSigSendType" SG_ 496 ACF_Lampe_Hands_Off 3;
BA_ "GenSigSendType" SG_ 496 EA_02_BZ 0;
BA_ "GenSigFuncType" SG_ 496 EA_02_BZ 1;
BA_ "GenSigSendType" SG_ 496 EA_02_CRC 0;
BA_ "GenSigFuncType" SG_ 496 EA_02_CRC 2;
BA_ "GenSigSendType" SG_ 496 EA_Blinken 3;
BA_ "GenSigSendType" SG_ 496 EA_Bremslichtblinken 3;
BA_ "GenSigSendType" SG_ 496 EA_eCall_Anf 3;
BA_ "GenSigSendType" SG_ 496 EA_Fahrzeughupe_Anf 3;
BA_ "GenSigSendType" SG_ 496 EA_Infotainment_Anf 3;
BA_ "GenSigSendType" SG_ 496 EA_Innenraumlicht_Anf 3;
BA_ "GenSigSendType" SG_ 496 EA_Status_HMI 3;
BA_ "GenSigSendType" SG_ 496 EA_Texte 3;
BA_ "GenSigSendType" SG_ 496 EA_Tueren_Anf 3;
BA_ "GenSigSendType" SG_ 496 EA_Warnlevel 3;
BA_ "GenSigSendType" SG_ 496 STP_Primaeranz 3;
BA_ "GenSigSendType" SG_ 496 zFAS_Warnblinken 3;
BA_ "GenSigSendType" SG_ 2583717656 eCall_AuthTime_Req_Data 3;
BA_ "GenSigFuncType" SG_ 2583717656 eCall_AuthTime_Req_Data 9;
BA_ "GenSigSwitchedByIgnition" SG_ 2583717656 eCall_AuthTime_Req_Data 0;
BA_ "GenSigSendType" SG_ 2583848728 eCall_AuthTime_Resp_Data 3;
BA_ "GenSigFuncType" SG_ 2583848728 eCall_AuthTime_Resp_Data 9;
BA_ "GenSigSwitchedByIgnition" SG_ 2583848728 eCall_AuthTime_Resp_Data 0;
BA_ "GenSigSendType" SG_ 1603 KBI_Einheit_Datum 3;
BA_ "GenSigSwitchedByIgnition" SG_ 1603 KBI_Einheit_Datum 0;
BA_ "GenSigSendType" SG_ 1603 KBI_Einheit_Druck 3;
BA_ "GenSigSwitchedByIgnition" SG_ 1603 KBI_Einheit_Druck 0;
BA_ "GenSigSendType" SG_ 1603 KBI_Einheit_Masse 3;
BA_ "GenSigSwitchedByIgnition" SG_ 1603 KBI_Einheit_Masse 0;
BA_ "GenSigSendType" SG_ 1603 KBI_Einheit_Sprache 3;
BA_ "GenSigSwitchedByIgnition" SG_ 1603 KBI_Einheit_Sprache 0;
BA_ "GenSigSendType" SG_ 1603 KBI_Einheit_Streckenanz 3;
BA_ "GenSigSwitchedByIgnition" SG_ 1603 KBI_Einheit_Streckenanz 0;
BA_ "GenSigSendType" SG_ 1603 KBI_Einheit_Tacho 3;
BA_ "GenSigSwitchedByIgnition" SG_ 1603 KBI_Einheit_Tacho 0;
BA_ "GenSigSendType" SG_ 1603 KBI_Einheit_Temp 3;
BA_ "GenSigSwitchedByIgnition" SG_ 1603 KBI_Einheit_Temp 0;
BA_ "GenSigSendType" SG_ 1603 KBI_Einheit_Uhrzeit 3;
BA_ "GenSigSwitchedByIgnition" SG_ 1603 KBI_Einheit_Uhrzeit 0;
BA_ "GenSigSendType" SG_ 1603 KBI_Einheit_Verbrauch 3;
BA_ "GenSigSwitchedByIgnition" SG_ 1603 KBI_Einheit_Verbrauch 0;
BA_ "GenSigSendType" SG_ 1603 KBI_Einheit_Verbrauch_elektr 3;
BA_ "GenSigSwitchedByIgnition" SG_ 1603 KBI_Einheit_Verbrauch_elektr 0;
BA_ "GenSigSendType" SG_ 1603 KBI_Einheit_Verbrauch_Gas 3;
BA_ "GenSigSwitchedByIgnition" SG_ 1603 KBI_Einheit_Verbrauch_Gas 0;
BA_ "GenSigSendType" SG_ 1603 KBI_Einheit_Volumen 3;
BA_ "GenSigSwitchedByIgnition" SG_ 1603 KBI_Einheit_Volumen 0;
BA_ "GenSigSendType" SG_ 1603 KBI_MFA_v_Einheit_02 3;
BA_ "GenSigSwitchedByIgnition" SG_ 1603 KBI_MFA_v_Einheit_02 0;
BA_ "GenSigSendType" SG_ 1622 ELV_01_BZ 0;
BA_ "GenSigFuncType" SG_ 1622 ELV_01_BZ 1;
BA_ "GenSigSwitchedByIgnition" SG_ 1622 ELV_01_BZ 0;
BA_ "GenSigSendType" SG_ 1622 ELV_01_CRC 0;
BA_ "GenSigFuncType" SG_ 1622 ELV_01_CRC 2;
BA_ "GenSigSwitchedByIgnition" SG_ 1622 ELV_01_CRC 0;
BA_ "GenSigSendType" SG_ 1622 ELV_01_Sendestatus 5;
BA_ "GenSigSwitchedByIgnition" SG_ 1622 ELV_01_Sendestatus 0;
BA_ "GenSigSendType" SG_ 1622 ELV_Abbruch_Anf_Klemmenfreigabe 3;
BA_ "GenSigSwitchedByIgnition" SG_ 1622 ELV_Abbruch_Anf_Klemmenfreigabe 0;
BA_ "GenSigSendType" SG_ 1622 ELV_Anf_Klemme_15 3;
BA_ "GenSigSwitchedByIgnition" SG_ 1622 ELV_Anf_Klemme_15 0;
BA_ "GenSigSendType" SG_ 1622 ELV_Anf_Klemme_50 3;
BA_ "GenSigSwitchedByIgnition" SG_ 1622 ELV_Anf_Klemme_50 0;
BA_ "GenSigSendType" SG_ 1622 ELV_Anf_Klemme_S 3;
BA_ "GenSigSwitchedByIgnition" SG_ 1622 ELV_Anf_Klemme_S 0;
BA_ "GenSigSendType" SG_ 1622 ELV_Anlernmodus 3;
BA_ "GenSigSwitchedByIgnition" SG_ 1622 ELV_Anlernmodus 0;
BA_ "GenSigSendType" SG_ 1622 ELV_Entriegelt 3;
BA_ "GenSigSwitchedByIgnition" SG_ 1622 ELV_Entriegelt 0;
BA_ "GenSigSendType" SG_ 1622 ELV_Klemmenfreigabe 3;
BA_ "GenSigSwitchedByIgnition" SG_ 1622 ELV_Klemmenfreigabe 0;
BA_ "GenSigSendType" SG_ 1622 ELV_Lebenszustand 3;
BA_ "GenSigSwitchedByIgnition" SG_ 1622 ELV_Lebenszustand 0;
BA_ "GenSigSendType" SG_ 1622 ELV_LED_Gelb 3;
BA_ "GenSigSwitchedByIgnition" SG_ 1622 ELV_LED_Gelb 0;
BA_ "GenSigSendType" SG_ 1622 ELV_LED_Rot 3;
BA_ "GenSigSwitchedByIgnition" SG_ 1622 ELV_LED_Rot 0;
BA_ "GenSigSendType" SG_ 1622 ELV_P_verriegelt 3;
BA_ "GenSigSwitchedByIgnition" SG_ 1622 ELV_P_verriegelt 0;
BA_ "GenSigSendType" SG_ 1622 ELV_Txt_Bremse 3;
BA_ "GenSigSwitchedByIgnition" SG_ 1622 ELV_Txt_Bremse 0;
BA_ "GenSigSendType" SG_ 1622 ELV_Txt_Defekt 3;
BA_ "GenSigSwitchedByIgnition" SG_ 1622 ELV_Txt_Defekt 0;
BA_ "GenSigSendType" SG_ 1622 ELV_Txt_Kupplung 3;
BA_ "GenSigSwitchedByIgnition" SG_ 1622 ELV_Txt_Kupplung 0;
BA_ "GenSigSendType" SG_ 1622 ELV_Txt_Lkg_Bewegen 3;
BA_ "GenSigSwitchedByIgnition" SG_ 1622 ELV_Txt_Lkg_Bewegen 0;
BA_ "GenSigSendType" SG_ 1622 ELV_Txt_P_Gang 3;
BA_ "GenSigSwitchedByIgnition" SG_ 1622 ELV_Txt_P_Gang 0;
BA_ "GenSigSendType" SG_ 1622 ELV_Txt_Panikabschaltung 3;
BA_ "GenSigSwitchedByIgnition" SG_ 1622 ELV_Txt_Panikabschaltung 0;
BA_ "GenSigSendType" SG_ 1622 ELV_Txt_PN_Gang 3;
BA_ "GenSigSwitchedByIgnition" SG_ 1622 ELV_Txt_PN_Gang 0;
BA_ "GenSigSendType" SG_ 1622 ELV_Txt_Werkstatt 3;
BA_ "GenSigSwitchedByIgnition" SG_ 1622 ELV_Txt_Werkstatt 0;
BA_ "GenSigSendType" SG_ 1622 ELV_Verriegelt 3;
BA_ "GenSigSwitchedByIgnition" SG_ 1622 ELV_Verriegelt 0;
BA_ "GenSigSendType" SG_ 1622 ELV_ZAT_betaetigt 3;
BA_ "GenSigSwitchedByIgnition" SG_ 1622 ELV_ZAT_betaetigt 0;
BA_ "GenSigSendType" SG_ 1622 KST_Anf_ZV_Verriegelung 3;
BA_ "GenSigSwitchedByIgnition" SG_ 1622 KST_Anf_ZV_Verriegelung 0;
BA_ "GenSigSendType" SG_ 1622 KST_aut_Abschaltung_Zuendung 4;
BA_ "GenSigSwitchedByIgnition" SG_ 1622 KST_aut_Abschaltung_Zuendung 0;
BA_ "GenSigSendType" SG_ 1622 KST_Txt_Komfortabschaltung 3;
BA_ "GenSigSwitchedByIgnition" SG_ 1622 KST_Txt_Komfortabschaltung 0;
BA_ "GenSigSwitchedByIgnition" SG_ 26 ELV_WFS_Anfrage_CRC 0;
BA_ "GenSigSwitchedByIgnition" SG_ 26 ELV_WFS_Anfrage_Status 0;
BA_ "GenSigSwitchedByIgnition" SG_ 26 ELV_WFS_Anfrage_Typ 0;
BA_ "GenSigSendType" SG_ 184 EM1_Abregelung_Temperatur 0;
BA_ "GenSigSwitchedByIgnition" SG_ 184 EM1_Abregelung_Temperatur 0;
BA_ "GenSigSendType" SG_ 184 EM1_AnlernenElMotor_Anf 0;
BA_ "GenSigSwitchedByIgnition" SG_ 184 EM1_AnlernenElMotor_Anf 0;
BA_ "GenSigSendType" SG_ 184 EM1_AR_aktiv 0;
BA_ "GenSigSwitchedByIgnition" SG_ 184 EM1_AR_aktiv 0;
BA_ "GenSigSendType" SG_ 184 EM1_Eta_Sys 0;
BA_ "GenSigStartValue" SG_ 184 EM1_Eta_Sys 510;
BA_ "GenSigSwitchedByIgnition" SG_ 184 EM1_Eta_Sys 0;
BA_ "Fehlerwert" SG_ 184 EM1_Eta_Sys 511;
BA_ "GenSigSendType" SG_ 184 EM1_Fehler_ElAntriebFreilauf_Anf 0;
BA_ "GenSigSwitchedByIgnition" SG_ 184 EM1_Fehler_ElAntriebFreilauf_Anf 0;
BA_ "GenSigSendType" SG_ 184 EM1_Freigabe_Info_WFS 3;
BA_ "GenSigSwitchedByIgnition" SG_ 184 EM1_Freigabe_Info_WFS 0;
BA_ "GenSigSendType" SG_ 184 EM1_Freigabe_Verfallsinfo_WFS 3;
BA_ "GenSigSwitchedByIgnition" SG_ 184 EM1_Freigabe_Verfallsinfo_WFS 0;
BA_ "GenSigSendType" SG_ 184 EM1_HV_betriebsbereit 0;
BA_ "GenSigSwitchedByIgnition" SG_ 184 EM1_HV_betriebsbereit 0;
BA_ "GenSigSendType" SG_ 184 EM1_IstStrom 0;
BA_ "GenSigStartValue" SG_ 184 EM1_IstStrom 2046;
BA_ "GenSigSwitchedByIgnition" SG_ 184 EM1_IstStrom 0;
BA_ "Fehlerwert" SG_ 184 EM1_IstStrom 2047;
BA_ "GenSigSendType" SG_ 184 EM1_Moment_HVVerbraucher 0;
BA_ "GenSigStartValue" SG_ 184 EM1_Moment_HVVerbraucher 1023;
BA_ "GenSigSwitchedByIgnition" SG_ 184 EM1_Moment_HVVerbraucher 0;
BA_ "GenSigSendType" SG_ 184 EM1_Parken_WFS_Status 3;
BA_ "GenSigSwitchedByIgnition" SG_ 184 EM1_Parken_WFS_Status 0;
BA_ "GenSigSendType" SG_ 184 EM1_Sperr_Info_WFS 3;
BA_ "GenSigSwitchedByIgnition" SG_ 184 EM1_Sperr_Info_WFS 0;
BA_ "GenSigSendType" SG_ 184 LE_Kuehlmittel_Sensor 3;
BA_ "GenSigSwitchedByIgnition" SG_ 184 LE_Kuehlmittel_Sensor 0;
BA_ "GenSigSendType" SG_ 2589283970 DIST_DKmtg_Auth 0;
BA_ "GenSigSwitchedByIgnition" SG_ 2589283970 DIST_DKmtg_Auth 0;
BA_ "GenSigSendType" SG_ 2589283970 SOK_Entfernung_02_Signatur 0;
BA_ "GenSigFuncType" SG_ 2589283970 SOK_Entfernung_02_Signatur 15;
BA_ "GenSigSwitchedByIgnition" SG_ 2589283970 SOK_Entfernung_02_Signatur 0;
BA_ "GenSigSendType" SG_ 2331595989 DIST_DKmtg 0;
BA_ "GenSigSwitchedByIgnition" SG_ 2331595989 DIST_DKmtg 0;
BA_ "GenSigSendType" SG_ 2589283751 KBI_Kilometerstand_Extended 0;
BA_ "GenSigStartValue" SG_ 2589283751 KBI_Kilometerstand_Extended 16777214;
BA_ "GenSigSwitchedByIgnition" SG_ 2589283751 KBI_Kilometerstand_Extended 0;
BA_ "Fehlerwert" SG_ 2589283751 KBI_Kilometerstand_Extended 16777215;
BA_ "GenSigSendType" SG_ 2589283751 KBI_Kilometerstand_HiRes_meter 0;
BA_ "GenSigSwitchedByIgnition" SG_ 2589283751 KBI_Kilometerstand_HiRes_meter 0;
BA_ "GenSigSendType" SG_ 503 EPB_03_BZ 0;
BA_ "GenSigFuncType" SG_ 503 EPB_03_BZ 1;
BA_ "GenSigSwitchedByIgnition" SG_ 503 EPB_03_BZ 0;
BA_ "GenSigSendType" SG_ 503 EPB_03_CRC 0;
BA_ "GenSigFuncType" SG_ 503 EPB_03_CRC 2;
BA_ "GenSigSwitchedByIgnition" SG_ 503 EPB_03_CRC 0;
BA_ "GenSigSendType" SG_ 503 EPB_Autohold_Standbyanzeige 3;
BA_ "GenSigSwitchedByIgnition" SG_ 503 EPB_Autohold_Standbyanzeige 0;
BA_ "GenSigSendType" SG_ 503 EPB_Autoholdlampe_02 3;
BA_ "GenSigSwitchedByIgnition" SG_ 503 EPB_Autoholdlampe_02 0;
BA_ "GenSigSendType" SG_ 503 EPB_Fehlermeldungen_02 3;
BA_ "GenSigSwitchedByIgnition" SG_ 503 EPB_Fehlermeldungen_02 0;
BA_ "GenSigSendType" SG_ 503 EPB_Funktionslampe_02 3;
BA_ "GenSigSwitchedByIgnition" SG_ 503 EPB_Funktionslampe_02 0;
BA_ "GenSigSendType" SG_ 503 EPB_Parkanzeige 3;
BA_ "GenSigSwitchedByIgnition" SG_ 503 EPB_Parkanzeige 0;
BA_ "GenSigSendType" SG_ 503 EPB_Texte_02 3;
BA_ "GenSigSwitchedByIgnition" SG_ 503 EPB_Texte_02 0;
BA_ "GenSigSendType" SG_ 258 ASR_Systemstatus 0;
BA_ "GenSigStartValue" SG_ 258 ASR_Systemstatus 2;
BA_ "GenSigSwitchedByIgnition" SG_ 258 ASR_Systemstatus 0;
BA_ "GenSigSendType" SG_ 258 ECD_Bremslicht 0;
BA_ "GenSigSwitchedByIgnition" SG_ 258 ECD_Bremslicht 0;
BA_ "GenSigSendType" SG_ 258 ECD_Fehler 0;
BA_ "GenSigSwitchedByIgnition" SG_ 258 ECD_Fehler 0;
BA_ "GenSigSendType" SG_ 258 ECD_nicht_verfuegbar 0;
BA_ "GenSigStartValue" SG_ 258 ECD_nicht_verfuegbar 1;
BA_ "GenSigSwitchedByIgnition" SG_ 258 ECD_nicht_verfuegbar 0;
BA_ "GenSigSendType" SG_ 258 EPB_DAA_Randbed_erf 0;
BA_ "GenSigSwitchedByIgnition" SG_ 258 EPB_DAA_Randbed_erf 0;
BA_ "GenSigSendType" SG_ 258 EPB_Fehlerstatus_02 0;
BA_ "GenSigSwitchedByIgnition" SG_ 258 EPB_Fehlerstatus_02 0;
BA_ "GenSigSendType" SG_ 258 EPB_Freig_Verzoeg_Anf 0;
BA_ "GenSigSwitchedByIgnition" SG_ 258 EPB_Freig_Verzoeg_Anf 0;
BA_ "GenSigSendType" SG_ 258 EPB_Pedalweg_Kuppl 0;
BA_ "GenSigSwitchedByIgnition" SG_ 258 EPB_Pedalweg_Kuppl 0;
BA_ "Fehlerwert" SG_ 258 EPB_Pedalweg_Kuppl 255;
BA_ "GenSigSendType" SG_ 258 EPB_QBit_Pedalweg_Kuppl 0;
BA_ "GenSigStartValue" SG_ 258 EPB_QBit_Pedalweg_Kuppl 1;
BA_ "GenSigSwitchedByIgnition" SG_ 258 EPB_QBit_Pedalweg_Kuppl 0;
BA_ "GenSigSendType" SG_ 258 EPB_QBit_Schalterpos 0;
BA_ "GenSigStartValue" SG_ 258 EPB_QBit_Schalterpos 1;
BA_ "GenSigSwitchedByIgnition" SG_ 258 EPB_QBit_Schalterpos 0;
BA_ "GenSigSendType" SG_ 258 EPB_Schalterposition 0;
BA_ "GenSigSwitchedByIgnition" SG_ 258 EPB_Schalterposition 0;
BA_ "Fehlerwert" SG_ 258 EPB_Schalterposition 3;
BA_ "GenSigSendType" SG_ 258 EPB_Spannkraft 0;
BA_ "GenSigStartValue" SG_ 258 EPB_Spannkraft 30;
BA_ "GenSigSwitchedByIgnition" SG_ 258 EPB_Spannkraft 0;
BA_ "Fehlerwert" SG_ 258 EPB_Spannkraft 31;
BA_ "GenSigSendType" SG_ 258 EPB_Status 0;
BA_ "GenSigSwitchedByIgnition" SG_ 258 EPB_Status 0;
BA_ "GenSigSendType" SG_ 258 EPB_Status_02 0;
BA_ "GenSigStartValue" SG_ 258 EPB_Status_02 6;
BA_ "GenSigSwitchedByIgnition" SG_ 258 EPB_Status_02 0;
BA_ "GenSigSendType" SG_ 258 EPB_Verzoeg_Anf 0;
BA_ "GenSigStartValue" SG_ 258 EPB_Verzoeg_Anf 166;
BA_ "GenSigSwitchedByIgnition" SG_ 258 EPB_Verzoeg_Anf 0;
BA_ "GenSigSendType" SG_ 258 ESC_50_BZ 0;
BA_ "GenSigFuncType" SG_ 258 ESC_50_BZ 1;
BA_ "GenSigSwitchedByIgnition" SG_ 258 ESC_50_BZ 0;
BA_ "GenSigSendType" SG_ 258 ESC_50_CRC 0;
BA_ "GenSigFuncType" SG_ 258 ESC_50_CRC 2;
BA_ "GenSigSwitchedByIgnition" SG_ 258 ESC_50_CRC 0;
BA_ "GenSigSendType" SG_ 258 ESC_Bremsdruckgradient 0;
BA_ "GenSigStartValue" SG_ 258 ESC_Bremsdruckgradient 254;
BA_ "GenSigSwitchedByIgnition" SG_ 258 ESC_Bremsdruckgradient 0;
BA_ "Fehlerwert" SG_ 258 ESC_Bremsdruckgradient 255;
BA_ "GenSigSendType" SG_ 258 ESC_Fahrerbremswunsch 0;
BA_ "GenSigStartValue" SG_ 258 ESC_Fahrerbremswunsch 100;
BA_ "GenSigSwitchedByIgnition" SG_ 258 ESC_Fahrerbremswunsch 0;
BA_ "Fehlerwert" SG_ 258 ESC_Fahrerbremswunsch 1023;
BA_ "GenSigSendType" SG_ 258 ESC_Fahrerradbremswunschmoment 0;
BA_ "Fehlerwert" SG_ 258 ESC_Fahrerradbremswunschmoment 4095;
BA_ "GenSigSendType" SG_ 258 ESC_Hydr_Fkt_aktiv 0;
BA_ "GenSigSwitchedByIgnition" SG_ 258 ESC_Hydr_Fkt_aktiv 0;
BA_ "GenSigSendType" SG_ 258 ESC_Motorstartverzoegerung 0;
BA_ "GenSigSwitchedByIgnition" SG_ 258 ESC_Motorstartverzoegerung 0;
BA_ "GenSigSendType" SG_ 258 ESC_QBit_Fahrerbremswunsch 0;
BA_ "GenSigStartValue" SG_ 258 ESC_QBit_Fahrerbremswunsch 1;
BA_ "GenSigSwitchedByIgnition" SG_ 258 ESC_QBit_Fahrerbremswunsch 0;
BA_ "GenSigSendType" SG_ 258 ESC_Raddruck_max 0;
BA_ "GenSigStartValue" SG_ 258 ESC_Raddruck_max 254;
BA_ "GenSigSwitchedByIgnition" SG_ 258 ESC_Raddruck_max 0;
BA_ "Fehlerwert" SG_ 258 ESC_Raddruck_max 255;
BA_ "GenSigSendType" SG_ 258 ESC_SeitenwindAssistent_Eingriff 0;
BA_ "GenSigSwitchedByIgnition" SG_ 258 ESC_SeitenwindAssistent_Eingriff 0;
BA_ "GenSigSendType" SG_ 258 ESC_Unterdruckmangel_erkannt 0;
BA_ "GenSigSwitchedByIgnition" SG_ 258 ESC_Unterdruckmangel_erkannt 0;
BA_ "GenSigSendType" SG_ 258 ESCGeneratorSollMoment 0;
BA_ "GenSigStartValue" SG_ 258 ESCGeneratorSollMoment 4094;
BA_ "GenSigSwitchedByIgnition" SG_ 258 ESCGeneratorSollMoment 0;
BA_ "Fehlerwert" SG_ 258 ESCGeneratorSollMoment 4095;
BA_ "GenSigSendType" SG_ 258 ESP_Abrutschen_Stillstand 0;
BA_ "GenSigSwitchedByIgnition" SG_ 258 ESP_Abrutschen_Stillstand 0;
BA_ "GenSigSendType" SG_ 258 ESP_ANB_CM_Rueckk_Umsetz 0;
BA_ "GenSigSwitchedByIgnition" SG_ 258 ESP_ANB_CM_Rueckk_Umsetz 0;
BA_ "GenSigSendType" SG_ 258 ESP_Anforderung_EPB 0;
BA_ "GenSigSwitchedByIgnition" SG_ 258 ESP_Anforderung_EPB 0;
BA_ "GenSigSendType" SG_ 258 ESP_Anschleppstart_Freigabe 0;
BA_ "GenSigSwitchedByIgnition" SG_ 258 ESP_Anschleppstart_Freigabe 0;
BA_ "GenSigSendType" SG_ 258 ESP_Autohold_aktiv 0;
BA_ "GenSigSwitchedByIgnition" SG_ 258 ESP_Autohold_aktiv 0;
BA_ "GenSigSendType" SG_ 258 ESP_Autohold_Standby 0;
BA_ "GenSigSwitchedByIgnition" SG_ 258 ESP_Autohold_Standby 0;
BA_ "GenSigSendType" SG_ 258 ESP_BKV_Unterdruck 0;
BA_ "GenSigStartValue" SG_ 258 ESP_BKV_Unterdruck 254;
BA_ "GenSigSwitchedByIgnition" SG_ 258 ESP_BKV_Unterdruck 0;
BA_ "Fehlerwert" SG_ 258 ESP_BKV_Unterdruck 255;
BA_ "GenSigSendType" SG_ 258 ESP_Bremsdruck 0;
BA_ "GenSigStartValue" SG_ 258 ESP_Bremsdruck 100;
BA_ "GenSigSwitchedByIgnition" SG_ 258 ESP_Bremsdruck 0;
BA_ "Fehlerwert" SG_ 258 ESP_Bremsdruck 1023;
BA_ "GenSigSendType" SG_ 258 ESP_Bremsruck_AWV2 0;
BA_ "GenSigSwitchedByIgnition" SG_ 258 ESP_Bremsruck_AWV2 0;
BA_ "GenSigSendType" SG_ 258 ESP_Eingr_HL 0;
BA_ "GenSigSwitchedByIgnition" SG_ 258 ESP_Eingr_HL 0;
BA_ "GenSigSendType" SG_ 258 ESP_Eingr_HR 0;
BA_ "GenSigSwitchedByIgnition" SG_ 258 ESP_Eingr_HR 0;
BA_ "GenSigSendType" SG_ 258 ESP_Eingr_VL 0;
BA_ "GenSigSwitchedByIgnition" SG_ 258 ESP_Eingr_VL 0;
BA_ "GenSigSendType" SG_ 258 ESP_Eingr_VR 0;
BA_ "GenSigSwitchedByIgnition" SG_ 258 ESP_Eingr_VR 0;
BA_ "GenSigSendType" SG_ 258 ESP_Fahrer_bremst 0;
BA_ "GenSigSwitchedByIgnition" SG_ 258 ESP_Fahrer_bremst 0;
BA_ "GenSigSendType" SG_ 258 ESP_Fahrer_tritt_ZBR_Schw 0;
BA_ "GenSigSwitchedByIgnition" SG_ 258 ESP_Fahrer_tritt_ZBR_Schw 0;
BA_ "GenSigSendType" SG_ 258 ESP_FStatus_Anfahrhilfe 0;
BA_ "GenSigSwitchedByIgnition" SG_ 258 ESP_FStatus_Anfahrhilfe 0;
BA_ "Fehlerwert" SG_ 258 ESP_FStatus_Anfahrhilfe 1;
BA_ "GenSigSendType" SG_ 258 ESP_Gierrate 0;
BA_ "GenSigSwitchedByIgnition" SG_ 258 ESP_Gierrate 0;
BA_ "Fehlerwert" SG_ 258 ESP_Gierrate 16383;
BA_ "GenSigSendType" SG_ 258 ESP_HBA_aktiv 0;
BA_ "GenSigSwitchedByIgnition" SG_ 258 ESP_HBA_aktiv 0;
BA_ "GenSigSendType" SG_ 258 ESP_HBA_Empfindlichkeit 0;
BA_ "GenSigSwitchedByIgnition" SG_ 258 ESP_HBA_Empfindlichkeit 0;
BA_ "Fehlerwert" SG_ 258 ESP_HBA_Empfindlichkeit 7;
BA_ "GenSigSendType" SG_ 258 ESP_HDC_aktiv 0;
BA_ "GenSigSwitchedByIgnition" SG_ 258 ESP_HDC_aktiv 0;
BA_ "GenSigSendType" SG_ 258 ESP_HDC_Standby 0;
BA_ "GenSigSwitchedByIgnition" SG_ 258 ESP_HDC_Standby 0;
BA_ "GenSigSendType" SG_ 258 ESP_Konsistenz_ACC_Botschaft 0;
BA_ "GenSigSwitchedByIgnition" SG_ 258 ESP_Konsistenz_ACC_Botschaft 0;
BA_ "GenSigSendType" SG_ 258 ESP_Konsistenz_AWV2 0;
BA_ "GenSigSwitchedByIgnition" SG_ 258 ESP_Konsistenz_AWV2 0;
BA_ "GenSigSendType" SG_ 258 ESP_Konsistenz_TSK 0;
BA_ "GenSigSwitchedByIgnition" SG_ 258 ESP_Konsistenz_TSK 0;
BA_ "GenSigSendType" SG_ 258 ESP_Laengsbeschl 0;
BA_ "GenSigStartValue" SG_ 258 ESP_Laengsbeschl 512;
BA_ "GenSigSwitchedByIgnition" SG_ 258 ESP_Laengsbeschl 0;
BA_ "Fehlerwert" SG_ 258 ESP_Laengsbeschl 1023;
BA_ "GenSigSendType" SG_ 258 ESP_Lenkeingriff_ADS 0;
BA_ "GenSigSwitchedByIgnition" SG_ 258 ESP_Lenkeingriff_ADS 0;
BA_ "GenSigSendType" SG_ 258 ESP_Notbremsanzeige 0;
BA_ "GenSigSwitchedByIgnition" SG_ 258 ESP_Notbremsanzeige 0;
BA_ "GenSigSendType" SG_ 258 ESP_PLA_Abbruch 0;
BA_ "GenSigSwitchedByIgnition" SG_ 258 ESP_PLA_Abbruch 0;
BA_ "GenSigSendType" SG_ 258 ESP_Prefill_ausgeloest 0;
BA_ "GenSigSwitchedByIgnition" SG_ 258 ESP_Prefill_ausgeloest 0;
BA_ "GenSigSendType" SG_ 258 ESP_QBit_Bremsdruck 0;
BA_ "GenSigStartValue" SG_ 258 ESP_QBit_Bremsdruck 1;
BA_ "GenSigSwitchedByIgnition" SG_ 258 ESP_QBit_Bremsdruck 0;
BA_ "GenSigSendType" SG_ 258 ESP_QBit_Fahrer_bremst 0;
BA_ "GenSigStartValue" SG_ 258 ESP_QBit_Fahrer_bremst 1;
BA_ "GenSigSwitchedByIgnition" SG_ 258 ESP_QBit_Fahrer_bremst 0;
BA_ "GenSigSendType" SG_ 258 ESP_QBit_Gierrate 0;
BA_ "GenSigStartValue" SG_ 258 ESP_QBit_Gierrate 1;
BA_ "GenSigSwitchedByIgnition" SG_ 258 ESP_QBit_Gierrate 0;
BA_ "GenSigSendType" SG_ 258 ESP_QBit_Laengsbeschl 0;
BA_ "GenSigStartValue" SG_ 258 ESP_QBit_Laengsbeschl 1;
BA_ "GenSigSwitchedByIgnition" SG_ 258 ESP_QBit_Laengsbeschl 0;
BA_ "GenSigSendType" SG_ 258 ESP_QBit_Querb 0;
BA_ "GenSigStartValue" SG_ 258 ESP_QBit_Querb 1;
BA_ "GenSigSwitchedByIgnition" SG_ 258 ESP_QBit_Querb 0;
BA_ "GenSigSendType" SG_ 258 ESP_QBit_v_ref 0;
BA_ "GenSigStartValue" SG_ 258 ESP_QBit_v_ref 1;
BA_ "GenSigSwitchedByIgnition" SG_ 258 ESP_QBit_v_ref 0;
BA_ "GenSigSendType" SG_ 258 ESP_Querbeschleunigung 0;
BA_ "GenSigStartValue" SG_ 258 ESP_Querbeschleunigung 127;
BA_ "GenSigSwitchedByIgnition" SG_ 258 ESP_Querbeschleunigung 0;
BA_ "Fehlerwert" SG_ 258 ESP_Querbeschleunigung 255;
BA_ "GenSigSendType" SG_ 258 ESP_Rueckwaertsfahrt_erkannt 0;
BA_ "GenSigSwitchedByIgnition" SG_ 258 ESP_Rueckwaertsfahrt_erkannt 0;
BA_ "GenSigSendType" SG_ 258 ESP_Schwelle_Unterdruck 0;
BA_ "GenSigSwitchedByIgnition" SG_ 258 ESP_Schwelle_Unterdruck 0;
BA_ "GenSigSendType" SG_ 258 ESP_SpannungsAnf 0;
BA_ "GenSigSwitchedByIgnition" SG_ 258 ESP_SpannungsAnf 0;
BA_ "GenSigSendType" SG_ 258 ESP_StartStopp_Info 0;
BA_ "GenSigSwitchedByIgnition" SG_ 258 ESP_StartStopp_Info 0;
BA_ "GenSigSendType" SG_ 258 ESP_Status_Anfahrhilfe 0;
BA_ "GenSigSwitchedByIgnition" SG_ 258 ESP_Status_Anfahrhilfe 0;
BA_ "GenSigSendType" SG_ 258 ESP_Status_Bremsdruck 0;
BA_ "GenSigSwitchedByIgnition" SG_ 258 ESP_Status_Bremsdruck 0;
BA_ "GenSigSendType" SG_ 258 ESP_Status_Bremsentemp 0;
BA_ "GenSigSwitchedByIgnition" SG_ 258 ESP_Status_Bremsentemp 0;
BA_ "GenSigSendType" SG_ 258 ESP_Status_Bremsentemp_02 0;
BA_ "GenSigSwitchedByIgnition" SG_ 258 ESP_Status_Bremsentemp_02 0;
BA_ "GenSigSendType" SG_ 258 ESP_Status_ESP_PLA 0;
BA_ "GenSigSwitchedByIgnition" SG_ 258 ESP_Status_ESP_PLA 0;
BA_ "GenSigSendType" SG_ 258 ESP_Stillstandsphase_erschoepft 0;
BA_ "GenSigSwitchedByIgnition" SG_ 258 ESP_Stillstandsphase_erschoepft 0;
BA_ "GenSigSendType" SG_ 258 ESP_Systemstatus_03 0;
BA_ "GenSigStartValue" SG_ 258 ESP_Systemstatus_03 2;
BA_ "GenSigSwitchedByIgnition" SG_ 258 ESP_Systemstatus_03 0;
BA_ "Fehlerwert" SG_ 258 ESP_Systemstatus_03 3;
BA_ "GenSigSendType" SG_ 258 ESP_Tuerkontakt_Fahrertuer 0;
BA_ "GenSigSwitchedByIgnition" SG_ 258 ESP_Tuerkontakt_Fahrertuer 0;
BA_ "GenSigSendType" SG_ 258 ESP_v_ref 0;
BA_ "GenSigStartValue" SG_ 258 ESP_v_ref 4094;
BA_ "GenSigSwitchedByIgnition" SG_ 258 ESP_v_ref 0;
BA_ "Fehlerwert" SG_ 258 ESP_v_ref 4095;
BA_ "GenSigSendType" SG_ 258 ESP_v_ref_Fahrtrichtung 0;
BA_ "GenSigSwitchedByIgnition" SG_ 258 ESP_v_ref_Fahrtrichtung 0;
BA_ "GenSigSendType" SG_ 258 ESP_Verz_EPB_aktiv 0;
BA_ "GenSigSwitchedByIgnition" SG_ 258 ESP_Verz_EPB_aktiv 0;
BA_ "GenSigSendType" SG_ 258 ESP_Verz_TSK_aktiv 0;
BA_ "GenSigSwitchedByIgnition" SG_ 258 ESP_Verz_TSK_aktiv 0;
BA_ "GenSigSendType" SG_ 258 ESP_Verzoeg_EPB_verf 0;
BA_ "GenSigSwitchedByIgnition" SG_ 258 ESP_Verzoeg_EPB_verf 0;
BA_ "GenSigSendType" SG_ 258 ESP_VZ_Gierrate 0;
BA_ "GenSigSwitchedByIgnition" SG_ 258 ESP_VZ_Gierrate 0;
BA_ "GenSigSendType" SG_ 258 ESP_ZT_Rueckk_Umsetz 0;
BA_ "GenSigSwitchedByIgnition" SG_ 258 ESP_ZT_Rueckk_Umsetz 0;
BA_ "GenSigSendType" SG_ 258 SOK_ESC_50_Signatur 0;
BA_ "GenSigFuncType" SG_ 258 SOK_ESC_50_Signatur 15;
BA_ "GenSigSwitchedByIgnition" SG_ 258 SOK_ESC_50_Signatur 0;
BA_ "GenSigSendType" SG_ 885 ESC_54_BZ 0;
BA_ "GenSigFuncType" SG_ 885 ESC_54_BZ 1;
BA_ "GenSigSwitchedByIgnition" SG_ 885 ESC_54_BZ 0;
BA_ "GenSigSendType" SG_ 885 SOK_ESC_54_Signatur 0;
BA_ "GenSigFuncType" SG_ 885 SOK_ESC_54_Signatur 15;
BA_ "GenSigSwitchedByIgnition" SG_ 885 SOK_ESC_54_Signatur 0;
BA_ "GenSigSendType" SG_ 885 SSO_EdgeCount_Sum 0;
BA_ "GenSigSwitchedByIgnition" SG_ 885 SSO_EdgeCount_Sum 0;
BA_ "GenSigSendType" SG_ 2589283575 ESI_DRemOilChg 0;
BA_ "GenSigStartValue" SG_ 2589283575 ESI_DRemOilChg 65534;
BA_ "Fehlerwert" SG_ 2589283575 ESI_DRemOilChg 65535;
BA_ "GenSigSendType" SG_ 2589283575 ESI_StOilChg 0;
BA_ "GenSigSendType" SG_ 2589283575 ESI_TiRemOilChg 0;
BA_ "GenSigStartValue" SG_ 2589283575 ESI_TiRemOilChg 1022;
BA_ "Fehlerwert" SG_ 2589283575 ESI_TiRemOilChg 1023;
BA_ "GenSigSendType" SG_ 278 ESP_10_BZ 0;
BA_ "GenSigFuncType" SG_ 278 ESP_10_BZ 1;
BA_ "GenSigSwitchedByIgnition" SG_ 278 ESP_10_BZ 0;
BA_ "GenSigSendType" SG_ 278 ESP_10_CRC 0;
BA_ "GenSigFuncType" SG_ 278 ESP_10_CRC 2;
BA_ "GenSigSwitchedByIgnition" SG_ 278 ESP_10_CRC 0;
BA_ "GenSigSendType" SG_ 278 ESP_HL_Fahrtrichtung 0;
BA_ "GenSigStartValue" SG_ 278 ESP_HL_Fahrtrichtung 2;
BA_ "GenSigSwitchedByIgnition" SG_ 278 ESP_HL_Fahrtrichtung 0;
BA_ "GenSigSendType" SG_ 278 ESP_HR_Fahrtrichtung 0;
BA_ "GenSigStartValue" SG_ 278 ESP_HR_Fahrtrichtung 2;
BA_ "GenSigSwitchedByIgnition" SG_ 278 ESP_HR_Fahrtrichtung 0;
BA_ "GenSigSendType" SG_ 278 ESP_QBit_Wegimpuls_HL 0;
BA_ "GenSigStartValue" SG_ 278 ESP_QBit_Wegimpuls_HL 1;
BA_ "GenSigSwitchedByIgnition" SG_ 278 ESP_QBit_Wegimpuls_HL 0;
BA_ "GenSigSendType" SG_ 278 ESP_QBit_Wegimpuls_HR 0;
BA_ "GenSigStartValue" SG_ 278 ESP_QBit_Wegimpuls_HR 1;
BA_ "GenSigSwitchedByIgnition" SG_ 278 ESP_QBit_Wegimpuls_HR 0;
BA_ "GenSigSendType" SG_ 278 ESP_QBit_Wegimpuls_VL 0;
BA_ "GenSigStartValue" SG_ 278 ESP_QBit_Wegimpuls_VL 1;
BA_ "GenSigSwitchedByIgnition" SG_ 278 ESP_QBit_Wegimpuls_VL 0;
BA_ "GenSigSendType" SG_ 278 ESP_QBit_Wegimpuls_VR 0;
BA_ "GenSigStartValue" SG_ 278 ESP_QBit_Wegimpuls_VR 1;
BA_ "GenSigSwitchedByIgnition" SG_ 278 ESP_QBit_Wegimpuls_VR 0;
BA_ "GenSigSendType" SG_ 278 ESP_VL_Fahrtrichtung 0;
BA_ "GenSigStartValue" SG_ 278 ESP_VL_Fahrtrichtung 2;
BA_ "GenSigSwitchedByIgnition" SG_ 278 ESP_VL_Fahrtrichtung 0;
BA_ "GenSigSendType" SG_ 278 ESP_VR_Fahrtrichtung 0;
BA_ "GenSigStartValue" SG_ 278 ESP_VR_Fahrtrichtung 2;
BA_ "GenSigSwitchedByIgnition" SG_ 278 ESP_VR_Fahrtrichtung 0;
BA_ "GenSigSendType" SG_ 278 ESP_Wegimpuls_HL 0;
BA_ "GenSigStartValue" SG_ 278 ESP_Wegimpuls_HL 1021;
BA_ "GenSigSwitchedByIgnition" SG_ 278 ESP_Wegimpuls_HL 0;
BA_ "Fehlerwert" SG_ 278 ESP_Wegimpuls_HL 1023;
BA_ "GenSigSendType" SG_ 278 ESP_Wegimpuls_HR 0;
BA_ "GenSigStartValue" SG_ 278 ESP_Wegimpuls_HR 1021;
BA_ "GenSigSwitchedByIgnition" SG_ 278 ESP_Wegimpuls_HR 0;
BA_ "Fehlerwert" SG_ 278 ESP_Wegimpuls_HR 1023;
BA_ "GenSigSendType" SG_ 278 ESP_Wegimpuls_VL 0;
BA_ "GenSigStartValue" SG_ 278 ESP_Wegimpuls_VL 1021;
BA_ "GenSigSwitchedByIgnition" SG_ 278 ESP_Wegimpuls_VL 0;
BA_ "Fehlerwert" SG_ 278 ESP_Wegimpuls_VL 1023;
BA_ "GenSigSendType" SG_ 278 ESP_Wegimpuls_VR 0;
BA_ "GenSigStartValue" SG_ 278 ESP_Wegimpuls_VR 1021;
BA_ "GenSigSwitchedByIgnition" SG_ 278 ESP_Wegimpuls_VR 0;
BA_ "Fehlerwert" SG_ 278 ESP_Wegimpuls_VR 1023;
BA_ "GenSigSendType" SG_ 178 ESP_HL_Radgeschw_02 0;
BA_ "GenSigStartValue" SG_ 178 ESP_HL_Radgeschw_02 65534;
BA_ "GenSigSwitchedByIgnition" SG_ 178 ESP_HL_Radgeschw_02 0;
BA_ "Fehlerwert" SG_ 178 ESP_HL_Radgeschw_02 65535;
BA_ "GenSigSendType" SG_ 178 ESP_HR_Radgeschw_02 0;
BA_ "GenSigStartValue" SG_ 178 ESP_HR_Radgeschw_02 65534;
BA_ "GenSigSwitchedByIgnition" SG_ 178 ESP_HR_Radgeschw_02 0;
BA_ "Fehlerwert" SG_ 178 ESP_HR_Radgeschw_02 65535;
BA_ "GenSigSendType" SG_ 178 ESP_VL_Radgeschw_02 0;
BA_ "GenSigStartValue" SG_ 178 ESP_VL_Radgeschw_02 65534;
BA_ "GenSigSwitchedByIgnition" SG_ 178 ESP_VL_Radgeschw_02 0;
BA_ "Fehlerwert" SG_ 178 ESP_VL_Radgeschw_02 65535;
BA_ "GenSigSendType" SG_ 178 ESP_VR_Radgeschw_02 0;
BA_ "GenSigStartValue" SG_ 178 ESP_VR_Radgeschw_02 65534;
BA_ "GenSigSwitchedByIgnition" SG_ 178 ESP_VR_Radgeschw_02 0;
BA_ "Fehlerwert" SG_ 178 ESP_VR_Radgeschw_02 65535;
BA_ "GenSigSendType" SG_ 1629 BR_QBit_Reifenumfang 0;
BA_ "GenSigStartValue" SG_ 1629 BR_QBit_Reifenumfang 1;
BA_ "GenSigSwitchedByIgnition" SG_ 1629 BR_QBit_Reifenumfang 0;
BA_ "GenSigSendType" SG_ 1629 BR_Reifenumfang 0;
BA_ "GenSigSwitchedByIgnition" SG_ 1629 BR_Reifenumfang 0;
BA_ "GenSigSendType" SG_ 1629 BR_Systemart 0;
BA_ "GenSigFuncType" SG_ 1629 BR_Systemart 8;
BA_ "GenSigSwitchedByIgnition" SG_ 1629 BR_Systemart 0;
BA_ "GenSigSendType" SG_ 1629 ESP_20_BZ 0;
BA_ "GenSigFuncType" SG_ 1629 ESP_20_BZ 1;
BA_ "GenSigSwitchedByIgnition" SG_ 1629 ESP_20_BZ 0;
BA_ "GenSigSendType" SG_ 1629 ESP_20_CRC 0;
BA_ "GenSigFuncType" SG_ 1629 ESP_20_CRC 2;
BA_ "GenSigSwitchedByIgnition" SG_ 1629 ESP_20_CRC 0;
BA_ "GenSigSendType" SG_ 1629 ESP_Charisma_FahrPr 3;
BA_ "GenSigSwitchedByIgnition" SG_ 1629 ESP_Charisma_FahrPr 0;
BA_ "GenSigSendType" SG_ 1629 ESP_Charisma_Status 3;
BA_ "GenSigSwitchedByIgnition" SG_ 1629 ESP_Charisma_Status 0;
BA_ "GenSigSendType" SG_ 1629 ESP_Dachrelingsensor 0;
BA_ "GenSigSwitchedByIgnition" SG_ 1629 ESP_Dachrelingsensor 0;
BA_ "Fehlerwert" SG_ 1629 ESP_Dachrelingsensor 3;
BA_ "GenSigSendType" SG_ 1629 ESP_SpannungsAnf_02 3;
BA_ "GenSigSwitchedByIgnition" SG_ 1629 ESP_SpannungsAnf_02 0;
BA_ "GenSigSendType" SG_ 1629 ESP_Stoppverbot_Anz_01 3;
BA_ "GenSigSwitchedByIgnition" SG_ 1629 ESP_Stoppverbot_Anz_01 0;
BA_ "GenSigSendType" SG_ 1629 ESP_Stoppverbot_Anz_02 3;
BA_ "GenSigSwitchedByIgnition" SG_ 1629 ESP_Stoppverbot_Anz_02 0;
BA_ "GenSigSendType" SG_ 1629 ESP_Stoppverbot_Anz_03 3;
BA_ "GenSigSwitchedByIgnition" SG_ 1629 ESP_Stoppverbot_Anz_03 0;
BA_ "GenSigSendType" SG_ 1629 ESP_Stoppverbot_Anz_04 3;
BA_ "GenSigSwitchedByIgnition" SG_ 1629 ESP_Stoppverbot_Anz_04 0;
BA_ "GenSigSendType" SG_ 1629 ESP_Stoppverbot_Anz_05 3;
BA_ "GenSigSwitchedByIgnition" SG_ 1629 ESP_Stoppverbot_Anz_05 0;
BA_ "GenSigSendType" SG_ 1629 ESP_Stoppverbot_Anz_06 3;
BA_ "GenSigSwitchedByIgnition" SG_ 1629 ESP_Stoppverbot_Anz_06 0;
BA_ "GenSigSendType" SG_ 1629 ESP_Stoppverbot_Anz_07 3;
BA_ "GenSigSwitchedByIgnition" SG_ 1629 ESP_Stoppverbot_Anz_07 0;
BA_ "GenSigSendType" SG_ 1629 ESP_Stoppverbot_Anz_08 3;
BA_ "GenSigSwitchedByIgnition" SG_ 1629 ESP_Stoppverbot_Anz_08 0;
BA_ "GenSigSendType" SG_ 1629 ESP_Stoppverbot_Anz_Std 3;
BA_ "GenSigSwitchedByIgnition" SG_ 1629 ESP_Stoppverbot_Anz_Std 0;
BA_ "GenSigSendType" SG_ 1629 ESP_Wiederstart_Anz_01 3;
BA_ "GenSigSwitchedByIgnition" SG_ 1629 ESP_Wiederstart_Anz_01 0;
BA_ "GenSigSendType" SG_ 1629 ESP_Wiederstart_Anz_02 3;
BA_ "GenSigSwitchedByIgnition" SG_ 1629 ESP_Wiederstart_Anz_02 0;
BA_ "GenSigSendType" SG_ 1629 ESP_Wiederstart_Anz_03 3;
BA_ "GenSigSwitchedByIgnition" SG_ 1629 ESP_Wiederstart_Anz_03 0;
BA_ "GenSigSendType" SG_ 1629 ESP_Wiederstart_Anz_04 3;
BA_ "GenSigSwitchedByIgnition" SG_ 1629 ESP_Wiederstart_Anz_04 0;
BA_ "GenSigSendType" SG_ 1629 ESP_Zaehnezahl 0;
BA_ "GenSigFuncType" SG_ 1629 ESP_Zaehnezahl 8;
BA_ "GenSigSwitchedByIgnition" SG_ 1629 ESP_Zaehnezahl 0;
BA_ "GenSigSendType" SG_ 1629 HDC_Charisma_FahrPr 3;
BA_ "GenSigSwitchedByIgnition" SG_ 1629 HDC_Charisma_FahrPr 0;
BA_ "GenSigSendType" SG_ 1629 HDC_Charisma_Status 3;
BA_ "GenSigSwitchedByIgnition" SG_ 1629 HDC_Charisma_Status 0;
BA_ "GenSigSendType" SG_ 253 ABS_Bremsung 0;
BA_ "GenSigSwitchedByIgnition" SG_ 253 ABS_Bremsung 0;
BA_ "GenSigSendType" SG_ 253 ASR_Anf 0;
BA_ "GenSigSwitchedByIgnition" SG_ 253 ASR_Anf 0;
BA_ "GenSigSendType" SG_ 253 ASR_Schalteingriff 0;
BA_ "GenSigSwitchedByIgnition" SG_ 253 ASR_Schalteingriff 0;
BA_ "GenSigSendType" SG_ 253 ASR_Tastung_passiv 0;
BA_ "GenSigSwitchedByIgnition" SG_ 253 ASR_Tastung_passiv 0;
BA_ "GenSigSendType" SG_ 253 BR_Eingriffsmoment 0;
BA_ "GenSigStartValue" SG_ 253 BR_Eingriffsmoment 1022;
BA_ "GenSigSwitchedByIgnition" SG_ 253 BR_Eingriffsmoment 0;
BA_ "Fehlerwert" SG_ 253 BR_Eingriffsmoment 1023;
BA_ "GenSigSendType" SG_ 253 EBV_Eingriff 0;
BA_ "GenSigSwitchedByIgnition" SG_ 253 EBV_Eingriff 0;
BA_ "GenSigSendType" SG_ 253 EDS_Eingriff 0;
BA_ "GenSigSwitchedByIgnition" SG_ 253 EDS_Eingriff 0;
BA_ "GenSigSendType" SG_ 253 ESC_Reku_Freigabe 0;
BA_ "GenSigSwitchedByIgnition" SG_ 253 ESC_Reku_Freigabe 0;
BA_ "GenSigSendType" SG_ 253 ESC_v_Signal_Qualifier_High_Low 0;
BA_ "GenSigStartValue" SG_ 253 ESC_v_Signal_Qualifier_High_Low 6;
BA_ "GenSigSwitchedByIgnition" SG_ 253 ESC_v_Signal_Qualifier_High_Low 0;
BA_ "Fehlerwert" SG_ 253 ESC_v_Signal_Qualifier_High_Low 7;
BA_ "GenSigSendType" SG_ 253 ESP_21_BZ 0;
BA_ "GenSigFuncType" SG_ 253 ESP_21_BZ 1;
BA_ "GenSigSwitchedByIgnition" SG_ 253 ESP_21_BZ 0;
BA_ "GenSigSendType" SG_ 253 ESP_21_CRC 0;
BA_ "GenSigFuncType" SG_ 253 ESP_21_CRC 2;
BA_ "GenSigSwitchedByIgnition" SG_ 253 ESP_21_CRC 0;
BA_ "GenSigSendType" SG_ 253 ESP_Anhaltevorgang_ACC_aktiv 0;
BA_ "GenSigSwitchedByIgnition" SG_ 253 ESP_Anhaltevorgang_ACC_aktiv 0;
BA_ "GenSigSendType" SG_ 253 ESP_ASP 0;
BA_ "GenSigSwitchedByIgnition" SG_ 253 ESP_ASP 0;
BA_ "GenSigSendType" SG_ 253 ESP_AWV3_Brems_aktiv 0;
BA_ "GenSigSwitchedByIgnition" SG_ 253 ESP_AWV3_Brems_aktiv 0;
BA_ "GenSigSendType" SG_ 253 ESP_Diagnose 0;
BA_ "GenSigSwitchedByIgnition" SG_ 253 ESP_Diagnose 0;
BA_ "GenSigSendType" SG_ 253 ESP_Eingriff 0;
BA_ "GenSigSwitchedByIgnition" SG_ 253 ESP_Eingriff 0;
BA_ "GenSigSendType" SG_ 253 ESP_Haltebestaetigung 0;
BA_ "GenSigSwitchedByIgnition" SG_ 253 ESP_Haltebestaetigung 0;
BA_ "GenSigSendType" SG_ 253 ESP_MKB_Abbruch_Geschw 0;
BA_ "GenSigSwitchedByIgnition" SG_ 253 ESP_MKB_Abbruch_Geschw 0;
BA_ "GenSigSendType" SG_ 253 ESP_PLA_Bremseingriff 0;
BA_ "GenSigSwitchedByIgnition" SG_ 253 ESP_PLA_Bremseingriff 0;
BA_ "GenSigSendType" SG_ 253 ESP_QBit_v_Signal 0;
BA_ "GenSigStartValue" SG_ 253 ESP_QBit_v_Signal 1;
BA_ "GenSigSwitchedByIgnition" SG_ 253 ESP_QBit_v_Signal 0;
BA_ "GenSigSendType" SG_ 253 ESP_Systemstatus 0;
BA_ "GenSigSwitchedByIgnition" SG_ 253 ESP_Systemstatus 0;
BA_ "GenSigSendType" SG_ 253 ESP_Tastung_passiv 0;
BA_ "GenSigSwitchedByIgnition" SG_ 253 ESP_Tastung_passiv 0;
BA_ "GenSigSendType" SG_ 253 ESP_v_Signal 0;
BA_ "GenSigStartValue" SG_ 253 ESP_v_Signal 65534;
BA_ "GenSigSwitchedByIgnition" SG_ 253 ESP_v_Signal 0;
BA_ "Fehlerwert" SG_ 253 ESP_v_Signal 65535;
BA_ "GenSigMissingSourceValue" SG_ 253 ESP_v_Signal 65534;
BA_ "GenSigSendType" SG_ 253 ESP_Vorsteuerung 0;
BA_ "GenSigSwitchedByIgnition" SG_ 253 ESP_Vorsteuerung 0;
BA_ "GenSigSendType" SG_ 253 MSR_Anf 0;
BA_ "GenSigSwitchedByIgnition" SG_ 253 MSR_Anf 0;
BA_ "GenSigSendType" SG_ 253 OBD_QBit_Schlechtweg 0;
BA_ "GenSigStartValue" SG_ 253 OBD_QBit_Schlechtweg 1;
BA_ "GenSigSwitchedByIgnition" SG_ 253 OBD_QBit_Schlechtweg 0;
BA_ "GenSigSendType" SG_ 253 OBD_Schlechtweg 0;
BA_ "GenSigSwitchedByIgnition" SG_ 253 OBD_Schlechtweg 0;
BA_ "GenSigSendType" SG_ 795 ABS_Lampe 0;
BA_ "GenSigStartValue" SG_ 795 ABS_Lampe 1;
BA_ "GenSigSwitchedByIgnition" SG_ 795 ABS_Lampe 0;
BA_ "GenSigSendType" SG_ 795 BK_Lampe_02 0;
BA_ "GenSigStartValue" SG_ 795 BK_Lampe_02 1;
BA_ "GenSigSwitchedByIgnition" SG_ 795 BK_Lampe_02 0;
BA_ "GenSigSendType" SG_ 795 ESP_24_BZ 0;
BA_ "GenSigFuncType" SG_ 795 ESP_24_BZ 1;
BA_ "GenSigSwitchedByIgnition" SG_ 795 ESP_24_BZ 0;
BA_ "GenSigSendType" SG_ 795 ESP_24_CRC 0;
BA_ "GenSigFuncType" SG_ 795 ESP_24_CRC 2;
BA_ "GenSigSwitchedByIgnition" SG_ 795 ESP_24_CRC 0;
BA_ "GenSigSendType" SG_ 795 ESP_BKV_Warnung 0;
BA_ "GenSigSwitchedByIgnition" SG_ 795 ESP_BKV_Warnung 0;
BA_ "GenSigSendType" SG_ 795 ESP_Fehlerstatus_Wegimp 0;
BA_ "GenSigSwitchedByIgnition" SG_ 795 ESP_Fehlerstatus_Wegimp 0;
BA_ "GenSigSendType" SG_ 795 ESP_HDC_FktLampe 0;
BA_ "GenSigSwitchedByIgnition" SG_ 795 ESP_HDC_FktLampe 0;
BA_ "GenSigSendType" SG_ 795 ESP_HDC_Regelgeschw 0;
BA_ "GenSigStartValue" SG_ 795 ESP_HDC_Regelgeschw 126;
BA_ "GenSigSwitchedByIgnition" SG_ 795 ESP_HDC_Regelgeschw 0;
BA_ "Fehlerwert" SG_ 795 ESP_HDC_Regelgeschw 127;
BA_ "GenSigSendType" SG_ 795 ESP_Lampe 0;
BA_ "GenSigSwitchedByIgnition" SG_ 795 ESP_Lampe 0;
BA_ "GenSigSendType" SG_ 795 ESP_m_Raddrehz 0;
BA_ "GenSigStartValue" SG_ 795 ESP_m_Raddrehz 32766;
BA_ "GenSigSwitchedByIgnition" SG_ 795 ESP_m_Raddrehz 0;
BA_ "Fehlerwert" SG_ 795 ESP_m_Raddrehz 32767;
BA_ "GenSigSendType" SG_ 795 ESP_Meldungen 0;
BA_ "GenSigSwitchedByIgnition" SG_ 795 ESP_Meldungen 0;
BA_ "GenSigSendType" SG_ 795 ESP_Off_Lampe 0;
BA_ "GenSigSwitchedByIgnition" SG_ 795 ESP_Off_Lampe 0;
BA_ "GenSigSendType" SG_ 795 ESP_QBit_Wegimp_VA 0;
BA_ "GenSigStartValue" SG_ 795 ESP_QBit_Wegimp_VA 1;
BA_ "GenSigSwitchedByIgnition" SG_ 795 ESP_QBit_Wegimp_VA 0;
BA_ "GenSigSendType" SG_ 795 ESP_Textanzeigen_03 0;
BA_ "GenSigSwitchedByIgnition" SG_ 795 ESP_Textanzeigen_03 0;
BA_ "GenSigSendType" SG_ 795 ESP_Wegimp_Ueberlauf 0;
BA_ "GenSigSwitchedByIgnition" SG_ 795 ESP_Wegimp_Ueberlauf 0;
BA_ "GenSigSendType" SG_ 795 ESP_Wegimp_VA 0;
BA_ "GenSigSwitchedByIgnition" SG_ 795 ESP_Wegimp_VA 0;
BA_ "GenSigSendType" SG_ 795 TC_Lampe 0;
BA_ "GenSigSwitchedByIgnition" SG_ 795 TC_Lampe 0;
BA_ "GenSigSendType" SG_ 2589283617 DBK_Fahrerwarnung 0;
BA_ "GenSigSwitchedByIgnition" SG_ 2589283617 DBK_Fahrerwarnung 0;
BA_ "GenSigSendType" SG_ 2589283617 EDS_Charisma_FahrPr 3;
BA_ "GenSigSwitchedByIgnition" SG_ 2589283617 EDS_Charisma_FahrPr 0;
BA_ "GenSigSendType" SG_ 2589283617 EDS_Charisma_Status 3;
BA_ "GenSigSwitchedByIgnition" SG_ 2589283617 EDS_Charisma_Status 0;
BA_ "GenSigSendType" SG_ 2589283617 ESC_Anf_KL 0;
BA_ "GenSigSwitchedByIgnition" SG_ 2589283617 ESC_Anf_KL 0;
BA_ "GenSigSendType" SG_ 2589283617 ESC_Anf_KV 0;
BA_ "GenSigSwitchedByIgnition" SG_ 2589283617 ESC_Anf_KV 0;
BA_ "GenSigSendType" SG_ 2589283617 ESC_FBA_Meldungen 3;
BA_ "GenSigSwitchedByIgnition" SG_ 2589283617 ESC_FBA_Meldungen 0;
BA_ "GenSigSendType" SG_ 2589283617 ESC_Lernfreigabe_Abrollumfang 3;
BA_ "GenSigSwitchedByIgnition" SG_ 2589283617 ESC_Lernfreigabe_Abrollumfang 0;
BA_ "GenSigSendType" SG_ 2589283617 ESC_MBK_Meldungen 3;
BA_ "GenSigSwitchedByIgnition" SG_ 2589283617 ESC_MBK_Meldungen 0;
BA_ "GenSigSendType" SG_ 2589283617 ESC_Texte_eBKV_Betaetigung 3;
BA_ "GenSigSwitchedByIgnition" SG_ 2589283617 ESC_Texte_eBKV_Betaetigung 0;
BA_ "GenSigSendType" SG_ 2589283617 ESP_30_BZ 0;
BA_ "GenSigFuncType" SG_ 2589283617 ESP_30_BZ 1;
BA_ "GenSigSwitchedByIgnition" SG_ 2589283617 ESP_30_BZ 0;
BA_ "GenSigSendType" SG_ 2589283617 ESP_30_CRC 0;
BA_ "GenSigFuncType" SG_ 2589283617 ESP_30_CRC 2;
BA_ "GenSigSwitchedByIgnition" SG_ 2589283617 ESP_30_CRC 0;
BA_ "GenSigSendType" SG_ 2589283617 ESP_Off_Anf_KBI 3;
BA_ "GenSigSwitchedByIgnition" SG_ 2589283617 ESP_Off_Anf_KBI 0;
BA_ "GenSigSendType" SG_ 2589283617 ESP_Status_Bremsentemp_Anz 3;
BA_ "GenSigSwitchedByIgnition" SG_ 2589283617 ESP_Status_Bremsentemp_Anz 0;
BA_ "Fehlerwert" SG_ 2589283617 ESP_Status_Bremsentemp_Anz 7;
BA_ "GenSigSendType" SG_ 2589283617 FBC_Fahrerwarnung 0;
BA_ "GenSigSwitchedByIgnition" SG_ 2589283617 FBC_Fahrerwarnung 0;
BA_ "GenSigSendType" SG_ 2589283617 HHC_Charisma_FahrPr 3;
BA_ "GenSigSwitchedByIgnition" SG_ 2589283617 HHC_Charisma_FahrPr 0;
BA_ "GenSigSendType" SG_ 2589283617 HHC_Charisma_Status 3;
BA_ "GenSigSwitchedByIgnition" SG_ 2589283617 HHC_Charisma_Status 0;
BA_ "GenSigSendType" SG_ 2589283617 RLE_Anzeigen 0;
BA_ "GenSigSwitchedByIgnition" SG_ 2589283617 RLE_Anzeigen 0;
BA_ "GenSigSendType" SG_ 707 eAWS_Warnmeldung_Prio3 0;
BA_ "GenSigSwitchedByIgnition" SG_ 707 eAWS_Warnmeldung_Prio3 0;
BA_ "GenSigSendType" SG_ 707 EFP_Anf_Kuehlklappenwarnung 0;
BA_ "GenSigSwitchedByIgnition" SG_ 707 EFP_Anf_Kuehlklappenwarnung 0;
BA_ "GenSigSendType" SG_ 707 FA_Warnung_Transportniveau 0;
BA_ "GenSigSwitchedByIgnition" SG_ 707 FA_Warnung_Transportniveau 0;
BA_ "GenSigSendType" SG_ 707 FDR_M_HL_02 0;
BA_ "GenSigStartValue" SG_ 707 FDR_M_HL_02 254;
BA_ "GenSigSwitchedByIgnition" SG_ 707 FDR_M_HL_02 0;
BA_ "Fehlerwert" SG_ 707 FDR_M_HL_02 255;
BA_ "GenSigSendType" SG_ 707 FDR_M_HR_02 0;
BA_ "GenSigStartValue" SG_ 707 FDR_M_HR_02 254;
BA_ "GenSigSwitchedByIgnition" SG_ 707 FDR_M_HR_02 0;
BA_ "Fehlerwert" SG_ 707 FDR_M_HR_02 255;
BA_ "GenSigSendType" SG_ 707 FDR_M_VL_02 0;
BA_ "GenSigStartValue" SG_ 707 FDR_M_VL_02 254;
BA_ "GenSigSwitchedByIgnition" SG_ 707 FDR_M_VL_02 0;
BA_ "Fehlerwert" SG_ 707 FDR_M_VL_02 255;
BA_ "GenSigSendType" SG_ 707 FDR_M_VR_02 0;
BA_ "GenSigStartValue" SG_ 707 FDR_M_VR_02 254;
BA_ "GenSigSwitchedByIgnition" SG_ 707 FDR_M_VR_02 0;
BA_ "Fehlerwert" SG_ 707 FDR_M_VR_02 255;
BA_ "GenSigSendType" SG_ 2589283684 FoD_Transmission_Info 3;
BA_ "GenSigSwitchedByIgnition" SG_ 2589283684 FoD_Transmission_Info 0;
BA_ "GenSigSendType" SG_ 2589283684 GRA_FoD_Status 4;
BA_ "GenSigSwitchedByIgnition" SG_ 2589283684 GRA_FoD_Status 0;
BA_ "GenSigSendType" SG_ 2549875476 FoD_Kombi_Req_Data 3;
BA_ "GenSigFuncType" SG_ 2549875476 FoD_Kombi_Req_Data 9;
BA_ "GenSigSwitchedByIgnition" SG_ 2549875476 FoD_Kombi_Req_Data 0;
BA_ "GenSigSendType" SG_ 2550006548 FoD_Kombi_Resp_Data 3;
BA_ "GenSigFuncType" SG_ 2550006548 FoD_Kombi_Resp_Data 9;
BA_ "GenSigSwitchedByIgnition" SG_ 2550006548 FoD_Kombi_Resp_Data 0;
BA_ "GenSigSendType" SG_ 2549875500 FoD_MFG_Req_Data 3;
BA_ "GenSigFuncType" SG_ 2549875500 FoD_MFG_Req_Data 9;
BA_ "GenSigSwitchedByIgnition" SG_ 2549875500 FoD_MFG_Req_Data 0;
BA_ "GenSigSendType" SG_ 2550006572 FoD_MFG_Resp_Data 3;
BA_ "GenSigFuncType" SG_ 2550006572 FoD_MFG_Resp_Data 9;
BA_ "GenSigSwitchedByIgnition" SG_ 2550006572 FoD_MFG_Resp_Data 0;
BA_ "GenSigSendType" SG_ 986 ABS_Bremsung 0;
BA_ "GenSigSwitchedByIgnition" SG_ 986 ABS_Bremsung 0;
BA_ "GenSigSendType" SG_ 986 ECD_Bremslicht 3;
BA_ "GenSigSwitchedByIgnition" SG_ 986 ECD_Bremslicht 0;
BA_ "GenSigSendType" SG_ 986 EPB_01_alt 0;
BA_ "GenSigStartValue" SG_ 986 EPB_01_alt 1;
BA_ "GenSigFuncType" SG_ 986 EPB_01_alt 5;
BA_ "GenSigSwitchedByIgnition" SG_ 986 EPB_01_alt 0;
BA_ "GenSigSendType" SG_ 986 EPB_Pedalweg_Kuppl 0;
BA_ "GenSigSwitchedByIgnition" SG_ 986 EPB_Pedalweg_Kuppl 0;
BA_ "Fehlerwert" SG_ 986 EPB_Pedalweg_Kuppl 255;
BA_ "GenSigSendType" SG_ 986 EPB_QBit_Pedalweg_Kuppl 0;
BA_ "GenSigStartValue" SG_ 986 EPB_QBit_Pedalweg_Kuppl 1;
BA_ "GenSigSwitchedByIgnition" SG_ 986 EPB_QBit_Pedalweg_Kuppl 0;
BA_ "GenSigSendType" SG_ 986 EPB_Status 0;
BA_ "GenSigSwitchedByIgnition" SG_ 986 EPB_Status 0;
BA_ "GenSigSendType" SG_ 986 ESP_05_alt 0;
BA_ "GenSigStartValue" SG_ 986 ESP_05_alt 1;
BA_ "GenSigFuncType" SG_ 986 ESP_05_alt 5;
BA_ "GenSigSwitchedByIgnition" SG_ 986 ESP_05_alt 0;
BA_ "GenSigSendType" SG_ 986 ESP_21_alt 0;
BA_ "GenSigStartValue" SG_ 986 ESP_21_alt 1;
BA_ "GenSigFuncType" SG_ 986 ESP_21_alt 5;
BA_ "GenSigSwitchedByIgnition" SG_ 986 ESP_21_alt 0;
BA_ "GenSigSendType" SG_ 986 ESP_Eingriff 0;
BA_ "GenSigSwitchedByIgnition" SG_ 986 ESP_Eingriff 0;
BA_ "GenSigSendType" SG_ 986 ESP_HDC_Standby 0;
BA_ "GenSigSendType" SG_ 986 ESP_MKB_Abbruch_Geschw 3;
BA_ "GenSigSwitchedByIgnition" SG_ 986 ESP_MKB_Abbruch_Geschw 0;
BA_ "GenSigSendType" SG_ 986 ESP_QBit_v_Signal 0;
BA_ "GenSigStartValue" SG_ 986 ESP_QBit_v_Signal 1;
BA_ "GenSigSwitchedByIgnition" SG_ 986 ESP_QBit_v_Signal 0;
BA_ "GenSigSendType" SG_ 986 ESP_v_Signal 0;
BA_ "GenSigStartValue" SG_ 986 ESP_v_Signal 65534;
BA_ "GenSigSwitchedByIgnition" SG_ 986 ESP_v_Signal 0;
BA_ "Fehlerwert" SG_ 986 ESP_v_Signal 65535;
BA_ "GenSigMissingSourceValue" SG_ 986 ESP_v_Signal 65534;
BA_ "GenSigSendType" SG_ 986 Kamera_FSH_aktiv 0;
BA_ "GenSigSendType" SG_ 986 Kamera_Status_alt 0;
BA_ "GenSigStartValue" SG_ 986 Kamera_Status_alt 1;
BA_ "GenSigFuncType" SG_ 986 Kamera_Status_alt 5;
BA_ "GenSigSwitchedByIgnition" SG_ 986 Kamera_Status_alt 0;
BA_ "GenSigSendType" SG_ 986 LWI_01_alt 0;
BA_ "GenSigStartValue" SG_ 986 LWI_01_alt 1;
BA_ "GenSigFuncType" SG_ 986 LWI_01_alt 5;
BA_ "GenSigSwitchedByIgnition" SG_ 986 LWI_01_alt 0;
BA_ "GenSigSendType" SG_ 986 LWI_Lenkradwinkel 0;
BA_ "GenSigStartValue" SG_ 986 LWI_Lenkradwinkel 8190;
BA_ "Fehlerwert" SG_ 986 LWI_Lenkradwinkel 8191;
BA_ "GenSigSendType" SG_ 986 LWI_QBit_Lenkradwinkel 0;
BA_ "GenSigStartValue" SG_ 986 LWI_QBit_Lenkradwinkel 1;
BA_ "GenSigSendType" SG_ 986 LWI_Sensorstatus 0;
BA_ "GenSigSendType" SG_ 986 LWI_VZ_Lenkradwinkel 0;
BA_ "GenSigSendType" SG_ 986 Parkhilfe_01_alt 0;
BA_ "GenSigStartValue" SG_ 986 Parkhilfe_01_alt 1;
BA_ "GenSigFuncType" SG_ 986 Parkhilfe_01_alt 5;
BA_ "GenSigSwitchedByIgnition" SG_ 986 Parkhilfe_01_alt 0;
BA_ "GenSigSendType" SG_ 986 PH_Anf_Audioabsenkung 0;
BA_ "GenSigSendType" SG_ 986 PH_Systemzustand 0;
BA_ "GenSigSendType" SG_ 986 PH_Taster 3;
BA_ "Fehlerwert" SG_ 986 PH_Taster 3;
BA_ "GenSigSendType" SG_ 986 PLA_Anf_Aufschaltung_RVC 3;
BA_REL_ "GenSigTimeoutTime" BU_SG_REL_ ELV SG_ 1714 DGN_Verlernzaehler 5000;
BA_REL_ "GenSigTimeoutTime" BU_SG_REL_ ELV SG_ 1714 KBI_Kilometerstand 5000;
BA_REL_ "GenSigTimeoutTime" BU_SG_REL_ ELV SG_ 1714 UH_Jahr 5000;
BA_REL_ "GenSigTimeoutTime" BU_SG_REL_ ELV SG_ 1714 UH_Monat 5000;
BA_REL_ "GenSigTimeoutTime" BU_SG_REL_ ELV SG_ 1714 UH_Tag 5000;
BA_REL_ "GenSigTimeoutTime" BU_SG_REL_ ELV SG_ 1714 UH_Stunde 5000;
BA_REL_ "GenSigTimeoutTime" BU_SG_REL_ ELV SG_ 1714 UH_Minute 5000;
BA_REL_ "GenSigTimeoutTime" BU_SG_REL_ ELV SG_ 1714 UH_Sekunde 5000;
BA_REL_ "GenSigTimeoutTime" BU_SG_REL_ ELV SG_ 278 ESP_10_CRC 1000;
BA_REL_ "GenSigTimeoutTime" BU_SG_REL_ ELV SG_ 278 ESP_10_BZ 1000;
BA_REL_ "GenSigTimeoutTime" BU_SG_REL_ ELV SG_ 278 ESP_QBit_Wegimpuls_VL 1000;
BA_REL_ "GenSigTimeoutTime" BU_SG_REL_ ELV SG_ 278 ESP_QBit_Wegimpuls_VR 1000;
BA_REL_ "GenSigTimeoutTime" BU_SG_REL_ ELV SG_ 278 ESP_QBit_Wegimpuls_HL 1000;
BA_REL_ "GenSigTimeoutTime" BU_SG_REL_ ELV SG_ 278 ESP_QBit_Wegimpuls_HR 1000;
BA_REL_ "GenSigTimeoutTime" BU_SG_REL_ ELV SG_ 278 ESP_Wegimpuls_VL 1000;
BA_REL_ "GenSigTimeoutTime" BU_SG_REL_ ELV SG_ 278 ESP_Wegimpuls_VR 1000;
BA_REL_ "GenSigTimeoutTime" BU_SG_REL_ ELV SG_ 278 ESP_Wegimpuls_HL 1000;
BA_REL_ "GenSigTimeoutTime" BU_SG_REL_ ELV SG_ 278 ESP_Wegimpuls_HR 1000;
BA_REL_ "GenSigTimeoutTime" BU_SG_REL_ ELV SG_ 253 ESP_21_CRC 500;
BA_REL_ "GenSigTimeoutTime" BU_SG_REL_ ELV SG_ 253 ESP_21_BZ 500;
BA_REL_ "GenSigTimeoutTime" BU_SG_REL_ ELV SG_ 253 ESP_v_Signal 500;
BA_REL_ "GenSigTimeoutTime" BU_SG_REL_ ELV SG_ 253 ESP_QBit_v_Signal 500;
BA_REL_ "GenSigTimeoutTime" BU_SG_REL_ Gateway_Max SG_ 1603 KBI_Einheit_Streckenanz 5000;
BA_REL_ "GenSigTimeoutTime" BU_SG_REL_ Gateway_Max SG_ 1603 KBI_Einheit_Temp 5000;
BA_REL_ "GenSigTimeoutTime" BU_SG_REL_ Gateway_Max SG_ 1603 KBI_Einheit_Verbrauch 5000;
BA_REL_ "GenSigTimeoutTime" BU_SG_REL_ Gateway_Max SG_ 1603 KBI_Einheit_Verbrauch_Gas 5000;
BA_REL_ "GenSigTimeoutTime" BU_SG_REL_ HUD SG_ 1714 DGN_Verlernzaehler 5000;
BA_REL_ "GenSigTimeoutTime" BU_SG_REL_ HUD SG_ 1714 KBI_Kilometerstand 5000;
BA_REL_ "GenSigTimeoutTime" BU_SG_REL_ HUD SG_ 1714 UH_Jahr 5000;
BA_REL_ "GenSigTimeoutTime" BU_SG_REL_ HUD SG_ 1714 UH_Monat 5000;
BA_REL_ "GenSigTimeoutTime" BU_SG_REL_ HUD SG_ 1714 UH_Tag 5000;
BA_REL_ "GenSigTimeoutTime" BU_SG_REL_ HUD SG_ 1714 UH_Stunde 5000;
BA_REL_ "GenSigTimeoutTime" BU_SG_REL_ HUD SG_ 1714 UH_Minute 5000;
BA_REL_ "GenSigTimeoutTime" BU_SG_REL_ HUD SG_ 1714 UH_Sekunde 5000;
BA_REL_ "GenSigTimeoutTime" BU_SG_REL_ HUD SG_ 1520 DI_Display_Nachtdesign 2000;
BA_REL_ "GenSigTimeoutTime" BU_SG_REL_ HUD SG_ 1520 BCM1_Stellgroesse_Kl_58s 2000;
BA_REL_ "GenSigTimeoutTime" BU_SG_REL_ HUD SG_ 496 EA_Texte 5000;
BA_REL_ "GenSigTimeoutTime" BU_SG_REL_ HUD SG_ 496 EA_Status_HMI 5000;
BA_REL_ "GenSigTimeoutTime" BU_SG_REL_ HUD SG_ 1603 KBI_MFA_v_Einheit_02 5000;
BA_REL_ "GenSigTimeoutTime" BU_SG_REL_ HUD SG_ 1603 KBI_Einheit_Temp 5000;
BA_REL_ "GenSigTimeoutTime" BU_SG_REL_ HUD SG_ 1603 KBI_Einheit_Sprache 5000;
BA_REL_ "GenSigTimeoutTime" BU_SG_REL_ HUD SG_ 795 ESP_HDC_Regelgeschw 500;
BA_REL_ "GenSigTimeoutTime" BU_SG_REL_ HUD SG_ 986 LWI_VZ_Lenkradwinkel 1000;
BA_REL_ "GenSigTimeoutTime" BU_SG_REL_ HUD SG_ 986 LWI_Lenkradwinkel 1000;
BA_REL_ "GenSigTimeoutTime" BU_SG_REL_ Kombi SG_ 2527679921 CPDFct_Warnung 2000;
BA_REL_ "GenSigTimeoutTime" BU_SG_REL_ Kombi SG_ 2527679921 CPDFct_Symbol 2000;
BA_REL_ "GenSigTimeoutTime" BU_SG_REL_ Kombi SG_ 918 DR_Gelbe_Warnlampe 1000;
BA_REL_ "GenSigTimeoutTime" BU_SG_REL_ Kombi SG_ 1012 DC_Verbrauch_Ueberlauf 500;
BA_REL_ "GenSigTimeoutTime" BU_SG_REL_ Kombi SG_ 1012 DC_Verbrauch 500;
BA_REL_ "GenSigTimeoutTime" BU_SG_REL_ Kombi SG_ 1714 DGN_Verlernzaehler 5000;
BA_REL_ "GenSigTimeoutTime" BU_SG_REL_ Kombi SG_ 1714 KBI_Kilometerstand 5000;
BA_REL_ "GenSigTimeoutTime" BU_SG_REL_ Kombi SG_ 1714 UH_Jahr 5000;
BA_REL_ "GenSigTimeoutTime" BU_SG_REL_ Kombi SG_ 1714 UH_Monat 5000;
BA_REL_ "GenSigTimeoutTime" BU_SG_REL_ Kombi SG_ 1714 UH_Tag 5000;
BA_REL_ "GenSigTimeoutTime" BU_SG_REL_ Kombi SG_ 1714 UH_Stunde 5000;
BA_REL_ "GenSigTimeoutTime" BU_SG_REL_ Kombi SG_ 1714 UH_Minute 5000;
BA_REL_ "GenSigTimeoutTime" BU_SG_REL_ Kombi SG_ 1714 UH_Sekunde 5000;
BA_REL_ "GenSigTimeoutTime" BU_SG_REL_ Kombi SG_ 1520 DI_KL_58xd 2000;
BA_REL_ "GenSigTimeoutTime" BU_SG_REL_ Kombi SG_ 1520 DI_KL_58xs 2000;
BA_REL_ "GenSigTimeoutTime" BU_SG_REL_ Kombi SG_ 1520 DI_Display_Nachtdesign 2000;
BA_REL_ "GenSigTimeoutTime" BU_SG_REL_ Kombi SG_ 1520 DI_KL_58xt 2000;
BA_REL_ "GenSigTimeoutTime" BU_SG_REL_ Kombi SG_ 496 EA_Texte 5000;
BA_REL_ "GenSigTimeoutTime" BU_SG_REL_ Kombi SG_ 496 EA_Status_HMI 5000;
BA_REL_ "GenSigTimeoutTime" BU_SG_REL_ Kombi SG_ 1622 ELV_Verriegelt 5000;
BA_REL_ "GenSigTimeoutTime" BU_SG_REL_ Kombi SG_ 1622 ELV_Entriegelt 5000;
BA_REL_ "GenSigTimeoutTime" BU_SG_REL_ Kombi SG_ 1622 ELV_LED_Rot 5000;
BA_REL_ "GenSigTimeoutTime" BU_SG_REL_ Kombi SG_ 1622 ELV_Txt_Lkg_Bewegen 5000;
BA_REL_ "GenSigTimeoutTime" BU_SG_REL_ Kombi SG_ 1622 ELV_Txt_Werkstatt 5000;
BA_REL_ "GenSigTimeoutTime" BU_SG_REL_ Kombi SG_ 1622 ELV_Txt_Defekt 5000;
BA_REL_ "GenSigTimeoutTime" BU_SG_REL_ Kombi SG_ 184 LE_Kuehlmittel_Sensor 5000;
BA_REL_ "GenSigTimeoutTime" BU_SG_REL_ Kombi SG_ 2589283970 DIST_DKmtg_Auth 5000;
BA_REL_ "GenSigTimeoutTime" BU_SG_REL_ Kombi SG_ 2589283970 SOK_Entfernung_02_Signatur 5000;
BA_REL_ "GenSigTimeoutTime" BU_SG_REL_ Kombi SG_ 2331595989 DIST_DKmtg 500;
BA_REL_ "GenSigTimeoutTime" BU_SG_REL_ Kombi SG_ 2589283751 KBI_Kilometerstand_Extended 5000;
BA_REL_ "GenSigTimeoutTime" BU_SG_REL_ Kombi SG_ 2589283751 KBI_Kilometerstand_HiRes_meter 5000;
BA_REL_ "GenSigTimeoutTime" BU_SG_REL_ Kombi SG_ 503 EPB_03_CRC 2000;
BA_REL_ "GenSigTimeoutTime" BU_SG_REL_ Kombi SG_ 503 EPB_03_BZ 2000;
BA_REL_ "GenSigTimeoutTime" BU_SG_REL_ Kombi SG_ 503 EPB_Texte_02 2000;
BA_REL_ "GenSigTimeoutTime" BU_SG_REL_ Kombi SG_ 503 EPB_Fehlermeldungen_02 2000;
BA_REL_ "GenSigTimeoutTime" BU_SG_REL_ Kombi SG_ 503 EPB_Funktionslampe_02 2000;
BA_REL_ "GenSigTimeoutTime" BU_SG_REL_ Kombi SG_ 503 EPB_Autoholdlampe_02 2000;
BA_REL_ "GenSigTimeoutTime" BU_SG_REL_ Kombi SG_ 503 EPB_Autohold_Standbyanzeige 2000;
BA_REL_ "GenSigTimeoutTime" BU_SG_REL_ Kombi SG_ 258 ESP_QBit_Laengsbeschl 500;
BA_REL_ "GenSigTimeoutTime" BU_SG_REL_ Kombi SG_ 258 ESP_QBit_Querb 500;
BA_REL_ "GenSigTimeoutTime" BU_SG_REL_ Kombi SG_ 258 ESP_Querbeschleunigung 500;
BA_REL_ "GenSigTimeoutTime" BU_SG_REL_ Kombi SG_ 258 ESP_Laengsbeschl 500;
BA_REL_ "GenSigTimeoutTime" BU_SG_REL_ Kombi SG_ 885 ESC_54_BZ 500;
BA_REL_ "GenSigTimeoutTime" BU_SG_REL_ Kombi SG_ 885 SSO_EdgeCount_Sum 500;
BA_REL_ "GenSigTimeoutTime" BU_SG_REL_ Kombi SG_ 885 SOK_ESC_54_Signatur 500;
BA_REL_ "GenSigTimeoutTime" BU_SG_REL_ Kombi SG_ 1629 BR_Systemart 5000;
BA_REL_ "GenSigTimeoutTime" BU_SG_REL_ Kombi SG_ 1629 ESP_Zaehnezahl 5000;
BA_REL_ "GenSigTimeoutTime" BU_SG_REL_ Kombi SG_ 795 ESP_24_CRC 500;
BA_REL_ "GenSigTimeoutTime" BU_SG_REL_ Kombi SG_ 795 ESP_24_BZ 500;
BA_REL_ "GenSigTimeoutTime" BU_SG_REL_ Kombi SG_ 795 ESP_Lampe 500;
BA_REL_ "GenSigTimeoutTime" BU_SG_REL_ Kombi SG_ 795 ABS_Lampe 500;
BA_REL_ "GenSigTimeoutTime" BU_SG_REL_ Kombi SG_ 795 BK_Lampe_02 500;
BA_REL_ "GenSigTimeoutTime" BU_SG_REL_ Kombi SG_ 795 ESP_m_Raddrehz 500;
BA_REL_ "GenSigTimeoutTime" BU_SG_REL_ Kombi SG_ 795 ESP_Textanzeigen_03 500;
BA_REL_ "GenSigTimeoutTime" BU_SG_REL_ Kombi SG_ 795 ESP_Meldungen 500;
BA_REL_ "GenSigTimeoutTime" BU_SG_REL_ Kombi SG_ 795 ESP_Wegimp_VA 500;
BA_REL_ "GenSigTimeoutTime" BU_SG_REL_ Kombi SG_ 795 ESP_Wegimp_Ueberlauf 500;
BA_REL_ "GenSigTimeoutTime" BU_SG_REL_ Kombi SG_ 795 ESP_Off_Lampe 500;
BA_REL_ "GenSigTimeoutTime" BU_SG_REL_ Kombi SG_ 795 ESP_HDC_Regelgeschw 500;
BA_REL_ "GenSigTimeoutTime" BU_SG_REL_ Kombi SG_ 795 ESP_BKV_Warnung 500;
BA_REL_ "GenSigTimeoutTime" BU_SG_REL_ Kombi SG_ 2589283617 ESP_30_CRC 5000;
BA_REL_ "GenSigTimeoutTime" BU_SG_REL_ Kombi SG_ 2589283617 ESP_30_BZ 5000;
BA_REL_ "GenSigTimeoutTime" BU_SG_REL_ Kombi SG_ 2589283617 RLE_Anzeigen 5000;
BA_REL_ "GenSigTimeoutTime" BU_SG_REL_ Kombi SG_ 2589283617 ESC_Lernfreigabe_Abrollumfang 5000;
BA_REL_ "GenSigTimeoutTime" BU_SG_REL_ Kombi SG_ 2589283617 ESC_FBA_Meldungen 5000;
BA_REL_ "GenSigTimeoutTime" BU_SG_REL_ Kombi SG_ 2589283617 DBK_Fahrerwarnung 5000;
BA_REL_ "GenSigTimeoutTime" BU_SG_REL_ Kombi SG_ 2589283617 ESP_Off_Anf_KBI 5000;
BA_REL_ "GenSigTimeoutTime" BU_SG_REL_ Kombi SG_ 2589283617 FBC_Fahrerwarnung 5000;
BA_REL_ "GenSigTimeoutTime" BU_SG_REL_ Kombi SG_ 707 FDR_M_HL_02 1000;
BA_REL_ "GenSigTimeoutTime" BU_SG_REL_ Kombi SG_ 707 FDR_M_HR_02 1000;
BA_REL_ "GenSigTimeoutTime" BU_SG_REL_ Kombi SG_ 707 FDR_M_VL_02 1000;
BA_REL_ "GenSigTimeoutTime" BU_SG_REL_ Kombi SG_ 707 FDR_M_VR_02 1000;
BA_REL_ "GenSigTimeoutTime" BU_SG_REL_ Kombi SG_ 986 LWI_VZ_Lenkradwinkel 1000;
BA_REL_ "GenSigTimeoutTime" BU_SG_REL_ Kombi SG_ 986 LWI_Lenkradwinkel 1000;
VAL_ 2527679921 CPD_CallCenter 0 "Init_keine_Alarmierung_CallCenter" 1 "CPD_Alarmierung_CallCenter" 2 "CPD_Abbruch_CallCenter" 3 "reserved" ;
VAL_ 2527679921 CPD_Deaktivierung_Temp 0 "InitWert" 1 "keine_Deaktivierung_Temp" 2 "CPD_Deaktivierung_Temp" ;
VAL_ 2527679921 CPD_Deaktivierung_Permanent 0 "InitWert" 1 "keine_Deaktivierung_Permanent" 2 "CPD_Deaktivierung_Permanent" ;
VAL_ 2527679921 CPD_Mobiltelefon_GSM 0 "Init_keine_Warnung_GSM" 1 "CPD_Warnung_GSM" 2 "reserved" 3 "reserved" ;
VAL_ 2527679921 CPD_Mobiltelefon_BLE 0 "Init_keine_Warnung_BT" 1 "CPD_Warnung_BT" ;
VAL_ 2527679921 CPDFct_Warnung 0 "keine_Anzeige" 1 "Warnung_mit_Ton" 2 "Warnung_ohne_Ton" 3 "Anzeige_Funktion_deaktiviert" 4 "Anzeige_Systemfehler" ;
VAL_ 2527679921 CPDFct_Symbol 0 "Keine_Anzeige" 1 "aktiv" ;
VAL_ 2527679921 CPDFct_Deakt 0 "keine_Anzeige" 1 "Anzeige_Funktion_deaktiviert" ;
VAL_ 918 DR_Gelbe_Warnlampe 0 "Warnlampe aus" 1 "Warnlampe ein (Aufprüfen)" 2 "Warnlampe an (Warnung)" 3 "reserviert" ;
VAL_ 686 DC_IstSpannung_HV 4094 "Init" 4095 "Fehler" ;
VAL_ 686 DC_IstStrom_NV 1022 "Init" 1023 "Fehler" ;
VAL_ 686 DC_IstSpannung_NV 254 "Init" 255 "Fehler" ;
VAL_ 1012 DC_ReserveStrom_NV 1022 "Init" 1023 "Fehler" ;
VAL_ 1012 DC_Verbrauch_Ueberlauf 0 "kein_Ueberlauf" 1 "Ueberlauf" ;
VAL_ 1012 DC_Verlustleistung 62 "Init" 63 "Fehler" ;
VAL_ 1012 DC_HYB_Auslastungsgrad 254 "Init" 255 "Fehler" ;
VAL_ 247 DC_Vorladung_Status 0 "nicht_abgeschlossen" 1 "abgeschlossen" ;
VAL_ 247 DC_Fehler_extern 0 "kein_Fehler" 1 "Fehler" ;
VAL_ 247 DC_Fehler_intern 0 "kein_Fehler" 1 "interner_Fehler_erkannt" ;
VAL_ 247 DC_Status_Spgfreiheit 0 "Init" 1 "HV_Komponente_spannungsfrei" 2 "HV_Komp_nicht_spannungsfrei" 3 "Fehler_nicht_spannungsfrei" ;
VAL_ 247 DC_Status_EoHVL 0 "Init" 1 "Keine_offene_HV_Leitung_erkannt" 2 "offene_HV_Leitung_erkannt" 3 "Fehler" ;
VAL_ 247 DC_IstModus_02 0 "Standby" 1 "HV_On_Vorladen" 2 "Tiefsetzen" 3 "Hochsetzen" 4 "Pruefimpuls_12V" 5 "Fehler" 7 "Initialisierung" ;
VAL_ 247 DC_IstStrom_HV 1022 "Init" 1023 "Fehler" ;
VAL_ 247 DC_IstLeistung_HV 1022 "Init" 1023 "Fehler" ;
VAL_ 1714 DGN_Verlernzaehler 255 "ungültiger Zählerstand oder kein gültiger Fahrzyklus" ;
VAL_ 1714 KBI_Kilometerstand 1048574 "Init" 1048575 "Fehler" ;
VAL_ 1714 UH_Monat 0 "Init" 14 "Relatives_Datum" 15 "Fehler" ;
VAL_ 1714 UH_Tag 0 "Init" ;
VAL_ 1714 Vehicle_Driving_Cycle 0 "kein_Driving_Cycle_erkannt" 1 "Driving_Cycle_erkannt" ;
VAL_ 1714 Kombi_02_alt 0 "aktuell" 1 "veraltet" ;
VAL_ 1714 Uhrzeit_01_alt 0 "aktuell" 1 "veraltet" ;
VAL_ 1520 DI_KL_58xd 254 "Init" 255 "Fehler" ;
VAL_ 1520 DI_KL_58xs 126 "Init" 127 "Fehler" ;
VAL_ 1520 DI_KL_58xt 126 "Init" 127 "Fehler" ;
VAL_ 1520 BCM1_Stellgroesse_Kl_58s 125 "Nicht_verbaut" 126 "Init" 127 "Fehler" ;
VAL_ 496 EA_Texte 0 "keine_Anzeige" 1 "Nothalteassistent_fehlende_Fahreraktivitaet" 2 "Nothalteassistent_aktiv_Fahrzeugfuehrung_uebernehmen" 3 "Nothalteassistent_automatischer_Nothalt_wird_durchgefuehrt" 4 "Nothalteassistent_automatischer_Nothalt_durchgefuehrt" 5 "Nothalteassistent_Verbindung_zum_Notruf_wird_aufgebaut" 6 "Nothalteassistent_deaktiviert" 7 "Nothalteassistent_Eingriff_abgebrochen" 8 "Nothalteassistent_fehlende_Fahreraktivitaet_2" 9 "Sekundenschlaf_erkannt" 10 "LaneAssist_Lenkung_uebernehmen" 11 "ACA_Fahrzeugfuehrung_uebernehmen" 12 "EA_Fahr_Standstreifenwechsel" 14 "Nothalteassistent_nicht_verfuegbar_reversibel" 15 "Nothalteassistent_Stoerung_irreversibel" ;
VAL_ 496 ACF_Lampe_Hands_Off 0 "keine_Anzeige" 1 "Hands_Off_erkannt" ;
VAL_ 496 EA_Fahrzeughupe_Anf 0 "keine_Anforderung" 1 "Anforderung_Fahrzeughupe" ;
VAL_ 496 EA_eCall_Anf 0 "Keine_Anforderung" 1 "Ausloesen_eCall" ;
VAL_ 496 EA_Infotainment_Anf 0 "Init" 1 "Keine_Absenkung" 2 "Absenkung" 3 "Mute" ;
VAL_ 496 EA_Tueren_Anf 0 "Keine_Anforderung" 1 "Tueren_entriegeln" ;
VAL_ 496 EA_Innenraumlicht_Anf 0 "Innenraumbeleuchtung_ausschalten" 1 "Innenraumbeleuchtung_einschalten" ;
VAL_ 496 zFAS_Warnblinken 0 "Aus" 1 "Statisch" 2 "Taster" 3 "Statisch_ohne_WBT" ;
VAL_ 496 STP_Primaeranz 0 "keine_Anzeige" 1 "Verfuegbar" 2 "Aktiv" 3 "Uebernahme" 4 "Aktiv_Warnung" 5 "Nicht_Verfuegbar" ;
VAL_ 496 EA_Bremslichtblinken 0 "kein_Blinken" 1 "Anforderung_Bremslichtblinken" ;
VAL_ 496 EA_Blinken 0 "Kein_Blinken" 1 "Wechselblinken_links" 2 "Wechselblinken_rechts" 3 "Warnblinken" 4 "Warnblinken_Taster" 5 "Richtungsblinken_links" 6 "Richtungsblinken_rechts" ;
VAL_ 496 EA_Status_HMI 0 "Keine_Anzeige" 1 "Aktiv_quer_laengs" 2 "Aktiv_laengs" ;
VAL_ 496 EA_Warnlevel 0 "keine_Gefaehrdung" 63 "max_Gefaehrdung" ;
VAL_ 1603 KBI_Einheit_Datum 0 "Tag/Monat/Jahr" 1 "Monat/Tag/Jahr" 2 "Jahr/Monat/Tag" 3 "reserviert" ;
VAL_ 1603 KBI_Einheit_Druck 0 "Druckangabe in bar" 1 "Druckangabe in psi" 2 "Druckangabe in kPa" 3 "tbd." ;
VAL_ 1603 KBI_Einheit_Streckenanz 0 "Kilometer" 1 "Meilen" ;
VAL_ 1603 KBI_MFA_v_Einheit_02 0 "kmh" 1 "mph" ;
VAL_ 1603 KBI_Einheit_Temp 0 "Grad Celsius °C" 1 "Grad Fahrenheit °F" ;
VAL_ 1603 KBI_Einheit_Uhrzeit 0 "24h" 1 " 12h AM/PM" ;
VAL_ 1603 KBI_Einheit_Verbrauch 0 "mpg UK" 1 "mpg USA" 2 "Liter/100km" 3 "km/Liter" ;
VAL_ 1603 KBI_Einheit_Volumen 0 "Liter" 1 "Gallonen UK" 2 "Gallonen USA" 3 "reserviert" ;
VAL_ 1603 KBI_Einheit_Verbrauch_elektr 0 "kWh_pro_100km" 1 "km_pro_kWh" 2 "kWh_pro_100mls" 3 "mls_pro_kWh" 4 "MPGe" ;
VAL_ 1603 KBI_Einheit_Tacho 0 "km/h" 1 "mph" ;
VAL_ 1603 KBI_Einheit_Verbrauch_Gas 0 "kg_per_100km" 1 "km_per_kg" 2 "m3_per_100km" 3 "km_per_m3" 4 "miles_per_lbs" 5 "miles_per_yard3" 6 "miles_per_kg" 7 "miles_per_m3" 8 "miles_per_gallon_equivalent_US" ;
VAL_ 1603 KBI_Einheit_Masse 0 "kg" 1 "lbs" 2 "reserviert" ;
VAL_ 1622 ELV_Anf_Klemme_S 0 "Aus" 1 "Ein" ;
VAL_ 1622 ELV_Anf_Klemme_15 0 "Aus" 1 "Ein" ;
VAL_ 1622 ELV_Anf_Klemme_50 0 "Aus" 1 "Ein" ;
VAL_ 1622 ELV_01_Sendestatus 0 "ELV_sendet_mit_1000ms" 1 "ELV_sendet_mit_50ms" ;
VAL_ 1622 ELV_Verriegelt 0 "nicht_verriegelt" 1 "verriegelt" ;
VAL_ 1622 ELV_Entriegelt 0 "ELV_nicht_entriegelt" 1 "ELV_entriegelt" ;
VAL_ 1622 ELV_ZAT_betaetigt 0 "nicht_betaetigt" 1 "betaetigt" ;
VAL_ 1622 ELV_Lebenszustand 0 "Lebenszustand_0" 1 "Lebenszustand_4" ;
VAL_ 1622 ELV_Anlernmodus 0 "Normalbetrieb" 1 "Anlernmodus" ;
VAL_ 1622 KST_aut_Abschaltung_Zuendung 0 "Zuendung_wird_bei_Verl_nicht_deaktiviert" 1 "Zuendung_wird_bei_Verl_deaktiviert" ;
VAL_ 1622 ELV_Klemmenfreigabe 0 "keine_Freigabe" 1 "Freigabe" ;
VAL_ 1622 ELV_Abbruch_Anf_Klemmenfreigabe 0 "kein_Abbruch" 1 "Abbruch" ;
VAL_ 1622 ELV_LED_Rot 0 "Aus" 1 "Ein" ;
VAL_ 1622 ELV_LED_Gelb 0 "Aus" 1 "Ein" ;
VAL_ 1622 ELV_Txt_Panikabschaltung 0 "Aus" 1 "Ein" ;
VAL_ 1622 ELV_Txt_Lkg_Bewegen 0 "Aus" 1 "Ein" ;
VAL_ 1622 ELV_Txt_Werkstatt 0 "Aus" 1 "Ein" ;
VAL_ 1622 ELV_Txt_Defekt 0 "Aus" 1 "Ein" ;
VAL_ 1622 ELV_Txt_P_Gang 0 "Aus" 1 "Ein" ;
VAL_ 1622 ELV_Txt_PN_Gang 0 "Aus" 1 "Ein" ;
VAL_ 1622 ELV_Txt_Kupplung 0 "Aus" 1 "Ein" ;
VAL_ 1622 ELV_Txt_Bremse 0 "Aus" 1 "Ein" ;
VAL_ 1622 ELV_P_verriegelt 0 "nicht_verriegelt" 1 "verriegelt" ;
VAL_ 1622 KST_Txt_Komfortabschaltung 0 "inaktiv" 1 "aktiv" ;
VAL_ 1622 KST_Anf_ZV_Verriegelung 0 "inaktiv" 1 "aktiv" ;
VAL_ 26 ELV_WFS_Anfrage_Typ 0 "Init" ;
VAL_ 26 ELV_WFS_Anfrage_CRC 0 "Init" ;
VAL_ 26 ELV_WFS_Anfrage_Status 0 "Init" ;
VAL_ 184 EM1_Freigabe_Info_WFS 0 "ungueltig" 1 "gueltig" ;
VAL_ 184 EM1_Sperr_Info_WFS 0 "nicht_gesperrt" 1 "gesperrt" ;
VAL_ 184 EM1_AR_aktiv 0 "Init" 1 "Ruckeldaempfer_aktiv" ;
VAL_ 184 EM1_Eta_Sys 510 "Init" 511 "Fehler" ;
VAL_ 184 EM1_IstStrom 2046 "Init" 2047 "Fehler" ;
VAL_ 184 EM1_Fehler_ElAntriebFreilauf_Anf 0 "Init" 1 "Fehler_EM_im_Freilauf" ;
VAL_ 184 EM1_Abregelung_Temperatur 0 "Init" 1 "Abregelung_Temperatur" ;
VAL_ 184 EM1_AnlernenElMotor_Anf 0 "kein_Diagnose_Request" 1 "Diagnose_Request" ;
VAL_ 184 EM1_Moment_HVVerbraucher 1023 "Init" ;
VAL_ 184 LE_Kuehlmittel_Sensor 0 "OK" 1 "Kuehlmittel_unter_min" ;
VAL_ 184 EM1_Freigabe_Verfallsinfo_WFS 0 "Aus" 1 "Ein" ;
VAL_ 184 EM1_Parken_WFS_Status 0 "Limitierung_Inaktiv" 1 "Limitierung_Aktiv" 2 "Abbruch" ;
VAL_ 184 EM1_HV_betriebsbereit 0 "Init" 1 "Ready_HV" ;
VAL_ 2589283970 DIST_DKmtg_Auth 0 "Init" 0 "Fehler" ;
VAL_ 2331595989 DIST_DKmtg 0 "Init" 0 "Fehler" ;
VAL_ 2589283751 KBI_Kilometerstand_Extended 16777214 "Init" 16777215 "Fehler" ;
VAL_ 503 EPB_Texte_02 0 "keine_Anzeige" 1 "Neigungswinkel_zu_gross" 2 "Parkbremse_von_Hand_oeffnen" 3 "HU_Modus_oder_EPB_in_Diagnose" 4 "Bremspedal_betaetigen" 5 "EPB_durch_Fahrstufe_loesen" 6 "tbd" 7 "Stoerung_Anfahrassistent" 8 "Motor_starten" 9 "Feststellbremse_nicht_automatisch_geschlossen" 10 "Parkbremse_loesen_nicht_moeglich_Ladekabel_gesteckt" 11 "Notbremsung_ueber_EPB_Taster" 12 "Parkbremse_angezogen" 13 "Parkbremse_loesen_nicht_moeglich_ParkPilot_aktiv" ;
VAL_ 503 EPB_Fehlermeldungen_02 0 "keine_Anzeige" 1 "Systemstoerung_Kl15an" 2 "Systemstoerung_Kl15aus" 3 "Parkbremse_betaetigen" 4 "Systemstoerung_Hanghaltefaehigkeit" 5 "Funktionseinschraenkung_Kl15an" 6 "Funktionseinschraenkung_Kl15aus" 7 "HU_Modus_aktiv" 8 "Transportmodus" 9 "Produktionsmodus" 10 "FktEinschr_Taster_defekt" 11 "Funktionseinschraenkung_Hanghalt" ;
VAL_ 503 EPB_Funktionslampe_02 0 "Aus" 1 "Ein" ;
VAL_ 503 EPB_Autoholdlampe_02 0 "Lampe aus (Autohold inaktiv)" 1 "Lampe ein (Autohold aktiv)" ;
VAL_ 503 EPB_Autohold_Standbyanzeige 0 "Lampe aus" 1 "Lampe ein" ;
VAL_ 503 EPB_Parkanzeige 0 "aus" 1 "an" 2 "blinken" 3 "reserviert" ;
VAL_ 258 ESP_QBit_Gierrate 0 "gueltiger_Wert" 1 "Ersatz_Init_oder_Fehlerwert" ;
VAL_ 258 ESP_QBit_Laengsbeschl 0 "gueltiger_Wert" 1 "Ersatz_Init_oder_Fehlerwert" ;
VAL_ 258 ESP_QBit_Querb 0 "gueltiger_Wert" 1 "Ersatz_Init_oder_Fehlerwert" ;
VAL_ 258 ESP_Querbeschleunigung 255 "Fehler" ;
VAL_ 258 ESP_Laengsbeschl 1022 "Signal_nicht_vorhanden" 1023 "Fehler" ;
VAL_ 258 ESC_Motorstartverzoegerung 0 "Startfreigabe" 1 "Anforderung_Startverzoegerung" ;
VAL_ 258 ESC_SeitenwindAssistent_Eingriff 0 "Kein_SWA_Eingriff_und_Init" 1 "SWA_Eingriff_aktiv" ;
VAL_ 258 ESP_Anschleppstart_Freigabe 0 "kein_Schleppstart_oder_NotSchleppstart_erlaubt" 1 "NotSchleppstart_erlaubt" 2 "Schleppstart_und_NotSchleppStart_erlaubt" ;
VAL_ 258 ESC_Unterdruckmangel_erkannt 0 "kein_Unterdruckmangel_erkannt" 1 "Unterdruckmangel_erkannt" ;
VAL_ 258 ESP_Gierrate 16383 "Fehler" ;
VAL_ 258 ESP_VZ_Gierrate 0 "positiv" 1 "negativ" ;
VAL_ 258 ESP_Notbremsanzeige 0 "keine_Notbremsung_erkannt" 1 "Notbremsung_erkannt" ;
VAL_ 258 ESP_SpannungsAnf 0 "keine_Anforderung" 1 "Anforderung_Spannungswert_1" ;
VAL_ 258 ESP_PLA_Abbruch 0 "Init" 1 "Geschwindigkeitsueberschreitung" 2 "Falscher_PLA_Status" 3 "Deaktivierung_durch_Abbruch_Lenkung" 4 "PLA_Bremsanforderung_nach_Stillstand" 5 "Abbruch_durch_Kl15_aus" 6 "Abbruch_durch_FT_offen" ;
VAL_ 258 ESP_Status_ESP_PLA 0 "ESP_PLA_deaktiv" 1 "ESP_PLA_Init" 2 "ESP_PLA_Fehler" 4 "ESP_PLA_aktivierbar" 6 "ESP_PLA_Bremse_aktiv" 8 "ESP_PLA_funktionsbereit" 9 "ESP_PLA_Neustart" 10 "ESP_PLA_Abbruch" ;
VAL_ 258 ESP_QBit_Bremsdruck 0 "gueltiger_Wert" 1 "Ersatz_Init_oder_Fehlerwert" ;
VAL_ 258 ESP_QBit_Fahrer_bremst 0 "gueltiger_Wert" 1 "Ersatz_Init_oder_Fehlerwert" ;
VAL_ 258 ESP_Schwelle_Unterdruck 0 "kein_Signal" 1 "Unterdruck_kleiner_gleich_450_mbar" 2 "Unterdruck_groesser_450_mbar" 3 "Fehler_Unterdrucksensor" ;
VAL_ 258 ESP_Bremsdruck 1023 "Fehler" ;
VAL_ 258 ESP_Fahrer_bremst 0 "Bremsdruckschwelle_nicht_ueberschritten" 1 "Bremsdruckschwelle_ueberschritten" ;
VAL_ 258 ESP_Verz_TSK_aktiv 0 "TSK_Verzoegerung_inaktiv" 1 "TSK_Verzoegerung_aktiv" ;
VAL_ 258 ESP_Lenkeingriff_ADS 0 "kein_Lenkeingriff" 1 "stabilisierender_Lenkeingriff" ;
VAL_ 258 ESP_Konsistenz_TSK 0 "Botschaft_fuer_Verzoegerungsanforderung_konsistent" 1 "Botschaft_fuer_Verzoegerungsanforderung_nicht_konsistent" ;
VAL_ 258 ESP_Bremsruck_AWV2 0 "kein_Bremsruck_ausgefuehrt" 1 "Bremsruck_ausgefuehrt" ;
VAL_ 258 ESP_Konsistenz_AWV2 0 "Botschaft_fuer_AWV2_konsistent" 1 "Botschaft_fuer_AWV2_nicht_konsistent" ;
VAL_ 258 ECD_Fehler 0 "ECD_iO" 1 "ECD_Fehler" ;
VAL_ 258 ECD_nicht_verfuegbar 0 "ECD_Funktion_verfuegbar" 1 "ECD_Funktion_nicht_verfuegbar" ;
VAL_ 258 ESP_Status_Bremsentemp 0 "Bremse_nicht_ueberhitzt" 1 "Bremse_ueberhitzt" ;
VAL_ 258 ESP_Autohold_Standby 0 "Autohold_nicht_im_Standby" 1 "Autohold_im_Standby" ;
VAL_ 258 ESP_HDC_Standby 0 "HDC_Funktion_nicht_im_Standby" 1 "HDC_Funktion_im_Standby" ;
VAL_ 258 ESP_HBA_aktiv 0 "HBA_nicht_aktiv" 1 "HBA_aktiv" ;
VAL_ 258 ESP_Prefill_ausgeloest 0 "nicht_ausgeloest" 1 "Prefill_ausgeloest" ;
VAL_ 258 ESP_Rueckwaertsfahrt_erkannt 0 "keine_Rueckwaetsfahrt" 1 "Rueckwaertsfahrt_sicher_erkannt" ;
VAL_ 258 ESP_Status_Anfahrhilfe 0 "Aus" 1 "Ein" ;
VAL_ 258 ESP_HDC_aktiv 0 "inaktiv" 1 "aktiv" ;
VAL_ 258 ESP_StartStopp_Info 0 "Motorlauf_nicht_notwendig_(Stoppfreigabe)" 1 "Motoranlauf_nicht_zwingend_notwendig_(Stoppverbot,keine_Startanforderung)" 2 "Motoranlauf_zwingend_notwendig_(Startanforderung)" 3 "Systemfehler" ;
VAL_ 258 ESP_Eingr_HL 0 "kein_Eingriff" 1 "ESP_Eingriff_HL" ;
VAL_ 258 ESP_Eingr_HR 0 "kein_Eingriff" 1 "ESP_Eingriff_HR" ;
VAL_ 258 ESP_Eingr_VL 0 "kein_Eingriff" 1 "ESP_Eingriff_VL" ;
VAL_ 258 ESP_Eingr_VR 0 "kein_Eingriff" 1 "ESP_Eingriff_VR" ;
VAL_ 258 ESP_BKV_Unterdruck 0 "nicht_verbaut_oder_nicht_kodiert" 254 "Init" 255 "Fehler" ;
VAL_ 258 ESP_Autohold_aktiv 0 "Autohold_inaktiv" 1 "Autohold_aktiv" ;
VAL_ 258 ESP_FStatus_Anfahrhilfe 0 "kein_Fehler" 1 "Fehler" ;
VAL_ 258 ESP_Verz_EPB_aktiv 0 "nicht_aktiviert" 1 "aktiviert" ;
VAL_ 258 ECD_Bremslicht 0 "Aus" 1 "Ein" ;
VAL_ 258 ESP_Verzoeg_EPB_verf 0 "nicht_verfuegbar" 1 "System_verfuegbar" ;
VAL_ 258 ESP_Status_Bremsdruck 0 "Bremse_drucklos" 1 "mit_Bremsdruck" ;
VAL_ 258 ESP_Anforderung_EPB 0 "keine_Anforderung" 1 "Anforderung_Oeffnen" 2 "Anforderung_Schliessen" 3 "reserviert" ;
VAL_ 258 ESC_Fahrerradbremswunschmoment 4094 "Init" 4095 "Fehler" ;
VAL_ 258 ESP_ANB_CM_Rueckk_Umsetz 0 "keine_Ausfuehrung" 1 "Ausfuehrung" ;
VAL_ 258 ESP_Konsistenz_ACC_Botschaft 0 "Botschaft_fuer_ACC_konsistent" 1 "Botschaft_fuer_ACC_nicht_konsistent" ;
VAL_ 258 ESP_Stillstandsphase_erschoepft 0 "sicheres_Halten_moeglich" 1 "kein_sicheres_Halten_moeglich" ;
VAL_ 258 ESP_ZT_Rueckk_Umsetz 0 "keine_Ausfuehrung" 1 "Ausfuehrung" ;
VAL_ 258 ESP_Tuerkontakt_Fahrertuer 0 "Schalter_geschlossen" 1 "Schalter_offen" ;
VAL_ 258 ESP_Abrutschen_Stillstand 0 "kein_Abrutschen_erkannt" 1 "Abrutschen_erkannt" ;
VAL_ 258 ESP_Fahrer_tritt_ZBR_Schw 0 "Fahrer_uebertritt_ZBR_Schwelle_nicht" 1 "Fahrer_uebertritt_ZBR_Schwelle" ;
VAL_ 258 ESP_Systemstatus_03 0 "ESC_passiv_getastet" 1 "ESC_Schwellen_geaendert" 2 "ESC_aktiviert" 3 "Fehler" ;
VAL_ 258 ASR_Systemstatus 0 "ASR_passiv_getastet" 1 "ASR_Schwellen_geaendert" 2 "ASR_aktiviert" 3 "ASR_Stoerung" ;
VAL_ 258 ESP_QBit_v_ref 0 "gueltiger_Wert" 1 "Ersatz_Init_oder_Fehlerwert" ;
VAL_ 258 ESP_v_ref_Fahrtrichtung 0 "Fahrtrichtung_nicht_definiert" 1 "Vorwaerts" 2 "Rueckwaerts" 3 "Stillstand" ;
VAL_ 258 ESC_Bremsdruckgradient 251 "groesser_2500_bar_per_sec" 254 "Init" 255 "Fehler" ;
VAL_ 258 ESP_v_ref 4093 "Unterspannung" 4094 "Init" 4095 "Fehler" ;
VAL_ 258 ESP_HBA_Empfindlichkeit 0 "Init" 1 "unempfindlich" 2 "normal" 3 "empfindlich" 4 "sehr_empfindlich" 5 "reserviert" 6 "reserviert" 7 "Fehler" ;
VAL_ 258 ESC_Hydr_Fkt_aktiv 0 "keine_Aktivitaet" 1 "ESC_Druckaufbau_HBx_HFC_aktiv" 2 "Warnrucklevel_Summand_1" 3 "Warnrucklevel_Summand_3" ;
VAL_ 258 ESC_QBit_Fahrerbremswunsch 0 "gueltiger_Wert" 1 "Ersatz_Init_oder_Fehlerwert" ;
VAL_ 258 ESC_Fahrerbremswunsch 1023 "Fehler" ;
VAL_ 258 ESCGeneratorSollMoment 4094 "Init" 4095 "Fehler" ;
VAL_ 258 ESC_Raddruck_max 254 "Init" 255 "Fehler" ;
VAL_ 258 EPB_QBit_Pedalweg_Kuppl 0 "gültiger Wert" 1 "Ersatz-, Init- oder Fehlerwert" ;
VAL_ 258 EPB_Freig_Verzoeg_Anf 0 "nicht freigegeben" 1 "freigegeben" ;
VAL_ 258 EPB_Pedalweg_Kuppl 0 "Init" 255 "Fehler" ;
VAL_ 258 EPB_DAA_Randbed_erf 0 "Randbed_nicht_erfuellt" 1 "Randbed_erfuellt" ;
VAL_ 258 EPB_Fehlerstatus_02 0 "kein_Fehler" 1 "Fehler_ausserhalb_apply_release" 2 "Fehler_einseitig_apply_release" 3 "Fehler_beidseitig_apply_release" ;
VAL_ 258 EPB_Schalterposition 0 "keine Fahreranforderung" 1 "Fahreranforderung Öffnen" 2 "Fahreranforderung Schließen" 3 "Fehler" ;
VAL_ 258 EPB_QBit_Schalterpos 0 "gültiger Wert (volle Funktion)" 1 " Ersatz-, Init- oder Fehlerwert (Schalter ausser Funktion)" ;
VAL_ 258 EPB_Spannkraft 30 "Init" 31 "Fehler" ;
VAL_ 258 EPB_Status_02 0 "offen" 1 "geschlossen_Parken" 2 "teilgespannt_Halten" 3 "im_Lauf_oeffnen" 4 "im_Lauf_schliessen" 5 "tbd" 6 "Init" 7 "unbekannt" ;
VAL_ 258 EPB_Status 0 "offen" 1 "Bremse_geschl_(Spannkraft_voll/reduziert)" 2 "Aktuator_im_Lauf" 3 "Fehler_oder_unbekannt" ;
VAL_ 258 ESP_Status_Bremsentemp_02 0 "nicht_erhoeht" 1 "Schwelle_1" 2 "Schwelle_2" ;
VAL_ 885 SSO_EdgeCount_Sum 0 "init" 0 "Fehler" ;
VAL_ 2589283575 ESI_StOilChg 0 "keine_Anzeige" 1 "Wert_nicht_berechnet" 2 "Wert_berechnet" 3 "Oelwechsel_faellig" ;
VAL_ 2589283575 ESI_TiRemOilChg 1022 "InitWert" 1023 "Fehler" ;
VAL_ 2589283575 ESI_DRemOilChg 65534 "InitWert" 65535 "Fehler" ;
VAL_ 278 ESP_QBit_Wegimpuls_VL 0 "gueltiger_Wert" 1 "Ersatz_Init_oder_Fehlerwert" ;
VAL_ 278 ESP_QBit_Wegimpuls_VR 0 "gueltiger_Wert" 1 "Ersatz_Init_oder_Fehlerwert" ;
VAL_ 278 ESP_QBit_Wegimpuls_HL 0 "gueltiger_Wert" 1 "Ersatz_Init_oder_Fehlerwert" ;
VAL_ 278 ESP_QBit_Wegimpuls_HR 0 "gueltiger_Wert" 1 "Ersatz_Init_oder_Fehlerwert" ;
VAL_ 278 ESP_Wegimpuls_VL 1021 "Init" 1022 "Unterspannung" 1023 "Fehler" ;
VAL_ 278 ESP_Wegimpuls_VR 1021 "Init" 1022 "Unterspannung" 1023 "Fehler" ;
VAL_ 278 ESP_Wegimpuls_HL 1021 "Init" 1022 "Unterspannung" 1023 "Fehler" ;
VAL_ 278 ESP_Wegimpuls_HR 1021 "Init" 1022 "Unterspannung" 1023 "Fehler" ;
VAL_ 278 ESP_VL_Fahrtrichtung 0 "Vorwaerts" 1 "Rueckwaerts" 2 "Init" 3 "ungueltig_oder_nicht_verbaut" ;
VAL_ 278 ESP_VR_Fahrtrichtung 0 "Vorwaerts" 1 "Rueckwaerts" 2 "Init" 3 "ungueltig_oder_nicht_verbaut" ;
VAL_ 278 ESP_HL_Fahrtrichtung 0 "Vorwaerts" 1 "Rueckwaerts" 2 "Init" 3 "ungueltig_oder_nicht_verbaut" ;
VAL_ 278 ESP_HR_Fahrtrichtung 0 "Vorwaerts" 1 "Rueckwaerts" 2 "Init" 3 "ungueltig_oder_nicht_verbaut" ;
VAL_ 178 ESP_HL_Radgeschw_02 65533 "Unterspannung" 65534 "Init" 65535 "Fehler" ;
VAL_ 178 ESP_HR_Radgeschw_02 65533 "Unterspannung" 65534 "Init" 65535 "Fehler" ;
VAL_ 178 ESP_VL_Radgeschw_02 65533 "Unterspannung" 65534 "Init" 65535 "Fehler" ;
VAL_ 178 ESP_VR_Radgeschw_02 65533 "Unterspannung" 65534 "Init" 65535 "Fehler" ;
VAL_ 1629 BR_Systemart 0 "ABS" 1 "ABS_ASR" 2 "ESP" 3 "ESP_mit_integrierter_EPB" ;
VAL_ 1629 ESP_SpannungsAnf_02 0 "keine_Anforderung" 1 "Anforderung_Stufe1" 2 "Anforderung_Stufe2" 3 "Anforderung_Stufe3" ;
VAL_ 1629 ESP_Charisma_FahrPr 0 "keine_Funktion" 1 "Programm_1" 2 "Programm_2" 3 "Programm_3" 4 "Programm_4" 5 "Programm_5" 6 "Programm_6" 7 "Programm_7" 8 "Programm_8" 9 "Programm_9" 10 "Programm_10" 11 "Programm_11" 12 "Programm_12" 13 "Programm_13" 14 "Programm_14" 15 "Programm_15" ;
VAL_ 1629 ESP_Charisma_Status 0 "Init" 1 "verfuegbar" 2 "nicht_verfuegbar" 3 "asynchron_durch_Fahrerwunsch" ;
VAL_ 1629 ESP_Wiederstart_Anz_01 0 "keine_Anzeige" 1 "Rueckwaertsrollen" ;
VAL_ 1629 ESP_Wiederstart_Anz_02 0 "keine_Anzeige" 1 "Autohold_Rutschen" ;
VAL_ 1629 ESP_Wiederstart_Anz_03 0 "keine_Anzeige" 1 "Offroad_HDC" ;
VAL_ 1629 ESP_Wiederstart_Anz_04 0 "keine_Anzeige" 1 "ESC_Off" ;
VAL_ 1629 ESP_Stoppverbot_Anz_01 0 "keine_Anzeige" 1 "Notbremsung_aktiv" ;
VAL_ 1629 ESP_Stoppverbot_Anz_02 0 "keine_Anzeige" 1 "Autohold_AVH_Rutschen" ;
VAL_ 1629 ESP_Stoppverbot_Anz_03 0 "keine_Anzeige" 1 "Rueckwaertsrollen" ;
VAL_ 1629 ESP_Stoppverbot_Anz_04 0 "keine_Anzeige" 1 "ESP_Pumpenlauf" ;
VAL_ 1629 ESP_Stoppverbot_Anz_05 0 "keine_Anzeige" 1 "ESP_OFF" ;
VAL_ 1629 ESP_Stoppverbot_Anz_06 0 "keine_Anzeige" 1 "Offroad_HDC" ;
VAL_ 1629 ESP_Stoppverbot_Anz_07 0 "keine_Anzeige" 1 "ESP_Haltefunktion_nicht_verfuegbar" ;
VAL_ 1629 ESP_Stoppverbot_Anz_Std 0 "keine_Anzeige" 1 "Standard_Stoppvetogrund" ;
VAL_ 1629 ESP_Dachrelingsensor 0 "Sensor_nicht_verbaut" 1 "Quertraeger_montiert" 2 "Quertraeger_nicht_montiert" 3 "Fehler" ;
VAL_ 1629 ESP_Stoppverbot_Anz_08 0 "keine_Anzeige" 1 "Neigungsbegrenzung" ;
VAL_ 1629 HDC_Charisma_FahrPr 0 "keine_Funktion" 1 "Programm_1" 2 "Programm_2" 3 "Programm_3" 4 "Programm_4" 5 "Programm_5" 6 "Programm_6" 7 "Programm_7" 8 "Programm_8" 9 "Programm_9" 10 "Programm_10" 11 "Programm_11" 12 "Programm_12" 13 "Programm_13" 14 "Programm_14" 15 "Programm_15" ;
VAL_ 1629 HDC_Charisma_Status 0 "Init" 1 "verfuegbar" 2 "nicht_verfuegbar" 3 "asynchron_durch_Fahrerwunsch" ;
VAL_ 1629 BR_QBit_Reifenumfang 0 "gueltiger_Wert" 1 "Ersatz_Init_oder_Fehlerwert" ;
VAL_ 253 BR_Eingriffsmoment 1022 "Init" 1023 "Fehler" ;
VAL_ 253 ESP_PLA_Bremseingriff 0 "inaktiv" 1 "aktiv" ;
VAL_ 253 ESP_Diagnose 0 "ESP_nicht_in_Diagnose" 1 "ESP_in_Diagnose" ;
VAL_ 253 ESC_Reku_Freigabe 0 "keine_Freigabe_der_Rekuperation" 1 "Freigabe_der_Rekuperation" ;
VAL_ 253 ESC_v_Signal_Qualifier_High_Low 0 "Gueteschwelle_kleiner_1kmh" 1 "Gueteschwelle_kleiner_3kmh" 2 "Gueteschwelle_kleiner_5kmh" 3 "Gueteschwelle_kleiner_10kmh" 4 "Gueteschwelle_kleiner_20kmh" 5 "Gueteschwelle_groessergleich_20kmh" 6 "Init" 7 "Fehler" ;
VAL_ 253 ESP_Vorsteuerung 0 "keine_Vorsteuerung_aktiv" 1 "Vorsteuerung_aktiv" ;
VAL_ 253 ESP_AWV3_Brems_aktiv 0 "inaktiv" 1 "aktiv" ;
VAL_ 253 OBD_Schlechtweg 0 "kein_Schlechtweg_erkannt" 1 "Schlechtweg_erkannt" ;
VAL_ 253 OBD_QBit_Schlechtweg 0 "gueltiger_Wert" 1 "Ersatz_Init_oder_Fehlerwert" ;
VAL_ 253 ESP_v_Signal 65533 "Unterspannung" 65534 "Init" 65535 "Fehler" ;
VAL_ 253 ASR_Tastung_passiv 0 "ASR_aktiviert" 1 "ASR_passiv_getastet_oder_Schwellen_geaendert" ;
VAL_ 253 ESP_Tastung_passiv 0 "ESP_aktiviert" 1 "ESP_passiv_getastet_oder_Schwellen_geaendert" ;
VAL_ 253 ESP_Systemstatus 0 "iO" 1 "Fehler" ;
VAL_ 253 ASR_Schalteingriff 0 "keine_Anforderung" 1 "ASR_Schaltkennfeld" 2 "Rueckschaltung" 3 "Schaltverbot" ;
VAL_ 253 ESP_Haltebestaetigung 0 "kein_sicheres_Halten" 1 "sicheres_Halten" ;
VAL_ 253 ESP_MKB_Abbruch_Geschw 0 "MKB_nicht_beendet_wg_v_Schwelle" 1 "MKB_beendet_wg_v_Schwelle" ;
VAL_ 253 ESP_QBit_v_Signal 0 "gueltiger_Wert" 1 "Ersatz_Init_oder_Fehlerwert" ;
VAL_ 253 ABS_Bremsung 0 "keine_ABS_Regelung" 1 "ABS_Regelung_aktiv" ;
VAL_ 253 ASR_Anf 0 "keine_Anforderung" 1 "ASR_Anforderung" ;
VAL_ 253 MSR_Anf 0 "keine Anfoderung" 1 "MSR-Anforderung" ;
VAL_ 253 EBV_Eingriff 0 "kein_EBV_Eingriff" 1 "EBV_Eingriff" ;
VAL_ 253 EDS_Eingriff 0 "kein_EDS_Eingriff" 1 "EDS_Eingriff" ;
VAL_ 253 ESP_Eingriff 0 "kein_ESP_Eingriff" 1 "ESP_Eingriff_aktiv" ;
VAL_ 253 ESP_ASP 0 "inaktiv" 1 "aktiv" ;
VAL_ 253 ESP_Anhaltevorgang_ACC_aktiv 0 "inaktiv" 1 "aktiv" ;
VAL_ 795 ESP_Lampe 0 "Aus" 1 "Ein" ;
VAL_ 795 ABS_Lampe 0 "Aus" 1 "Ein" ;
VAL_ 795 BK_Lampe_02 0 "aus" 1 "Typ1_ein_statisch" 2 "Typ2_ein_statisch" 3 "Warnung" ;
VAL_ 795 TC_Lampe 0 "Aus" 1 "Ein" ;
VAL_ 795 ESP_m_Raddrehz 32765 "Unterspannung" 32766 "Init" 32767 "Fehler" ;
VAL_ 795 ESP_Textanzeigen_03 0 "kein_Text" 1 "ESP_Stoerung" 2 "ABS_Stoerung" 3 "ESP_ABS_Stoerung" 4 "Werkstatt_Bremse" 5 "ASR_Stoerung" 6 "ESP_switched_off" 7 "ASR_off" 8 "ESP_ASR_on" 10 "keine_Bremskraftverstaerkung" 11 "ASR_aktiviert" 12 "ABS_ASR_Stoerung" 15 "ESP_offroad" 17 "ESP_sport" 18 "ESP_Zwangsaktivierung" 19 "ESP_Taster_Info" 20 "TC_aktiv" 21 "reserviert_fuer_Verlwarn" 22 "TC_switched_off" 23 "Verlwarn_akt_Rollsicher_inakt" 24 "ESP_SuperSport" 25 "ESP_Offroad_nicht_verfuegbar" ;
VAL_ 795 ESP_Meldungen 0 "keine_Anzeige" 1 "Autohold_Hinweis_1" 2 "Stoerung_Autohold" 3 "Stoerung_Hillholder" 4 "Uebernehmen" 5 "Autohold_aus" 6 "Autohold_Hinweis_2" ;
VAL_ 795 ESP_Fehlerstatus_Wegimp 0 "Wegimpulse_iO" 1 "Fehler" ;
VAL_ 795 ESP_Wegimp_Ueberlauf 0 "Reset_und_kein_Ueberlauf" 1 "mindestens_1x_Ueberlauf" ;
VAL_ 795 ESP_QBit_Wegimp_VA 0 "gueltiger_Wert" 1 "Ersatz_Init_oder_Fehlerwert" ;
VAL_ 795 ESP_HDC_FktLampe 0 "Aus" 1 "Ein" ;
VAL_ 795 ESP_Off_Lampe 0 "Lampe_aus" 1 "Lampe_ein" ;
VAL_ 795 ESP_HDC_Regelgeschw 0 "nicht_verbaut" 125 "HDC_Standby" 126 "Init" 127 "Fehler" ;
VAL_ 795 ESP_BKV_Warnung 0 "keine_Anzeige" 1 "keine_Bremskraftverstaerkung" ;
VAL_ 2589283617 EDS_Charisma_FahrPr 0 "keine_Funktion" 1 "Programm_1" 2 "Programm_2" 3 "Programm_3" 4 "Programm_4" 5 "Programm_5" 6 "Programm_6" 7 "Programm_7" 8 "Programm_8" 9 "Programm_9" 10 "Programm_10" 11 "Programm_11" 12 "Programm_12" 13 "Programm_13" 14 "Programm_14" 15 "Programm_15" ;
VAL_ 2589283617 EDS_Charisma_Status 0 "Init" 1 "verfuegbar" 2 "nicht_verfuegbar" 3 "asynchron_durch_Fahrerwunsch" ;
VAL_ 2589283617 HHC_Charisma_Status 0 "Init" 1 "verfuegbar" 2 "nicht_verfuegbar" 3 "asynchron_durch_Fahrerwunsch" ;
VAL_ 2589283617 HHC_Charisma_FahrPr 0 "keine_Funktion" 1 "Programm_1" 2 "Programm_2" 3 "Programm_3" 4 "Programm_4" 5 "Programm_5" 6 "Programm_6" 7 "Programm_7" 8 "Programm_8" 9 "Programm_9" 10 "Programm_10" 11 "Programm_11" 12 "Programm_12" 13 "Programm_13" 14 "Programm_14" 15 "Programm_15" ;
VAL_ 2589283617 RLE_Anzeigen 0 "keine_Anzeige" 1 "Rad_lose_allgemein" 2 "Rad_VL_lose" 3 "Rad_VR_lose" 4 "Rad_HL_lose" 5 "Rad_HR_lose" 6 "RLE_Pruefphase" 7 "RLE_Systemstoerung" ;
VAL_ 2589283617 ESC_Lernfreigabe_Abrollumfang 0 "keine_Lernfreigabe" 1 "Lernfreigabe" ;
VAL_ 2589283617 ESC_Texte_eBKV_Betaetigung 0 "keine_Anzeige" 1 "Halten_ueber_Schaltwippen_aktiv" 2 "Beide_Schaltwippen_betaetigen" 3 "Abbr_Halten_ueber_Schaltwippen" 4 "Bremspedal_betaetigen" 5 "Fahrpedal_loesen_Bremse_treten" ;
VAL_ 2589283617 ESC_MBK_Meldungen 0 "kein_Text" 1 "MBK_Hinweis_aktiv" 2 "MBK_Eskalation1_aktiv" ;
VAL_ 2589283617 ESC_Anf_KV 0 "kein_Oeffnen" 1 "Oeffnen" ;
VAL_ 2589283617 ESC_FBA_Meldungen 0 "kein_Text" 1 "FBA_Warnung_aktiv_MT" 2 "FBA_Warnung_aktiv_AT" ;
VAL_ 2589283617 DBK_Fahrerwarnung 0 "kein_Anfordern" 1 "Warnung_Aufforderung_Anhalten" 2 "Warnung_Aufforderung_Werkstatt" 3 "nicht_belegt" ;
VAL_ 2589283617 ESP_Status_Bremsentemp_Anz 0 "Init" 1 "kalt" 2 "warm" 3 "heiss" 4 "ueberhitzt" 5 "nass" 7 "Fehler" ;
VAL_ 2589283617 ESP_Off_Anf_KBI 0 "keine_Anzeige" 1 "Anzeige_ESP_off_Popup" ;
VAL_ 2589283617 FBC_Fahrerwarnung 0 "kein_Anfordern" 1 "Warnung_Bremse_heiss" 2 "Warnung_Bremse_ueberhitzt" ;
VAL_ 707 FA_Warnung_Transportniveau 0 "keine_Anzeige" 1 "Warnung" ;
VAL_ 707 eAWS_Warnmeldung_Prio3 0 "keine_Anzeige" 1 "Hinweismeldung" ;
VAL_ 707 EFP_Anf_Kuehlklappenwarnung 0 "kein_Warnhinweis" 1 "Warnhinweis" ;
VAL_ 707 FDR_M_HL_02 252 "Darstellung_passiv" 253 "nicht_verbaut" 254 "Init" 255 "Fehler" ;
VAL_ 707 FDR_M_HR_02 252 "Darstellung_passiv" 253 "nicht_verbaut" 254 "Init" 255 "Fehler" ;
VAL_ 707 FDR_M_VL_02 252 "Darstellung_passiv" 253 "nicht_verbaut" 254 "Init" 255 "Fehler" ;
VAL_ 707 FDR_M_VR_02 252 "Darstellung_passiv" 253 "nicht_verbaut" 254 "Init" 255 "Fehler" ;
VAL_ 2589283684 GRA_FoD_Status 0 "Init" 1 "Funktion_inaktiv" 2 "Funktion_aktiv" ;
VAL_ 2589283684 FoD_Transmission_Info 0 "Initwert" 1 "start_transmission" 2 "finish_transmission" ;
VAL_ 2549875476 FoD_Kombi_Req_Data 0 "Init" ;
VAL_ 2550006548 FoD_Kombi_Resp_Data 0 "Init" ;
VAL_ 986 ESP_05_alt 0 "aktuell" 1 "veraltet" ;
VAL_ 986 EPB_01_alt 0 "aktuell" 1 "veraltet" ;
VAL_ 986 ESP_21_alt 0 "aktuell" 1 "veraltet" ;
VAL_ 986 LWI_01_alt 0 "aktuell" 1 "veraltet" ;
VAL_ 986 Parkhilfe_01_alt 0 "aktuell" 1 "veraltet" ;
VAL_ 986 Kamera_Status_alt 0 "aktuell" 1 "veraltet" ;
VAL_ 986 ESP_HDC_Standby 0 "HDC_Funktion_nicht_im_Standby" 1 "HDC_Funktion_im_Standby" ;
VAL_ 986 ECD_Bremslicht 0 "Aus" 1 "Ein" ;
VAL_ 986 EPB_Status 0 "offen" 1 "Bremse_geschl_(Spannkraft_voll/reduziert)" 2 "Aktuator_im_Lauf" 3 "Fehler_oder_unbekannt" ;
VAL_ 986 EPB_QBit_Pedalweg_Kuppl 0 "gültiger Wert" 1 "Ersatz-, Init- oder Fehlerwert" ;
VAL_ 986 ESP_QBit_v_Signal 0 "gueltiger_Wert" 1 "Ersatz_Init_oder_Fehlerwert" ;
VAL_ 986 ABS_Bremsung 0 "keine_ABS_Regelung" 1 "ABS_Regelung_aktiv" ;
VAL_ 986 ESP_Eingriff 0 "kein_ESP_Eingriff" 1 "ESP_Eingriff_aktiv" ;
VAL_ 986 Kamera_FSH_aktiv 0 "Kamera_Frontscheibenheizung_nicht_aktiviert" 1 "Kamera_Frontscheibenheizung_aktiviert" ;
VAL_ 986 EPB_Pedalweg_Kuppl 0 "Init" 255 "Fehler" ;
VAL_ 986 ESP_v_Signal 65533 "Unterspannung" 65534 "Init" 65535 "Fehler" ;
VAL_ 986 LWI_QBit_Lenkradwinkel 0 "gültiger Wert" 1 "ausserhalb der Spezifikation" ;
VAL_ 986 LWI_Sensorstatus 0 "iO" 1 "nicht kalibriert" ;
VAL_ 986 LWI_VZ_Lenkradwinkel 0 "positiv_links_von_der_Nullstellung" 1 "negativ" ;
VAL_ 986 LWI_Lenkradwinkel 8190 "Init" 8191 "Fehler" ;
VAL_ 986 PH_Anf_Audioabsenkung 0 "Keine_Audioabsenkung" 1 "Anforderung_Audioabsenkung" ;
VAL_ 986 PH_Systemzustand 0 "Anlage aus" 1 "Anlage durch einlegen R-Gang aktiviert" 2 "Anlage manuell durch Taster aktiviert" 3 "Anlage automatisch aktiviert" 4 "Anlage durch ARA aktiviert" 6 "Init - Initialisierungsphase nach Kl. 15 ein / Reset" 7 "Fehler-/gestört Zustand, System noch aktiv" ;
VAL_ 986 PH_Taster 0 "Taster_nicht_gedrueckt" 1 "Taster_gedrueckt" 2 "reserviert" 3 "Fehler" ;
VAL_ 986 ESP_MKB_Abbruch_Geschw 0 "MKB_nicht_beendet_wg_v_Schwelle" 1 "MKB_beendet_wg_v_Schwelle" ;
VAL_ 986 PLA_Anf_Aufschaltung_RVC 0 "Keine_RVC_Aufschalteanf" 1 "RVC_Aufschalteanforderung" ;
